VERSION "HINBNNNYYNNNYYNNNNNNNNNNNNYNNNYYYNNYNNNNNN/4//%%/4/'%**4NNN///"

NS_ :

BS_:

BU_: VirtualNMTMaster PVC BMS_Battery_1 TMS Inverter
VAL_TABLE_ PVC_Statusword 7 "FORWARD_DISABLE" 6 "CONT_CLOSE" 5 "CONT_OPEN" 4 "DISCHARGE" 3 "PRECHARGE" 2 "ESTOPWAIT" 1 "MC_ON" 0 "MC_OFF" ;

BO_ 1813 HBGuard_021: 1 BMS_Battery_1
 SG_ Toggle : 7|1@1+ (1,0) [0|0] "" Vector__XXX
 SG_ State : 0|7@1+ (1,0) [0|0] "" Vector__XXX

BO_ 1429 SSDO_021: 8 BMS_Battery_1
 SG_ SCS M : 5|3@1+ (1,0) [0|6] "" Vector__XXX

BO_ 1557 CSDO_021: 8 Vector__XXX
 SG_ CCS M : 5|3@1+ (1,0) [0|6] ""  BMS_Battery_1

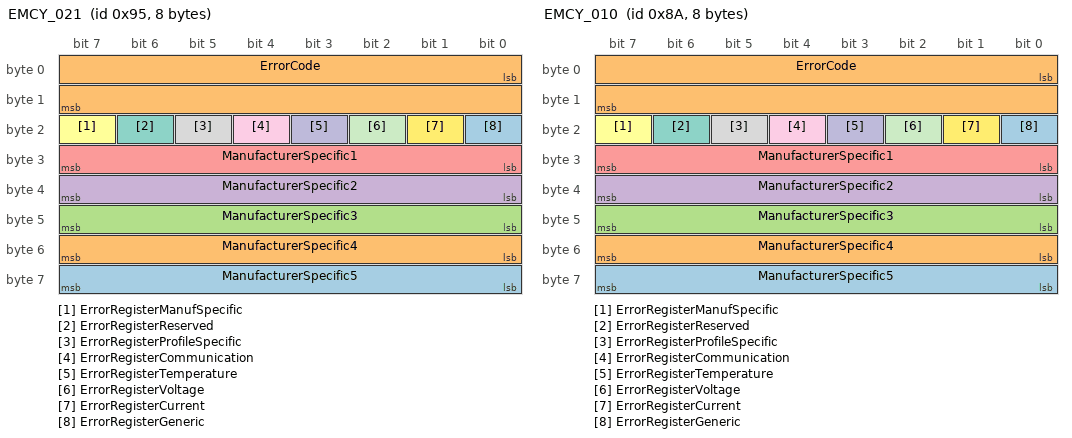
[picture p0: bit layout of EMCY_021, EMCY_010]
BO_ 149 EMCY_021: 8 BMS_Battery_1
 SG_ ManufacturerSpecific5 : 56|8@1+ (1,0) [0|0] "" Vector__XXX
 SG_ ManufacturerSpecific4 : 48|8@1+ (1,0) [0|0] "" Vector__XXX
 SG_ ManufacturerSpecific3 : 40|8@1+ (1,0) [0|0] "" Vector__XXX
 SG_ ManufacturerSpecific2 : 32|8@1+ (1,0) [0|0] "" Vector__XXX
 SG_ ManufacturerSpecific1 : 24|8@1+ (1,0) [0|0] "" Vector__XXX
 SG_ ErrorRegisterManufSpecific : 23|1@1+ (1,0) [0|0] "" Vector__XXX
 SG_ ErrorRegisterReserved : 22|1@1+ (1,0) [0|0] "" Vector__XXX
 SG_ ErrorRegisterProfileSpecific : 21|1@1+ (1,0) [0|0] "" Vector__XXX
 SG_ ErrorRegisterCommunication : 20|1@1+ (1,0) [0|0] "" Vector__XXX
 SG_ ErrorRegisterTemperature : 19|1@1+ (1,0) [0|0] "" Vector__XXX
 SG_ ErrorRegisterVoltage : 18|1@1+ (1,0) [0|0] "" Vector__XXX
 SG_ ErrorRegisterCurrent : 17|1@1+ (1,0) [0|0] "" Vector__XXX
 SG_ ErrorRegisterGeneric : 16|1@1+ (1,0) [0|0] "" Vector__XXX
 SG_ ErrorCode : 0|16@1+ (1,0) [0|0] "" Vector__XXX

BO_ 1802 HBGuard_010: 1 PVC
 SG_ Toggle : 7|1@1+ (1,0) [0|0] "" Vector__XXX
 SG_ State : 0|7@1+ (1,0) [0|0] "" Vector__XXX

BO_ 1418 SSDO_010: 8 PVC
 SG_ SCS M : 5|3@1+ (1,0) [0|6] "" Vector__XXX

BO_ 1546 CSDO_010: 8 Vector__XXX
 SG_ CCS M : 5|3@1+ (1,0) [0|6] ""  PVC

BO_ 138 EMCY_010: 8 PVC
 SG_ ManufacturerSpecific5 : 56|8@1+ (1,0) [0|0] "" Vector__XXX
 SG_ ManufacturerSpecific4 : 48|8@1+ (1,0) [0|0] "" Vector__XXX
 SG_ ManufacturerSpecific3 : 40|8@1+ (1,0) [0|0] "" Vector__XXX
 SG_ ManufacturerSpecific2 : 32|8@1+ (1,0) [0|0] "" Vector__XXX
 SG_ ManufacturerSpecific1 : 24|8@1+ (1,0) [0|0] "" Vector__XXX
 SG_ ErrorRegisterManufSpecific : 23|1@1+ (1,0) [0|0] "" Vector__XXX
 SG_ ErrorRegisterReserved : 22|1@1+ (1,0) [0|0] "" Vector__XXX
 SG_ ErrorRegisterProfileSpecific : 21|1@1+ (1,0) [0|0] "" Vector__XXX
 SG_ ErrorRegisterCommunication : 20|1@1+ (1,0) [0|0] "" Vector__XXX
 SG_ ErrorRegisterTemperature : 19|1@1+ (1,0) [0|0] "" Vector__XXX
 SG_ ErrorRegisterVoltage : 18|1@1+ (1,0) [0|0] "" Vector__XXX
 SG_ ErrorRegisterCurrent : 17|1@1+ (1,0) [0|0] "" Vector__XXX
 SG_ ErrorRegisterGeneric : 16|1@1+ (1,0) [0|0] "" Vector__XXX
 SG_ ErrorCode : 0|16@1+ (1,0) [0|0] "" Vector__XXX

BO_ 1800 HBGuard_008: 1 TMS
 SG_ Toggle : 7|1@1+ (1,0) [0|0] "" Vector__XXX
 SG_ State : 0|7@1+ (1,0) [0|0] "" Vector__XXX

BO_ 1416 SSDO_008: 8 TMS
 SG_ SCS M : 5|3@1+ (1,0) [0|6] "" Vector__XXX

BO_ 1544 CSDO_008: 8 Vector__XXX
 SG_ CCS M : 5|3@1+ (1,0) [0|6] ""  TMS

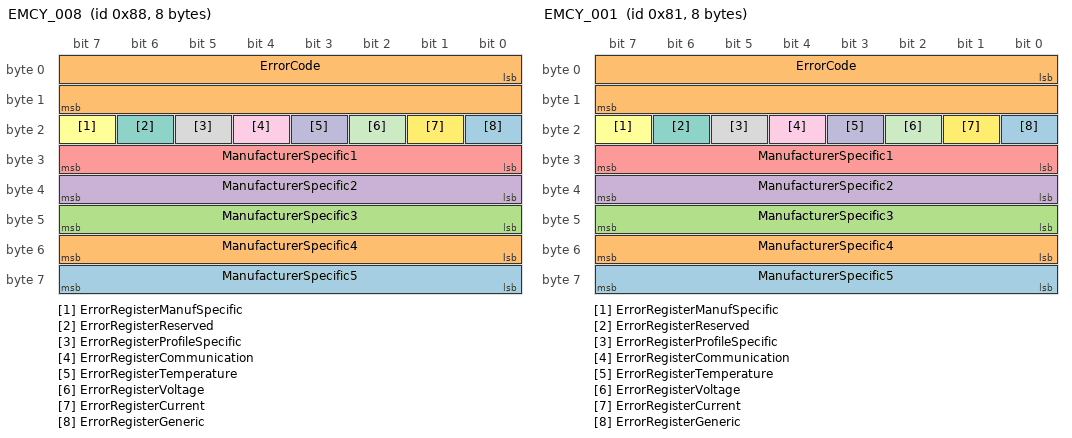
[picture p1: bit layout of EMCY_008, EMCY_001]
BO_ 136 EMCY_008: 8 TMS
 SG_ ManufacturerSpecific5 : 56|8@1+ (1,0) [0|0] "" Vector__XXX
 SG_ ManufacturerSpecific4 : 48|8@1+ (1,0) [0|0] "" Vector__XXX
 SG_ ManufacturerSpecific3 : 40|8@1+ (1,0) [0|0] "" Vector__XXX
 SG_ ManufacturerSpecific2 : 32|8@1+ (1,0) [0|0] "" Vector__XXX
 SG_ ManufacturerSpecific1 : 24|8@1+ (1,0) [0|0] "" Vector__XXX
 SG_ ErrorRegisterManufSpecific : 23|1@1+ (1,0) [0|0] "" Vector__XXX
 SG_ ErrorRegisterReserved : 22|1@1+ (1,0) [0|0] "" Vector__XXX
 SG_ ErrorRegisterProfileSpecific : 21|1@1+ (1,0) [0|0] "" Vector__XXX
 SG_ ErrorRegisterCommunication : 20|1@1+ (1,0) [0|0] "" Vector__XXX
 SG_ ErrorRegisterTemperature : 19|1@1+ (1,0) [0|0] "" Vector__XXX
 SG_ ErrorRegisterVoltage : 18|1@1+ (1,0) [0|0] "" Vector__XXX
 SG_ ErrorRegisterCurrent : 17|1@1+ (1,0) [0|0] "" Vector__XXX
 SG_ ErrorRegisterGeneric : 16|1@1+ (1,0) [0|0] "" Vector__XXX
 SG_ ErrorCode : 0|16@1+ (1,0) [0|0] "" Vector__XXX

BO_ 1793 HBGuard_001: 1 Inverter
 SG_ Toggle : 7|1@1+ (1,0) [0|0] "" Vector__XXX
 SG_ State : 0|7@1+ (1,0) [0|0] "" Vector__XXX

BO_ 1409 SSDO_001: 8 Inverter
 SG_ SCS M : 5|3@1+ (1,0) [0|6] "" Vector__XXX

BO_ 1537 CSDO_001: 8 Vector__XXX
 SG_ CCS M : 5|3@1+ (1,0) [0|6] ""  Inverter

BO_ 129 EMCY_001: 8 Inverter
 SG_ ManufacturerSpecific5 : 56|8@1+ (1,0) [0|0] "" Vector__XXX
 SG_ ManufacturerSpecific4 : 48|8@1+ (1,0) [0|0] "" Vector__XXX
 SG_ ManufacturerSpecific3 : 40|8@1+ (1,0) [0|0] "" Vector__XXX
 SG_ ManufacturerSpecific2 : 32|8@1+ (1,0) [0|0] "" Vector__XXX
 SG_ ManufacturerSpecific1 : 24|8@1+ (1,0) [0|0] "" Vector__XXX
 SG_ ErrorRegisterManufSpecific : 23|1@1+ (1,0) [0|0] "" Vector__XXX
 SG_ ErrorRegisterReserved : 22|1@1+ (1,0) [0|0] "" Vector__XXX
 SG_ ErrorRegisterProfileSpecific : 21|1@1+ (1,0) [0|0] "" Vector__XXX
 SG_ ErrorRegisterCommunication : 20|1@1+ (1,0) [0|0] "" Vector__XXX
 SG_ ErrorRegisterTemperature : 19|1@1+ (1,0) [0|0] "" Vector__XXX
 SG_ ErrorRegisterVoltage : 18|1@1+ (1,0) [0|0] "" Vector__XXX
 SG_ ErrorRegisterCurrent : 17|1@1+ (1,0) [0|0] "" Vector__XXX
 SG_ ErrorRegisterGeneric : 16|1@1+ (1,0) [0|0] "" Vector__XXX
 SG_ ErrorCode : 0|16@1+ (1,0) [0|0] "" Vector__XXX

BO_ 1919 HBGuard_127: 1 Vector__XXX
 SG_ Toggle : 7|1@1+ (1,0) [0|0] "" Vector__XXX
 SG_ State : 0|7@1+ (1,0) [0|0] "" Vector__XXX

BO_ 1535 SSDO_127: 8 Vector__XXX

BO_ 1663 CSDO_127: 8 Vector__XXX

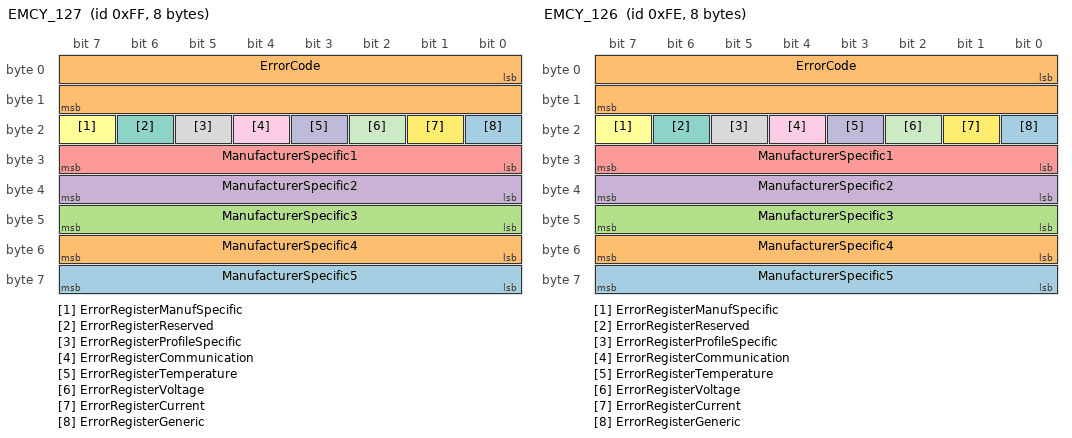
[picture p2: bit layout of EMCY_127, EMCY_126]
BO_ 255 EMCY_127: 8 Vector__XXX
 SG_ ManufacturerSpecific5 : 56|8@1+ (1,0) [0|0] "" Vector__XXX
 SG_ ManufacturerSpecific4 : 48|8@1+ (1,0) [0|0] "" Vector__XXX
 SG_ ManufacturerSpecific3 : 40|8@1+ (1,0) [0|0] "" Vector__XXX
 SG_ ManufacturerSpecific2 : 32|8@1+ (1,0) [0|0] "" Vector__XXX
 SG_ ManufacturerSpecific1 : 24|8@1+ (1,0) [0|0] "" Vector__XXX
 SG_ ErrorRegisterManufSpecific : 23|1@1+ (1,0) [0|0] "" Vector__XXX
 SG_ ErrorRegisterReserved : 22|1@1+ (1,0) [0|0] "" Vector__XXX
 SG_ ErrorRegisterProfileSpecific : 21|1@1+ (1,0) [0|0] "" Vector__XXX
 SG_ ErrorRegisterCommunication : 20|1@1+ (1,0) [0|0] "" Vector__XXX
 SG_ ErrorRegisterTemperature : 19|1@1+ (1,0) [0|0] "" Vector__XXX
 SG_ ErrorRegisterVoltage : 18|1@1+ (1,0) [0|0] "" Vector__XXX
 SG_ ErrorRegisterCurrent : 17|1@1+ (1,0) [0|0] "" Vector__XXX
 SG_ ErrorRegisterGeneric : 16|1@1+ (1,0) [0|0] "" Vector__XXX
 SG_ ErrorCode : 0|16@1+ (1,0) [0|0] "" Vector__XXX

BO_ 1918 HBGuard_126: 1 Vector__XXX
 SG_ Toggle : 7|1@1+ (1,0) [0|0] "" Vector__XXX
 SG_ State : 0|7@1+ (1,0) [0|0] "" Vector__XXX

BO_ 1534 SSDO_126: 8 Vector__XXX

BO_ 1662 CSDO_126: 8 Vector__XXX

BO_ 254 EMCY_126: 8 Vector__XXX
 SG_ ManufacturerSpecific5 : 56|8@1+ (1,0) [0|0] "" Vector__XXX
 SG_ ManufacturerSpecific4 : 48|8@1+ (1,0) [0|0] "" Vector__XXX
 SG_ ManufacturerSpecific3 : 40|8@1+ (1,0) [0|0] "" Vector__XXX
 SG_ ManufacturerSpecific2 : 32|8@1+ (1,0) [0|0] "" Vector__XXX
 SG_ ManufacturerSpecific1 : 24|8@1+ (1,0) [0|0] "" Vector__XXX
 SG_ ErrorRegisterManufSpecific : 23|1@1+ (1,0) [0|0] "" Vector__XXX
 SG_ ErrorRegisterReserved : 22|1@1+ (1,0) [0|0] "" Vector__XXX
 SG_ ErrorRegisterProfileSpecific : 21|1@1+ (1,0) [0|0] "" Vector__XXX
 SG_ ErrorRegisterCommunication : 20|1@1+ (1,0) [0|0] "" Vector__XXX
 SG_ ErrorRegisterTemperature : 19|1@1+ (1,0) [0|0] "" Vector__XXX
 SG_ ErrorRegisterVoltage : 18|1@1+ (1,0) [0|0] "" Vector__XXX
 SG_ ErrorRegisterCurrent : 17|1@1+ (1,0) [0|0] "" Vector__XXX
 SG_ ErrorRegisterGeneric : 16|1@1+ (1,0) [0|0] "" Vector__XXX
 SG_ ErrorCode : 0|16@1+ (1,0) [0|0] "" Vector__XXX

BO_ 1917 HBGuard_125: 1 Vector__XXX
 SG_ Toggle : 7|1@1+ (1,0) [0|0] "" Vector__XXX
 SG_ State : 0|7@1+ (1,0) [0|0] "" Vector__XXX

BO_ 1533 SSDO_125: 8 Vector__XXX

BO_ 1661 CSDO_125: 8 Vector__XXX

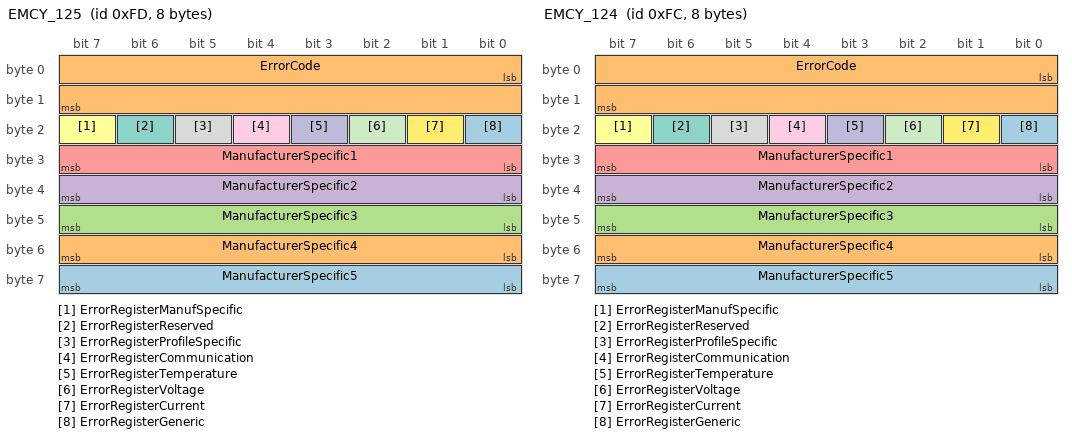
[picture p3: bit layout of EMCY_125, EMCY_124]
BO_ 253 EMCY_125: 8 Vector__XXX
 SG_ ManufacturerSpecific5 : 56|8@1+ (1,0) [0|0] "" Vector__XXX
 SG_ ManufacturerSpecific4 : 48|8@1+ (1,0) [0|0] "" Vector__XXX
 SG_ ManufacturerSpecific3 : 40|8@1+ (1,0) [0|0] "" Vector__XXX
 SG_ ManufacturerSpecific2 : 32|8@1+ (1,0) [0|0] "" Vector__XXX
 SG_ ManufacturerSpecific1 : 24|8@1+ (1,0) [0|0] "" Vector__XXX
 SG_ ErrorRegisterManufSpecific : 23|1@1+ (1,0) [0|0] "" Vector__XXX
 SG_ ErrorRegisterReserved : 22|1@1+ (1,0) [0|0] "" Vector__XXX
 SG_ ErrorRegisterProfileSpecific : 21|1@1+ (1,0) [0|0] "" Vector__XXX
 SG_ ErrorRegisterCommunication : 20|1@1+ (1,0) [0|0] "" Vector__XXX
 SG_ ErrorRegisterTemperature : 19|1@1+ (1,0) [0|0] "" Vector__XXX
 SG_ ErrorRegisterVoltage : 18|1@1+ (1,0) [0|0] "" Vector__XXX
 SG_ ErrorRegisterCurrent : 17|1@1+ (1,0) [0|0] "" Vector__XXX
 SG_ ErrorRegisterGeneric : 16|1@1+ (1,0) [0|0] "" Vector__XXX
 SG_ ErrorCode : 0|16@1+ (1,0) [0|0] "" Vector__XXX

BO_ 1916 HBGuard_124: 1 Vector__XXX
 SG_ Toggle : 7|1@1+ (1,0) [0|0] "" Vector__XXX
 SG_ State : 0|7@1+ (1,0) [0|0] "" Vector__XXX

BO_ 1532 SSDO_124: 8 Vector__XXX

BO_ 1660 CSDO_124: 8 Vector__XXX

BO_ 252 EMCY_124: 8 Vector__XXX
 SG_ ManufacturerSpecific5 : 56|8@1+ (1,0) [0|0] "" Vector__XXX
 SG_ ManufacturerSpecific4 : 48|8@1+ (1,0) [0|0] "" Vector__XXX
 SG_ ManufacturerSpecific3 : 40|8@1+ (1,0) [0|0] "" Vector__XXX
 SG_ ManufacturerSpecific2 : 32|8@1+ (1,0) [0|0] "" Vector__XXX
 SG_ ManufacturerSpecific1 : 24|8@1+ (1,0) [0|0] "" Vector__XXX
 SG_ ErrorRegisterManufSpecific : 23|1@1+ (1,0) [0|0] "" Vector__XXX
 SG_ ErrorRegisterReserved : 22|1@1+ (1,0) [0|0] "" Vector__XXX
 SG_ ErrorRegisterProfileSpecific : 21|1@1+ (1,0) [0|0] "" Vector__XXX
 SG_ ErrorRegisterCommunication : 20|1@1+ (1,0) [0|0] "" Vector__XXX
 SG_ ErrorRegisterTemperature : 19|1@1+ (1,0) [0|0] "" Vector__XXX
 SG_ ErrorRegisterVoltage : 18|1@1+ (1,0) [0|0] "" Vector__XXX
 SG_ ErrorRegisterCurrent : 17|1@1+ (1,0) [0|0] "" Vector__XXX
 SG_ ErrorRegisterGeneric : 16|1@1+ (1,0) [0|0] "" Vector__XXX
 SG_ ErrorCode : 0|16@1+ (1,0) [0|0] "" Vector__XXX

BO_ 1915 HBGuard_123: 1 Vector__XXX
 SG_ Toggle : 7|1@1+ (1,0) [0|0] "" Vector__XXX
 SG_ State : 0|7@1+ (1,0) [0|0] "" Vector__XXX

BO_ 1531 SSDO_123: 8 Vector__XXX

BO_ 1659 CSDO_123: 8 Vector__XXX

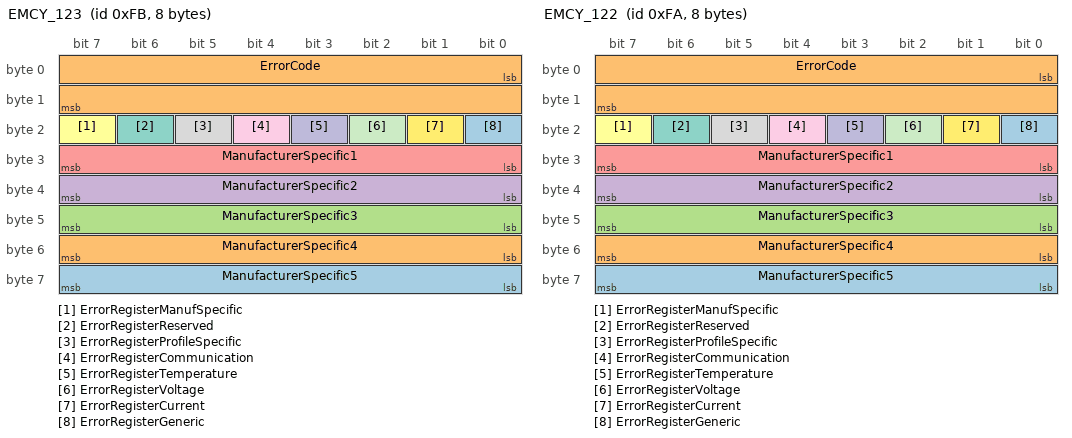
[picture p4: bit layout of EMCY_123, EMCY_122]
BO_ 251 EMCY_123: 8 Vector__XXX
 SG_ ManufacturerSpecific5 : 56|8@1+ (1,0) [0|0] "" Vector__XXX
 SG_ ManufacturerSpecific4 : 48|8@1+ (1,0) [0|0] "" Vector__XXX
 SG_ ManufacturerSpecific3 : 40|8@1+ (1,0) [0|0] "" Vector__XXX
 SG_ ManufacturerSpecific2 : 32|8@1+ (1,0) [0|0] "" Vector__XXX
 SG_ ManufacturerSpecific1 : 24|8@1+ (1,0) [0|0] "" Vector__XXX
 SG_ ErrorRegisterManufSpecific : 23|1@1+ (1,0) [0|0] "" Vector__XXX
 SG_ ErrorRegisterReserved : 22|1@1+ (1,0) [0|0] "" Vector__XXX
 SG_ ErrorRegisterProfileSpecific : 21|1@1+ (1,0) [0|0] "" Vector__XXX
 SG_ ErrorRegisterCommunication : 20|1@1+ (1,0) [0|0] "" Vector__XXX
 SG_ ErrorRegisterTemperature : 19|1@1+ (1,0) [0|0] "" Vector__XXX
 SG_ ErrorRegisterVoltage : 18|1@1+ (1,0) [0|0] "" Vector__XXX
 SG_ ErrorRegisterCurrent : 17|1@1+ (1,0) [0|0] "" Vector__XXX
 SG_ ErrorRegisterGeneric : 16|1@1+ (1,0) [0|0] "" Vector__XXX
 SG_ ErrorCode : 0|16@1+ (1,0) [0|0] "" Vector__XXX

BO_ 1914 HBGuard_122: 1 Vector__XXX
 SG_ Toggle : 7|1@1+ (1,0) [0|0] "" Vector__XXX
 SG_ State : 0|7@1+ (1,0) [0|0] "" Vector__XXX

BO_ 1530 SSDO_122: 8 Vector__XXX

BO_ 1658 CSDO_122: 8 Vector__XXX

BO_ 250 EMCY_122: 8 Vector__XXX
 SG_ ManufacturerSpecific5 : 56|8@1+ (1,0) [0|0] "" Vector__XXX
 SG_ ManufacturerSpecific4 : 48|8@1+ (1,0) [0|0] "" Vector__XXX
 SG_ ManufacturerSpecific3 : 40|8@1+ (1,0) [0|0] "" Vector__XXX
 SG_ ManufacturerSpecific2 : 32|8@1+ (1,0) [0|0] "" Vector__XXX
 SG_ ManufacturerSpecific1 : 24|8@1+ (1,0) [0|0] "" Vector__XXX
 SG_ ErrorRegisterManufSpecific : 23|1@1+ (1,0) [0|0] "" Vector__XXX
 SG_ ErrorRegisterReserved : 22|1@1+ (1,0) [0|0] "" Vector__XXX
 SG_ ErrorRegisterProfileSpecific : 21|1@1+ (1,0) [0|0] "" Vector__XXX
 SG_ ErrorRegisterCommunication : 20|1@1+ (1,0) [0|0] "" Vector__XXX
 SG_ ErrorRegisterTemperature : 19|1@1+ (1,0) [0|0] "" Vector__XXX
 SG_ ErrorRegisterVoltage : 18|1@1+ (1,0) [0|0] "" Vector__XXX
 SG_ ErrorRegisterCurrent : 17|1@1+ (1,0) [0|0] "" Vector__XXX
 SG_ ErrorRegisterGeneric : 16|1@1+ (1,0) [0|0] "" Vector__XXX
 SG_ ErrorCode : 0|16@1+ (1,0) [0|0] "" Vector__XXX

BO_ 1913 HBGuard_121: 1 Vector__XXX
 SG_ Toggle : 7|1@1+ (1,0) [0|0] "" Vector__XXX
 SG_ State : 0|7@1+ (1,0) [0|0] "" Vector__XXX

BO_ 1529 SSDO_121: 8 Vector__XXX

BO_ 1657 CSDO_121: 8 Vector__XXX

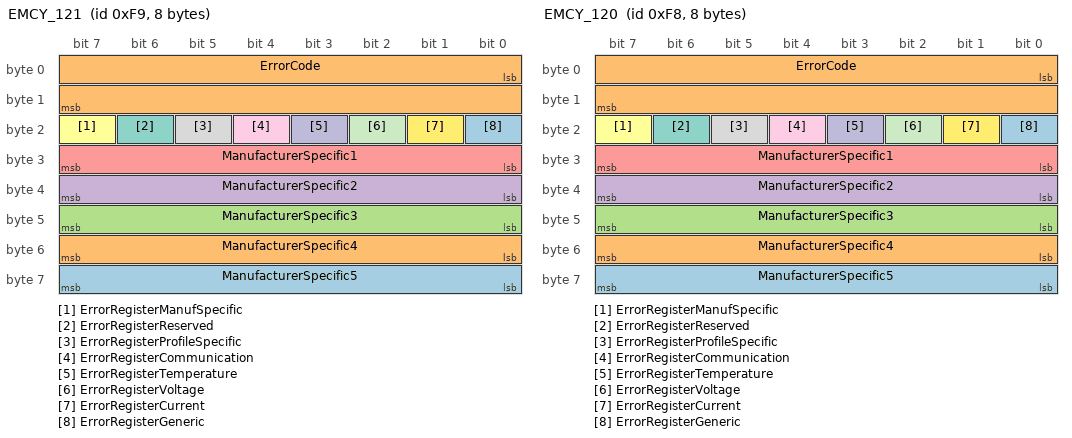
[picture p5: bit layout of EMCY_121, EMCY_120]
BO_ 249 EMCY_121: 8 Vector__XXX
 SG_ ManufacturerSpecific5 : 56|8@1+ (1,0) [0|0] "" Vector__XXX
 SG_ ManufacturerSpecific4 : 48|8@1+ (1,0) [0|0] "" Vector__XXX
 SG_ ManufacturerSpecific3 : 40|8@1+ (1,0) [0|0] "" Vector__XXX
 SG_ ManufacturerSpecific2 : 32|8@1+ (1,0) [0|0] "" Vector__XXX
 SG_ ManufacturerSpecific1 : 24|8@1+ (1,0) [0|0] "" Vector__XXX
 SG_ ErrorRegisterManufSpecific : 23|1@1+ (1,0) [0|0] "" Vector__XXX
 SG_ ErrorRegisterReserved : 22|1@1+ (1,0) [0|0] "" Vector__XXX
 SG_ ErrorRegisterProfileSpecific : 21|1@1+ (1,0) [0|0] "" Vector__XXX
 SG_ ErrorRegisterCommunication : 20|1@1+ (1,0) [0|0] "" Vector__XXX
 SG_ ErrorRegisterTemperature : 19|1@1+ (1,0) [0|0] "" Vector__XXX
 SG_ ErrorRegisterVoltage : 18|1@1+ (1,0) [0|0] "" Vector__XXX
 SG_ ErrorRegisterCurrent : 17|1@1+ (1,0) [0|0] "" Vector__XXX
 SG_ ErrorRegisterGeneric : 16|1@1+ (1,0) [0|0] "" Vector__XXX
 SG_ ErrorCode : 0|16@1+ (1,0) [0|0] "" Vector__XXX

BO_ 1912 HBGuard_120: 1 Vector__XXX
 SG_ Toggle : 7|1@1+ (1,0) [0|0] "" Vector__XXX
 SG_ State : 0|7@1+ (1,0) [0|0] "" Vector__XXX

BO_ 1528 SSDO_120: 8 Vector__XXX

BO_ 1656 CSDO_120: 8 Vector__XXX

BO_ 248 EMCY_120: 8 Vector__XXX
 SG_ ManufacturerSpecific5 : 56|8@1+ (1,0) [0|0] "" Vector__XXX
 SG_ ManufacturerSpecific4 : 48|8@1+ (1,0) [0|0] "" Vector__XXX
 SG_ ManufacturerSpecific3 : 40|8@1+ (1,0) [0|0] "" Vector__XXX
 SG_ ManufacturerSpecific2 : 32|8@1+ (1,0) [0|0] "" Vector__XXX
 SG_ ManufacturerSpecific1 : 24|8@1+ (1,0) [0|0] "" Vector__XXX
 SG_ ErrorRegisterManufSpecific : 23|1@1+ (1,0) [0|0] "" Vector__XXX
 SG_ ErrorRegisterReserved : 22|1@1+ (1,0) [0|0] "" Vector__XXX
 SG_ ErrorRegisterProfileSpecific : 21|1@1+ (1,0) [0|0] "" Vector__XXX
 SG_ ErrorRegisterCommunication : 20|1@1+ (1,0) [0|0] "" Vector__XXX
 SG_ ErrorRegisterTemperature : 19|1@1+ (1,0) [0|0] "" Vector__XXX
 SG_ ErrorRegisterVoltage : 18|1@1+ (1,0) [0|0] "" Vector__XXX
 SG_ ErrorRegisterCurrent : 17|1@1+ (1,0) [0|0] "" Vector__XXX
 SG_ ErrorRegisterGeneric : 16|1@1+ (1,0) [0|0] "" Vector__XXX
 SG_ ErrorCode : 0|16@1+ (1,0) [0|0] "" Vector__XXX

BO_ 1911 HBGuard_119: 1 Vector__XXX
 SG_ Toggle : 7|1@1+ (1,0) [0|0] "" Vector__XXX
 SG_ State : 0|7@1+ (1,0) [0|0] "" Vector__XXX

BO_ 1527 SSDO_119: 8 Vector__XXX

BO_ 1655 CSDO_119: 8 Vector__XXX

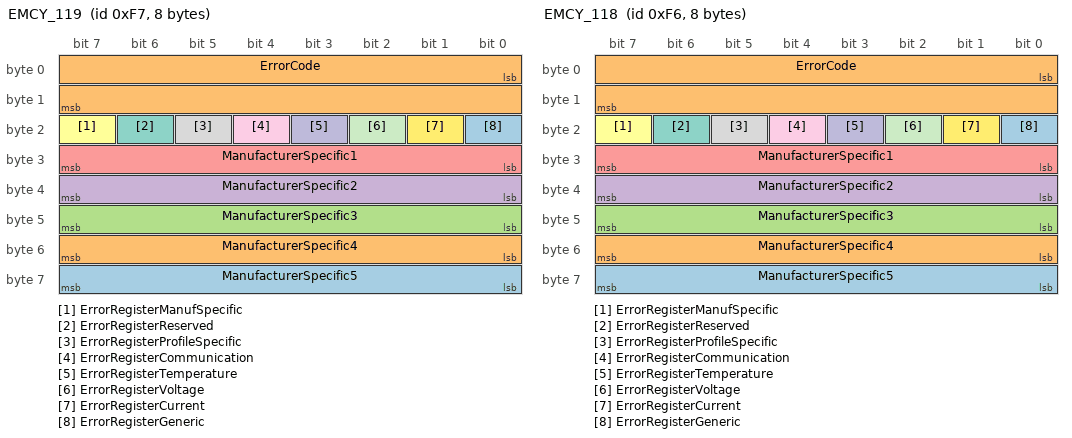
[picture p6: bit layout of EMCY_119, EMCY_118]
BO_ 247 EMCY_119: 8 Vector__XXX
 SG_ ManufacturerSpecific5 : 56|8@1+ (1,0) [0|0] "" Vector__XXX
 SG_ ManufacturerSpecific4 : 48|8@1+ (1,0) [0|0] "" Vector__XXX
 SG_ ManufacturerSpecific3 : 40|8@1+ (1,0) [0|0] "" Vector__XXX
 SG_ ManufacturerSpecific2 : 32|8@1+ (1,0) [0|0] "" Vector__XXX
 SG_ ManufacturerSpecific1 : 24|8@1+ (1,0) [0|0] "" Vector__XXX
 SG_ ErrorRegisterManufSpecific : 23|1@1+ (1,0) [0|0] "" Vector__XXX
 SG_ ErrorRegisterReserved : 22|1@1+ (1,0) [0|0] "" Vector__XXX
 SG_ ErrorRegisterProfileSpecific : 21|1@1+ (1,0) [0|0] "" Vector__XXX
 SG_ ErrorRegisterCommunication : 20|1@1+ (1,0) [0|0] "" Vector__XXX
 SG_ ErrorRegisterTemperature : 19|1@1+ (1,0) [0|0] "" Vector__XXX
 SG_ ErrorRegisterVoltage : 18|1@1+ (1,0) [0|0] "" Vector__XXX
 SG_ ErrorRegisterCurrent : 17|1@1+ (1,0) [0|0] "" Vector__XXX
 SG_ ErrorRegisterGeneric : 16|1@1+ (1,0) [0|0] "" Vector__XXX
 SG_ ErrorCode : 0|16@1+ (1,0) [0|0] "" Vector__XXX

BO_ 1910 HBGuard_118: 1 Vector__XXX
 SG_ Toggle : 7|1@1+ (1,0) [0|0] "" Vector__XXX
 SG_ State : 0|7@1+ (1,0) [0|0] "" Vector__XXX

BO_ 1526 SSDO_118: 8 Vector__XXX

BO_ 1654 CSDO_118: 8 Vector__XXX

BO_ 246 EMCY_118: 8 Vector__XXX
 SG_ ManufacturerSpecific5 : 56|8@1+ (1,0) [0|0] "" Vector__XXX
 SG_ ManufacturerSpecific4 : 48|8@1+ (1,0) [0|0] "" Vector__XXX
 SG_ ManufacturerSpecific3 : 40|8@1+ (1,0) [0|0] "" Vector__XXX
 SG_ ManufacturerSpecific2 : 32|8@1+ (1,0) [0|0] "" Vector__XXX
 SG_ ManufacturerSpecific1 : 24|8@1+ (1,0) [0|0] "" Vector__XXX
 SG_ ErrorRegisterManufSpecific : 23|1@1+ (1,0) [0|0] "" Vector__XXX
 SG_ ErrorRegisterReserved : 22|1@1+ (1,0) [0|0] "" Vector__XXX
 SG_ ErrorRegisterProfileSpecific : 21|1@1+ (1,0) [0|0] "" Vector__XXX
 SG_ ErrorRegisterCommunication : 20|1@1+ (1,0) [0|0] "" Vector__XXX
 SG_ ErrorRegisterTemperature : 19|1@1+ (1,0) [0|0] "" Vector__XXX
 SG_ ErrorRegisterVoltage : 18|1@1+ (1,0) [0|0] "" Vector__XXX
 SG_ ErrorRegisterCurrent : 17|1@1+ (1,0) [0|0] "" Vector__XXX
 SG_ ErrorRegisterGeneric : 16|1@1+ (1,0) [0|0] "" Vector__XXX
 SG_ ErrorCode : 0|16@1+ (1,0) [0|0] "" Vector__XXX

BO_ 1909 HBGuard_117: 1 Vector__XXX
 SG_ Toggle : 7|1@1+ (1,0) [0|0] "" Vector__XXX
 SG_ State : 0|7@1+ (1,0) [0|0] "" Vector__XXX

BO_ 1525 SSDO_117: 8 Vector__XXX

BO_ 1653 CSDO_117: 8 Vector__XXX

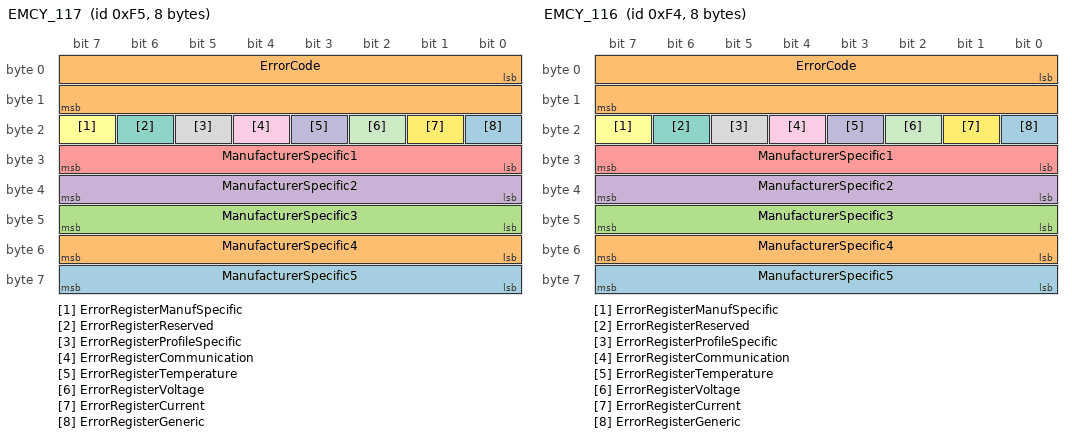
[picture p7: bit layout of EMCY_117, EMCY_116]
BO_ 245 EMCY_117: 8 Vector__XXX
 SG_ ManufacturerSpecific5 : 56|8@1+ (1,0) [0|0] "" Vector__XXX
 SG_ ManufacturerSpecific4 : 48|8@1+ (1,0) [0|0] "" Vector__XXX
 SG_ ManufacturerSpecific3 : 40|8@1+ (1,0) [0|0] "" Vector__XXX
 SG_ ManufacturerSpecific2 : 32|8@1+ (1,0) [0|0] "" Vector__XXX
 SG_ ManufacturerSpecific1 : 24|8@1+ (1,0) [0|0] "" Vector__XXX
 SG_ ErrorRegisterManufSpecific : 23|1@1+ (1,0) [0|0] "" Vector__XXX
 SG_ ErrorRegisterReserved : 22|1@1+ (1,0) [0|0] "" Vector__XXX
 SG_ ErrorRegisterProfileSpecific : 21|1@1+ (1,0) [0|0] "" Vector__XXX
 SG_ ErrorRegisterCommunication : 20|1@1+ (1,0) [0|0] "" Vector__XXX
 SG_ ErrorRegisterTemperature : 19|1@1+ (1,0) [0|0] "" Vector__XXX
 SG_ ErrorRegisterVoltage : 18|1@1+ (1,0) [0|0] "" Vector__XXX
 SG_ ErrorRegisterCurrent : 17|1@1+ (1,0) [0|0] "" Vector__XXX
 SG_ ErrorRegisterGeneric : 16|1@1+ (1,0) [0|0] "" Vector__XXX
 SG_ ErrorCode : 0|16@1+ (1,0) [0|0] "" Vector__XXX

BO_ 1908 HBGuard_116: 1 Vector__XXX
 SG_ Toggle : 7|1@1+ (1,0) [0|0] "" Vector__XXX
 SG_ State : 0|7@1+ (1,0) [0|0] "" Vector__XXX

BO_ 1524 SSDO_116: 8 Vector__XXX

BO_ 1652 CSDO_116: 8 Vector__XXX

BO_ 244 EMCY_116: 8 Vector__XXX
 SG_ ManufacturerSpecific5 : 56|8@1+ (1,0) [0|0] "" Vector__XXX
 SG_ ManufacturerSpecific4 : 48|8@1+ (1,0) [0|0] "" Vector__XXX
 SG_ ManufacturerSpecific3 : 40|8@1+ (1,0) [0|0] "" Vector__XXX
 SG_ ManufacturerSpecific2 : 32|8@1+ (1,0) [0|0] "" Vector__XXX
 SG_ ManufacturerSpecific1 : 24|8@1+ (1,0) [0|0] "" Vector__XXX
 SG_ ErrorRegisterManufSpecific : 23|1@1+ (1,0) [0|0] "" Vector__XXX
 SG_ ErrorRegisterReserved : 22|1@1+ (1,0) [0|0] "" Vector__XXX
 SG_ ErrorRegisterProfileSpecific : 21|1@1+ (1,0) [0|0] "" Vector__XXX
 SG_ ErrorRegisterCommunication : 20|1@1+ (1,0) [0|0] "" Vector__XXX
 SG_ ErrorRegisterTemperature : 19|1@1+ (1,0) [0|0] "" Vector__XXX
 SG_ ErrorRegisterVoltage : 18|1@1+ (1,0) [0|0] "" Vector__XXX
 SG_ ErrorRegisterCurrent : 17|1@1+ (1,0) [0|0] "" Vector__XXX
 SG_ ErrorRegisterGeneric : 16|1@1+ (1,0) [0|0] "" Vector__XXX
 SG_ ErrorCode : 0|16@1+ (1,0) [0|0] "" Vector__XXX

BO_ 1907 HBGuard_115: 1 Vector__XXX
 SG_ Toggle : 7|1@1+ (1,0) [0|0] "" Vector__XXX
 SG_ State : 0|7@1+ (1,0) [0|0] "" Vector__XXX

BO_ 1523 SSDO_115: 8 Vector__XXX

BO_ 1651 CSDO_115: 8 Vector__XXX

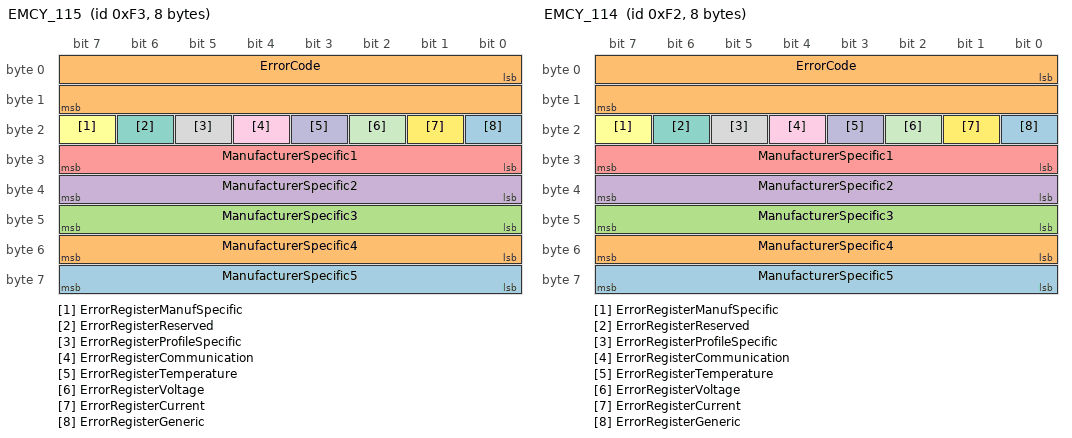
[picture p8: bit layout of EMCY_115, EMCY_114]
BO_ 243 EMCY_115: 8 Vector__XXX
 SG_ ManufacturerSpecific5 : 56|8@1+ (1,0) [0|0] "" Vector__XXX
 SG_ ManufacturerSpecific4 : 48|8@1+ (1,0) [0|0] "" Vector__XXX
 SG_ ManufacturerSpecific3 : 40|8@1+ (1,0) [0|0] "" Vector__XXX
 SG_ ManufacturerSpecific2 : 32|8@1+ (1,0) [0|0] "" Vector__XXX
 SG_ ManufacturerSpecific1 : 24|8@1+ (1,0) [0|0] "" Vector__XXX
 SG_ ErrorRegisterManufSpecific : 23|1@1+ (1,0) [0|0] "" Vector__XXX
 SG_ ErrorRegisterReserved : 22|1@1+ (1,0) [0|0] "" Vector__XXX
 SG_ ErrorRegisterProfileSpecific : 21|1@1+ (1,0) [0|0] "" Vector__XXX
 SG_ ErrorRegisterCommunication : 20|1@1+ (1,0) [0|0] "" Vector__XXX
 SG_ ErrorRegisterTemperature : 19|1@1+ (1,0) [0|0] "" Vector__XXX
 SG_ ErrorRegisterVoltage : 18|1@1+ (1,0) [0|0] "" Vector__XXX
 SG_ ErrorRegisterCurrent : 17|1@1+ (1,0) [0|0] "" Vector__XXX
 SG_ ErrorRegisterGeneric : 16|1@1+ (1,0) [0|0] "" Vector__XXX
 SG_ ErrorCode : 0|16@1+ (1,0) [0|0] "" Vector__XXX

BO_ 1906 HBGuard_114: 1 Vector__XXX
 SG_ Toggle : 7|1@1+ (1,0) [0|0] "" Vector__XXX
 SG_ State : 0|7@1+ (1,0) [0|0] "" Vector__XXX

BO_ 1522 SSDO_114: 8 Vector__XXX

BO_ 1650 CSDO_114: 8 Vector__XXX

BO_ 242 EMCY_114: 8 Vector__XXX
 SG_ ManufacturerSpecific5 : 56|8@1+ (1,0) [0|0] "" Vector__XXX
 SG_ ManufacturerSpecific4 : 48|8@1+ (1,0) [0|0] "" Vector__XXX
 SG_ ManufacturerSpecific3 : 40|8@1+ (1,0) [0|0] "" Vector__XXX
 SG_ ManufacturerSpecific2 : 32|8@1+ (1,0) [0|0] "" Vector__XXX
 SG_ ManufacturerSpecific1 : 24|8@1+ (1,0) [0|0] "" Vector__XXX
 SG_ ErrorRegisterManufSpecific : 23|1@1+ (1,0) [0|0] "" Vector__XXX
 SG_ ErrorRegisterReserved : 22|1@1+ (1,0) [0|0] "" Vector__XXX
 SG_ ErrorRegisterProfileSpecific : 21|1@1+ (1,0) [0|0] "" Vector__XXX
 SG_ ErrorRegisterCommunication : 20|1@1+ (1,0) [0|0] "" Vector__XXX
 SG_ ErrorRegisterTemperature : 19|1@1+ (1,0) [0|0] "" Vector__XXX
 SG_ ErrorRegisterVoltage : 18|1@1+ (1,0) [0|0] "" Vector__XXX
 SG_ ErrorRegisterCurrent : 17|1@1+ (1,0) [0|0] "" Vector__XXX
 SG_ ErrorRegisterGeneric : 16|1@1+ (1,0) [0|0] "" Vector__XXX
 SG_ ErrorCode : 0|16@1+ (1,0) [0|0] "" Vector__XXX

BO_ 1905 HBGuard_113: 1 Vector__XXX
 SG_ Toggle : 7|1@1+ (1,0) [0|0] "" Vector__XXX
 SG_ State : 0|7@1+ (1,0) [0|0] "" Vector__XXX

BO_ 1521 SSDO_113: 8 Vector__XXX

BO_ 1649 CSDO_113: 8 Vector__XXX

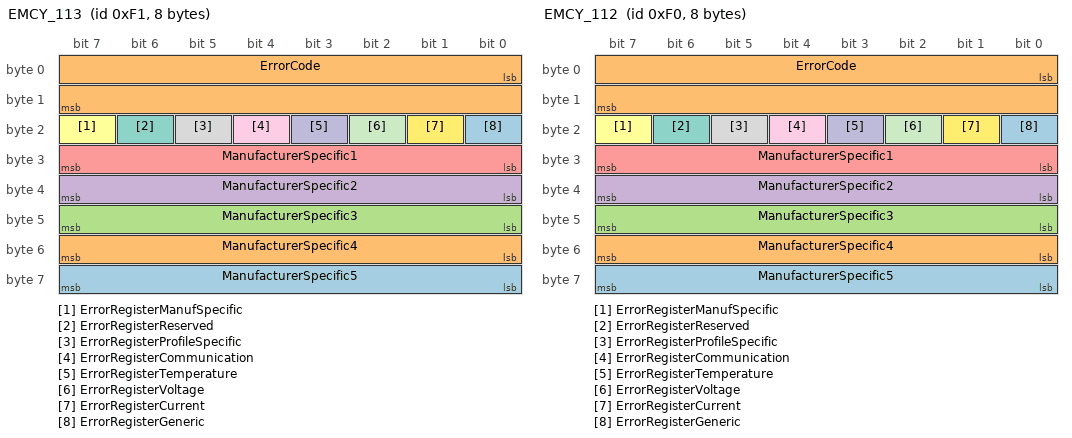
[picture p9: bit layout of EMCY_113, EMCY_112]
BO_ 241 EMCY_113: 8 Vector__XXX
 SG_ ManufacturerSpecific5 : 56|8@1+ (1,0) [0|0] "" Vector__XXX
 SG_ ManufacturerSpecific4 : 48|8@1+ (1,0) [0|0] "" Vector__XXX
 SG_ ManufacturerSpecific3 : 40|8@1+ (1,0) [0|0] "" Vector__XXX
 SG_ ManufacturerSpecific2 : 32|8@1+ (1,0) [0|0] "" Vector__XXX
 SG_ ManufacturerSpecific1 : 24|8@1+ (1,0) [0|0] "" Vector__XXX
 SG_ ErrorRegisterManufSpecific : 23|1@1+ (1,0) [0|0] "" Vector__XXX
 SG_ ErrorRegisterReserved : 22|1@1+ (1,0) [0|0] "" Vector__XXX
 SG_ ErrorRegisterProfileSpecific : 21|1@1+ (1,0) [0|0] "" Vector__XXX
 SG_ ErrorRegisterCommunication : 20|1@1+ (1,0) [0|0] "" Vector__XXX
 SG_ ErrorRegisterTemperature : 19|1@1+ (1,0) [0|0] "" Vector__XXX
 SG_ ErrorRegisterVoltage : 18|1@1+ (1,0) [0|0] "" Vector__XXX
 SG_ ErrorRegisterCurrent : 17|1@1+ (1,0) [0|0] "" Vector__XXX
 SG_ ErrorRegisterGeneric : 16|1@1+ (1,0) [0|0] "" Vector__XXX
 SG_ ErrorCode : 0|16@1+ (1,0) [0|0] "" Vector__XXX

BO_ 1904 HBGuard_112: 1 Vector__XXX
 SG_ Toggle : 7|1@1+ (1,0) [0|0] "" Vector__XXX
 SG_ State : 0|7@1+ (1,0) [0|0] "" Vector__XXX

BO_ 1520 SSDO_112: 8 Vector__XXX

BO_ 1648 CSDO_112: 8 Vector__XXX

BO_ 240 EMCY_112: 8 Vector__XXX
 SG_ ManufacturerSpecific5 : 56|8@1+ (1,0) [0|0] "" Vector__XXX
 SG_ ManufacturerSpecific4 : 48|8@1+ (1,0) [0|0] "" Vector__XXX
 SG_ ManufacturerSpecific3 : 40|8@1+ (1,0) [0|0] "" Vector__XXX
 SG_ ManufacturerSpecific2 : 32|8@1+ (1,0) [0|0] "" Vector__XXX
 SG_ ManufacturerSpecific1 : 24|8@1+ (1,0) [0|0] "" Vector__XXX
 SG_ ErrorRegisterManufSpecific : 23|1@1+ (1,0) [0|0] "" Vector__XXX
 SG_ ErrorRegisterReserved : 22|1@1+ (1,0) [0|0] "" Vector__XXX
 SG_ ErrorRegisterProfileSpecific : 21|1@1+ (1,0) [0|0] "" Vector__XXX
 SG_ ErrorRegisterCommunication : 20|1@1+ (1,0) [0|0] "" Vector__XXX
 SG_ ErrorRegisterTemperature : 19|1@1+ (1,0) [0|0] "" Vector__XXX
 SG_ ErrorRegisterVoltage : 18|1@1+ (1,0) [0|0] "" Vector__XXX
 SG_ ErrorRegisterCurrent : 17|1@1+ (1,0) [0|0] "" Vector__XXX
 SG_ ErrorRegisterGeneric : 16|1@1+ (1,0) [0|0] "" Vector__XXX
 SG_ ErrorCode : 0|16@1+ (1,0) [0|0] "" Vector__XXX

BO_ 1903 HBGuard_111: 1 Vector__XXX
 SG_ Toggle : 7|1@1+ (1,0) [0|0] "" Vector__XXX
 SG_ State : 0|7@1+ (1,0) [0|0] "" Vector__XXX

BO_ 1519 SSDO_111: 8 Vector__XXX

BO_ 1647 CSDO_111: 8 Vector__XXX

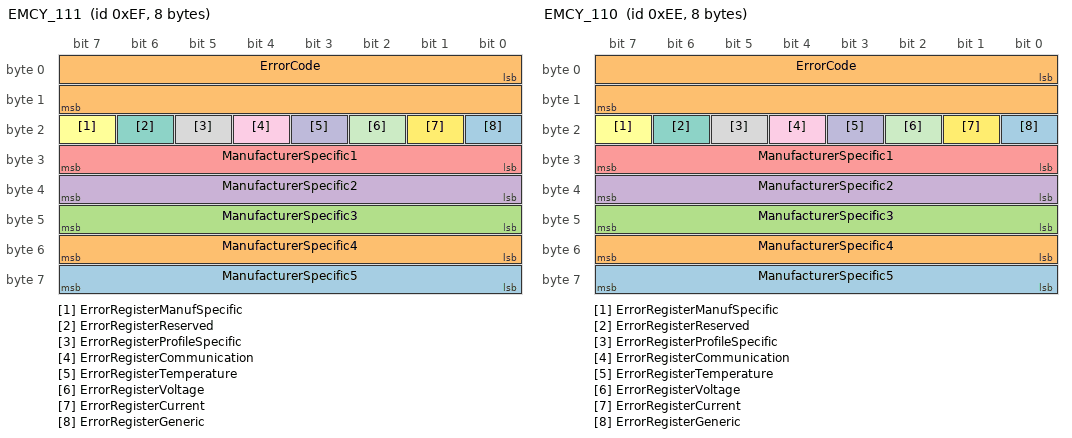
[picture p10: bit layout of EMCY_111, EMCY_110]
BO_ 239 EMCY_111: 8 Vector__XXX
 SG_ ManufacturerSpecific5 : 56|8@1+ (1,0) [0|0] "" Vector__XXX
 SG_ ManufacturerSpecific4 : 48|8@1+ (1,0) [0|0] "" Vector__XXX
 SG_ ManufacturerSpecific3 : 40|8@1+ (1,0) [0|0] "" Vector__XXX
 SG_ ManufacturerSpecific2 : 32|8@1+ (1,0) [0|0] "" Vector__XXX
 SG_ ManufacturerSpecific1 : 24|8@1+ (1,0) [0|0] "" Vector__XXX
 SG_ ErrorRegisterManufSpecific : 23|1@1+ (1,0) [0|0] "" Vector__XXX
 SG_ ErrorRegisterReserved : 22|1@1+ (1,0) [0|0] "" Vector__XXX
 SG_ ErrorRegisterProfileSpecific : 21|1@1+ (1,0) [0|0] "" Vector__XXX
 SG_ ErrorRegisterCommunication : 20|1@1+ (1,0) [0|0] "" Vector__XXX
 SG_ ErrorRegisterTemperature : 19|1@1+ (1,0) [0|0] "" Vector__XXX
 SG_ ErrorRegisterVoltage : 18|1@1+ (1,0) [0|0] "" Vector__XXX
 SG_ ErrorRegisterCurrent : 17|1@1+ (1,0) [0|0] "" Vector__XXX
 SG_ ErrorRegisterGeneric : 16|1@1+ (1,0) [0|0] "" Vector__XXX
 SG_ ErrorCode : 0|16@1+ (1,0) [0|0] "" Vector__XXX

BO_ 1902 HBGuard_110: 1 Vector__XXX
 SG_ Toggle : 7|1@1+ (1,0) [0|0] "" Vector__XXX
 SG_ State : 0|7@1+ (1,0) [0|0] "" Vector__XXX

BO_ 1518 SSDO_110: 8 Vector__XXX

BO_ 1646 CSDO_110: 8 Vector__XXX

BO_ 238 EMCY_110: 8 Vector__XXX
 SG_ ManufacturerSpecific5 : 56|8@1+ (1,0) [0|0] "" Vector__XXX
 SG_ ManufacturerSpecific4 : 48|8@1+ (1,0) [0|0] "" Vector__XXX
 SG_ ManufacturerSpecific3 : 40|8@1+ (1,0) [0|0] "" Vector__XXX
 SG_ ManufacturerSpecific2 : 32|8@1+ (1,0) [0|0] "" Vector__XXX
 SG_ ManufacturerSpecific1 : 24|8@1+ (1,0) [0|0] "" Vector__XXX
 SG_ ErrorRegisterManufSpecific : 23|1@1+ (1,0) [0|0] "" Vector__XXX
 SG_ ErrorRegisterReserved : 22|1@1+ (1,0) [0|0] "" Vector__XXX
 SG_ ErrorRegisterProfileSpecific : 21|1@1+ (1,0) [0|0] "" Vector__XXX
 SG_ ErrorRegisterCommunication : 20|1@1+ (1,0) [0|0] "" Vector__XXX
 SG_ ErrorRegisterTemperature : 19|1@1+ (1,0) [0|0] "" Vector__XXX
 SG_ ErrorRegisterVoltage : 18|1@1+ (1,0) [0|0] "" Vector__XXX
 SG_ ErrorRegisterCurrent : 17|1@1+ (1,0) [0|0] "" Vector__XXX
 SG_ ErrorRegisterGeneric : 16|1@1+ (1,0) [0|0] "" Vector__XXX
 SG_ ErrorCode : 0|16@1+ (1,0) [0|0] "" Vector__XXX

BO_ 1901 HBGuard_109: 1 Vector__XXX
 SG_ Toggle : 7|1@1+ (1,0) [0|0] "" Vector__XXX
 SG_ State : 0|7@1+ (1,0) [0|0] "" Vector__XXX

BO_ 1517 SSDO_109: 8 Vector__XXX

BO_ 1645 CSDO_109: 8 Vector__XXX

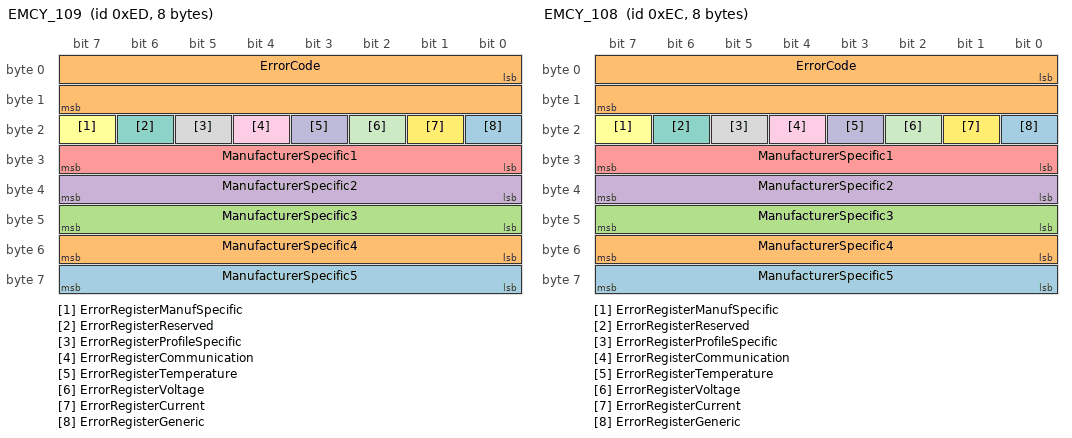
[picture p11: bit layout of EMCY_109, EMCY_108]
BO_ 237 EMCY_109: 8 Vector__XXX
 SG_ ManufacturerSpecific5 : 56|8@1+ (1,0) [0|0] "" Vector__XXX
 SG_ ManufacturerSpecific4 : 48|8@1+ (1,0) [0|0] "" Vector__XXX
 SG_ ManufacturerSpecific3 : 40|8@1+ (1,0) [0|0] "" Vector__XXX
 SG_ ManufacturerSpecific2 : 32|8@1+ (1,0) [0|0] "" Vector__XXX
 SG_ ManufacturerSpecific1 : 24|8@1+ (1,0) [0|0] "" Vector__XXX
 SG_ ErrorRegisterManufSpecific : 23|1@1+ (1,0) [0|0] "" Vector__XXX
 SG_ ErrorRegisterReserved : 22|1@1+ (1,0) [0|0] "" Vector__XXX
 SG_ ErrorRegisterProfileSpecific : 21|1@1+ (1,0) [0|0] "" Vector__XXX
 SG_ ErrorRegisterCommunication : 20|1@1+ (1,0) [0|0] "" Vector__XXX
 SG_ ErrorRegisterTemperature : 19|1@1+ (1,0) [0|0] "" Vector__XXX
 SG_ ErrorRegisterVoltage : 18|1@1+ (1,0) [0|0] "" Vector__XXX
 SG_ ErrorRegisterCurrent : 17|1@1+ (1,0) [0|0] "" Vector__XXX
 SG_ ErrorRegisterGeneric : 16|1@1+ (1,0) [0|0] "" Vector__XXX
 SG_ ErrorCode : 0|16@1+ (1,0) [0|0] "" Vector__XXX

BO_ 1900 HBGuard_108: 1 Vector__XXX
 SG_ Toggle : 7|1@1+ (1,0) [0|0] "" Vector__XXX
 SG_ State : 0|7@1+ (1,0) [0|0] "" Vector__XXX

BO_ 1516 SSDO_108: 8 Vector__XXX

BO_ 1644 CSDO_108: 8 Vector__XXX

BO_ 236 EMCY_108: 8 Vector__XXX
 SG_ ManufacturerSpecific5 : 56|8@1+ (1,0) [0|0] "" Vector__XXX
 SG_ ManufacturerSpecific4 : 48|8@1+ (1,0) [0|0] "" Vector__XXX
 SG_ ManufacturerSpecific3 : 40|8@1+ (1,0) [0|0] "" Vector__XXX
 SG_ ManufacturerSpecific2 : 32|8@1+ (1,0) [0|0] "" Vector__XXX
 SG_ ManufacturerSpecific1 : 24|8@1+ (1,0) [0|0] "" Vector__XXX
 SG_ ErrorRegisterManufSpecific : 23|1@1+ (1,0) [0|0] "" Vector__XXX
 SG_ ErrorRegisterReserved : 22|1@1+ (1,0) [0|0] "" Vector__XXX
 SG_ ErrorRegisterProfileSpecific : 21|1@1+ (1,0) [0|0] "" Vector__XXX
 SG_ ErrorRegisterCommunication : 20|1@1+ (1,0) [0|0] "" Vector__XXX
 SG_ ErrorRegisterTemperature : 19|1@1+ (1,0) [0|0] "" Vector__XXX
 SG_ ErrorRegisterVoltage : 18|1@1+ (1,0) [0|0] "" Vector__XXX
 SG_ ErrorRegisterCurrent : 17|1@1+ (1,0) [0|0] "" Vector__XXX
 SG_ ErrorRegisterGeneric : 16|1@1+ (1,0) [0|0] "" Vector__XXX
 SG_ ErrorCode : 0|16@1+ (1,0) [0|0] "" Vector__XXX

BO_ 1899 HBGuard_107: 1 Vector__XXX
 SG_ Toggle : 7|1@1+ (1,0) [0|0] "" Vector__XXX
 SG_ State : 0|7@1+ (1,0) [0|0] "" Vector__XXX

BO_ 1515 SSDO_107: 8 Vector__XXX

BO_ 1643 CSDO_107: 8 Vector__XXX

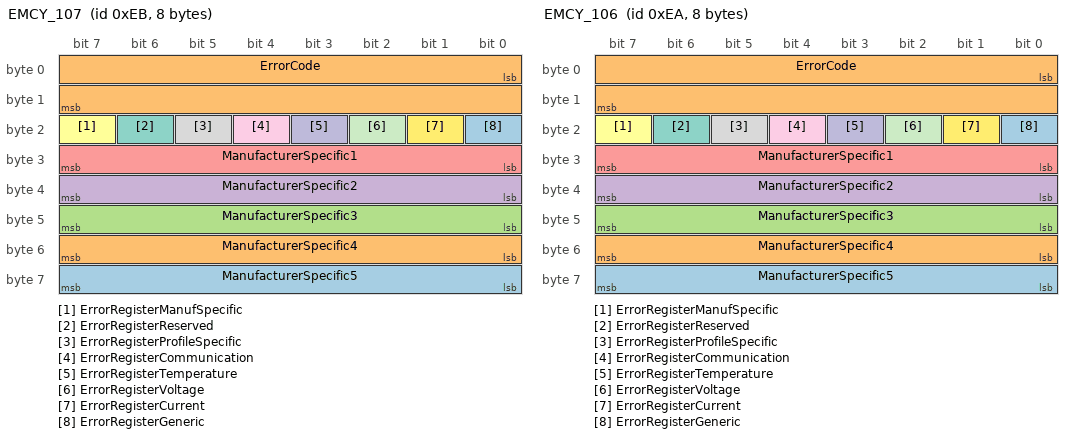
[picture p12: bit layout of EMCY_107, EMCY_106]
BO_ 235 EMCY_107: 8 Vector__XXX
 SG_ ManufacturerSpecific5 : 56|8@1+ (1,0) [0|0] "" Vector__XXX
 SG_ ManufacturerSpecific4 : 48|8@1+ (1,0) [0|0] "" Vector__XXX
 SG_ ManufacturerSpecific3 : 40|8@1+ (1,0) [0|0] "" Vector__XXX
 SG_ ManufacturerSpecific2 : 32|8@1+ (1,0) [0|0] "" Vector__XXX
 SG_ ManufacturerSpecific1 : 24|8@1+ (1,0) [0|0] "" Vector__XXX
 SG_ ErrorRegisterManufSpecific : 23|1@1+ (1,0) [0|0] "" Vector__XXX
 SG_ ErrorRegisterReserved : 22|1@1+ (1,0) [0|0] "" Vector__XXX
 SG_ ErrorRegisterProfileSpecific : 21|1@1+ (1,0) [0|0] "" Vector__XXX
 SG_ ErrorRegisterCommunication : 20|1@1+ (1,0) [0|0] "" Vector__XXX
 SG_ ErrorRegisterTemperature : 19|1@1+ (1,0) [0|0] "" Vector__XXX
 SG_ ErrorRegisterVoltage : 18|1@1+ (1,0) [0|0] "" Vector__XXX
 SG_ ErrorRegisterCurrent : 17|1@1+ (1,0) [0|0] "" Vector__XXX
 SG_ ErrorRegisterGeneric : 16|1@1+ (1,0) [0|0] "" Vector__XXX
 SG_ ErrorCode : 0|16@1+ (1,0) [0|0] "" Vector__XXX

BO_ 1898 HBGuard_106: 1 Vector__XXX
 SG_ Toggle : 7|1@1+ (1,0) [0|0] "" Vector__XXX
 SG_ State : 0|7@1+ (1,0) [0|0] "" Vector__XXX

BO_ 1514 SSDO_106: 8 Vector__XXX

BO_ 1642 CSDO_106: 8 Vector__XXX

BO_ 234 EMCY_106: 8 Vector__XXX
 SG_ ManufacturerSpecific5 : 56|8@1+ (1,0) [0|0] "" Vector__XXX
 SG_ ManufacturerSpecific4 : 48|8@1+ (1,0) [0|0] "" Vector__XXX
 SG_ ManufacturerSpecific3 : 40|8@1+ (1,0) [0|0] "" Vector__XXX
 SG_ ManufacturerSpecific2 : 32|8@1+ (1,0) [0|0] "" Vector__XXX
 SG_ ManufacturerSpecific1 : 24|8@1+ (1,0) [0|0] "" Vector__XXX
 SG_ ErrorRegisterManufSpecific : 23|1@1+ (1,0) [0|0] "" Vector__XXX
 SG_ ErrorRegisterReserved : 22|1@1+ (1,0) [0|0] "" Vector__XXX
 SG_ ErrorRegisterProfileSpecific : 21|1@1+ (1,0) [0|0] "" Vector__XXX
 SG_ ErrorRegisterCommunication : 20|1@1+ (1,0) [0|0] "" Vector__XXX
 SG_ ErrorRegisterTemperature : 19|1@1+ (1,0) [0|0] "" Vector__XXX
 SG_ ErrorRegisterVoltage : 18|1@1+ (1,0) [0|0] "" Vector__XXX
 SG_ ErrorRegisterCurrent : 17|1@1+ (1,0) [0|0] "" Vector__XXX
 SG_ ErrorRegisterGeneric : 16|1@1+ (1,0) [0|0] "" Vector__XXX
 SG_ ErrorCode : 0|16@1+ (1,0) [0|0] "" Vector__XXX

BO_ 1897 HBGuard_105: 1 Vector__XXX
 SG_ Toggle : 7|1@1+ (1,0) [0|0] "" Vector__XXX
 SG_ State : 0|7@1+ (1,0) [0|0] "" Vector__XXX

BO_ 1513 SSDO_105: 8 Vector__XXX

BO_ 1641 CSDO_105: 8 Vector__XXX

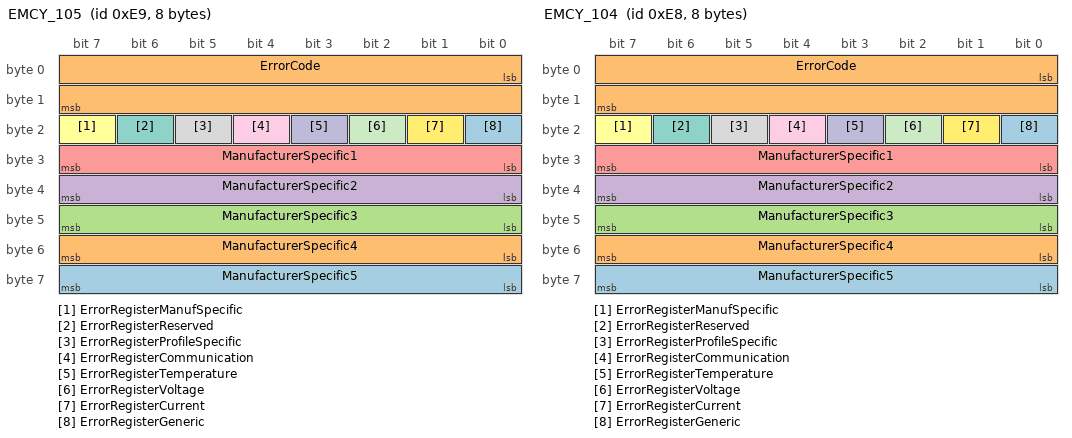
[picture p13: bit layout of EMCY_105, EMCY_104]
BO_ 233 EMCY_105: 8 Vector__XXX
 SG_ ManufacturerSpecific5 : 56|8@1+ (1,0) [0|0] "" Vector__XXX
 SG_ ManufacturerSpecific4 : 48|8@1+ (1,0) [0|0] "" Vector__XXX
 SG_ ManufacturerSpecific3 : 40|8@1+ (1,0) [0|0] "" Vector__XXX
 SG_ ManufacturerSpecific2 : 32|8@1+ (1,0) [0|0] "" Vector__XXX
 SG_ ManufacturerSpecific1 : 24|8@1+ (1,0) [0|0] "" Vector__XXX
 SG_ ErrorRegisterManufSpecific : 23|1@1+ (1,0) [0|0] "" Vector__XXX
 SG_ ErrorRegisterReserved : 22|1@1+ (1,0) [0|0] "" Vector__XXX
 SG_ ErrorRegisterProfileSpecific : 21|1@1+ (1,0) [0|0] "" Vector__XXX
 SG_ ErrorRegisterCommunication : 20|1@1+ (1,0) [0|0] "" Vector__XXX
 SG_ ErrorRegisterTemperature : 19|1@1+ (1,0) [0|0] "" Vector__XXX
 SG_ ErrorRegisterVoltage : 18|1@1+ (1,0) [0|0] "" Vector__XXX
 SG_ ErrorRegisterCurrent : 17|1@1+ (1,0) [0|0] "" Vector__XXX
 SG_ ErrorRegisterGeneric : 16|1@1+ (1,0) [0|0] "" Vector__XXX
 SG_ ErrorCode : 0|16@1+ (1,0) [0|0] "" Vector__XXX

BO_ 1896 HBGuard_104: 1 Vector__XXX
 SG_ Toggle : 7|1@1+ (1,0) [0|0] "" Vector__XXX
 SG_ State : 0|7@1+ (1,0) [0|0] "" Vector__XXX

BO_ 1512 SSDO_104: 8 Vector__XXX

BO_ 1640 CSDO_104: 8 Vector__XXX

BO_ 232 EMCY_104: 8 Vector__XXX
 SG_ ManufacturerSpecific5 : 56|8@1+ (1,0) [0|0] "" Vector__XXX
 SG_ ManufacturerSpecific4 : 48|8@1+ (1,0) [0|0] "" Vector__XXX
 SG_ ManufacturerSpecific3 : 40|8@1+ (1,0) [0|0] "" Vector__XXX
 SG_ ManufacturerSpecific2 : 32|8@1+ (1,0) [0|0] "" Vector__XXX
 SG_ ManufacturerSpecific1 : 24|8@1+ (1,0) [0|0] "" Vector__XXX
 SG_ ErrorRegisterManufSpecific : 23|1@1+ (1,0) [0|0] "" Vector__XXX
 SG_ ErrorRegisterReserved : 22|1@1+ (1,0) [0|0] "" Vector__XXX
 SG_ ErrorRegisterProfileSpecific : 21|1@1+ (1,0) [0|0] "" Vector__XXX
 SG_ ErrorRegisterCommunication : 20|1@1+ (1,0) [0|0] "" Vector__XXX
 SG_ ErrorRegisterTemperature : 19|1@1+ (1,0) [0|0] "" Vector__XXX
 SG_ ErrorRegisterVoltage : 18|1@1+ (1,0) [0|0] "" Vector__XXX
 SG_ ErrorRegisterCurrent : 17|1@1+ (1,0) [0|0] "" Vector__XXX
 SG_ ErrorRegisterGeneric : 16|1@1+ (1,0) [0|0] "" Vector__XXX
 SG_ ErrorCode : 0|16@1+ (1,0) [0|0] "" Vector__XXX

BO_ 1895 HBGuard_103: 1 Vector__XXX
 SG_ Toggle : 7|1@1+ (1,0) [0|0] "" Vector__XXX
 SG_ State : 0|7@1+ (1,0) [0|0] "" Vector__XXX

BO_ 1511 SSDO_103: 8 Vector__XXX

BO_ 1639 CSDO_103: 8 Vector__XXX

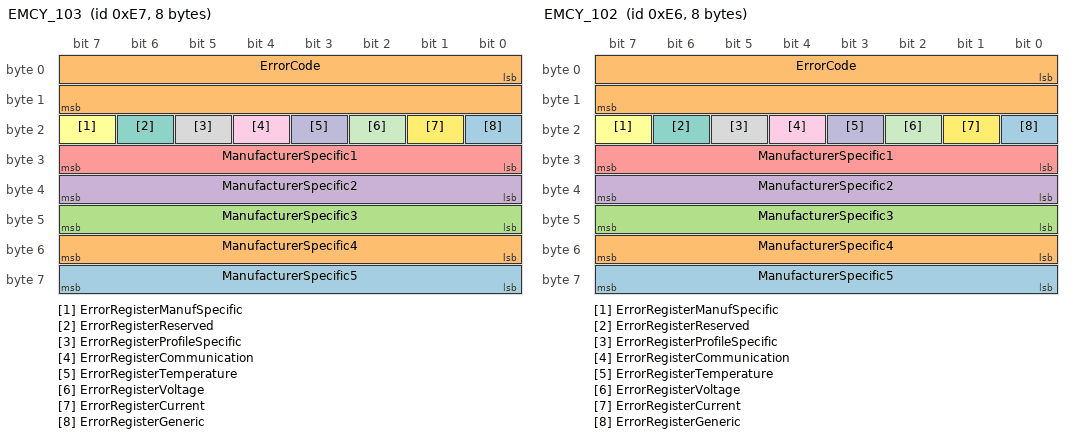
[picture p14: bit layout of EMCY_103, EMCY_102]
BO_ 231 EMCY_103: 8 Vector__XXX
 SG_ ManufacturerSpecific5 : 56|8@1+ (1,0) [0|0] "" Vector__XXX
 SG_ ManufacturerSpecific4 : 48|8@1+ (1,0) [0|0] "" Vector__XXX
 SG_ ManufacturerSpecific3 : 40|8@1+ (1,0) [0|0] "" Vector__XXX
 SG_ ManufacturerSpecific2 : 32|8@1+ (1,0) [0|0] "" Vector__XXX
 SG_ ManufacturerSpecific1 : 24|8@1+ (1,0) [0|0] "" Vector__XXX
 SG_ ErrorRegisterManufSpecific : 23|1@1+ (1,0) [0|0] "" Vector__XXX
 SG_ ErrorRegisterReserved : 22|1@1+ (1,0) [0|0] "" Vector__XXX
 SG_ ErrorRegisterProfileSpecific : 21|1@1+ (1,0) [0|0] "" Vector__XXX
 SG_ ErrorRegisterCommunication : 20|1@1+ (1,0) [0|0] "" Vector__XXX
 SG_ ErrorRegisterTemperature : 19|1@1+ (1,0) [0|0] "" Vector__XXX
 SG_ ErrorRegisterVoltage : 18|1@1+ (1,0) [0|0] "" Vector__XXX
 SG_ ErrorRegisterCurrent : 17|1@1+ (1,0) [0|0] "" Vector__XXX
 SG_ ErrorRegisterGeneric : 16|1@1+ (1,0) [0|0] "" Vector__XXX
 SG_ ErrorCode : 0|16@1+ (1,0) [0|0] "" Vector__XXX

BO_ 1894 HBGuard_102: 1 Vector__XXX
 SG_ Toggle : 7|1@1+ (1,0) [0|0] "" Vector__XXX
 SG_ State : 0|7@1+ (1,0) [0|0] "" Vector__XXX

BO_ 1510 SSDO_102: 8 Vector__XXX

BO_ 1638 CSDO_102: 8 Vector__XXX

BO_ 230 EMCY_102: 8 Vector__XXX
 SG_ ManufacturerSpecific5 : 56|8@1+ (1,0) [0|0] "" Vector__XXX
 SG_ ManufacturerSpecific4 : 48|8@1+ (1,0) [0|0] "" Vector__XXX
 SG_ ManufacturerSpecific3 : 40|8@1+ (1,0) [0|0] "" Vector__XXX
 SG_ ManufacturerSpecific2 : 32|8@1+ (1,0) [0|0] "" Vector__XXX
 SG_ ManufacturerSpecific1 : 24|8@1+ (1,0) [0|0] "" Vector__XXX
 SG_ ErrorRegisterManufSpecific : 23|1@1+ (1,0) [0|0] "" Vector__XXX
 SG_ ErrorRegisterReserved : 22|1@1+ (1,0) [0|0] "" Vector__XXX
 SG_ ErrorRegisterProfileSpecific : 21|1@1+ (1,0) [0|0] "" Vector__XXX
 SG_ ErrorRegisterCommunication : 20|1@1+ (1,0) [0|0] "" Vector__XXX
 SG_ ErrorRegisterTemperature : 19|1@1+ (1,0) [0|0] "" Vector__XXX
 SG_ ErrorRegisterVoltage : 18|1@1+ (1,0) [0|0] "" Vector__XXX
 SG_ ErrorRegisterCurrent : 17|1@1+ (1,0) [0|0] "" Vector__XXX
 SG_ ErrorRegisterGeneric : 16|1@1+ (1,0) [0|0] "" Vector__XXX
 SG_ ErrorCode : 0|16@1+ (1,0) [0|0] "" Vector__XXX

BO_ 1893 HBGuard_101: 1 Vector__XXX
 SG_ Toggle : 7|1@1+ (1,0) [0|0] "" Vector__XXX
 SG_ State : 0|7@1+ (1,0) [0|0] "" Vector__XXX

BO_ 1509 SSDO_101: 8 Vector__XXX

BO_ 1637 CSDO_101: 8 Vector__XXX

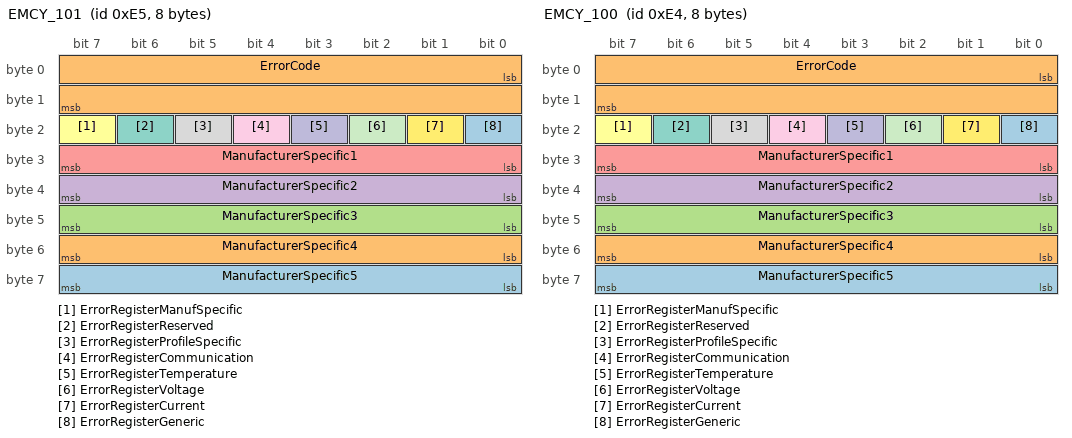
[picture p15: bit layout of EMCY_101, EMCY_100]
BO_ 229 EMCY_101: 8 Vector__XXX
 SG_ ManufacturerSpecific5 : 56|8@1+ (1,0) [0|0] "" Vector__XXX
 SG_ ManufacturerSpecific4 : 48|8@1+ (1,0) [0|0] "" Vector__XXX
 SG_ ManufacturerSpecific3 : 40|8@1+ (1,0) [0|0] "" Vector__XXX
 SG_ ManufacturerSpecific2 : 32|8@1+ (1,0) [0|0] "" Vector__XXX
 SG_ ManufacturerSpecific1 : 24|8@1+ (1,0) [0|0] "" Vector__XXX
 SG_ ErrorRegisterManufSpecific : 23|1@1+ (1,0) [0|0] "" Vector__XXX
 SG_ ErrorRegisterReserved : 22|1@1+ (1,0) [0|0] "" Vector__XXX
 SG_ ErrorRegisterProfileSpecific : 21|1@1+ (1,0) [0|0] "" Vector__XXX
 SG_ ErrorRegisterCommunication : 20|1@1+ (1,0) [0|0] "" Vector__XXX
 SG_ ErrorRegisterTemperature : 19|1@1+ (1,0) [0|0] "" Vector__XXX
 SG_ ErrorRegisterVoltage : 18|1@1+ (1,0) [0|0] "" Vector__XXX
 SG_ ErrorRegisterCurrent : 17|1@1+ (1,0) [0|0] "" Vector__XXX
 SG_ ErrorRegisterGeneric : 16|1@1+ (1,0) [0|0] "" Vector__XXX
 SG_ ErrorCode : 0|16@1+ (1,0) [0|0] "" Vector__XXX

BO_ 1892 HBGuard_100: 1 Vector__XXX
 SG_ Toggle : 7|1@1+ (1,0) [0|0] "" Vector__XXX
 SG_ State : 0|7@1+ (1,0) [0|0] "" Vector__XXX

BO_ 1508 SSDO_100: 8 Vector__XXX

BO_ 1636 CSDO_100: 8 Vector__XXX

BO_ 228 EMCY_100: 8 Vector__XXX
 SG_ ManufacturerSpecific5 : 56|8@1+ (1,0) [0|0] "" Vector__XXX
 SG_ ManufacturerSpecific4 : 48|8@1+ (1,0) [0|0] "" Vector__XXX
 SG_ ManufacturerSpecific3 : 40|8@1+ (1,0) [0|0] "" Vector__XXX
 SG_ ManufacturerSpecific2 : 32|8@1+ (1,0) [0|0] "" Vector__XXX
 SG_ ManufacturerSpecific1 : 24|8@1+ (1,0) [0|0] "" Vector__XXX
 SG_ ErrorRegisterManufSpecific : 23|1@1+ (1,0) [0|0] "" Vector__XXX
 SG_ ErrorRegisterReserved : 22|1@1+ (1,0) [0|0] "" Vector__XXX
 SG_ ErrorRegisterProfileSpecific : 21|1@1+ (1,0) [0|0] "" Vector__XXX
 SG_ ErrorRegisterCommunication : 20|1@1+ (1,0) [0|0] "" Vector__XXX
 SG_ ErrorRegisterTemperature : 19|1@1+ (1,0) [0|0] "" Vector__XXX
 SG_ ErrorRegisterVoltage : 18|1@1+ (1,0) [0|0] "" Vector__XXX
 SG_ ErrorRegisterCurrent : 17|1@1+ (1,0) [0|0] "" Vector__XXX
 SG_ ErrorRegisterGeneric : 16|1@1+ (1,0) [0|0] "" Vector__XXX
 SG_ ErrorCode : 0|16@1+ (1,0) [0|0] "" Vector__XXX

BO_ 1891 HBGuard_099: 1 Vector__XXX
 SG_ Toggle : 7|1@1+ (1,0) [0|0] "" Vector__XXX
 SG_ State : 0|7@1+ (1,0) [0|0] "" Vector__XXX

BO_ 1507 SSDO_099: 8 Vector__XXX

BO_ 1635 CSDO_099: 8 Vector__XXX

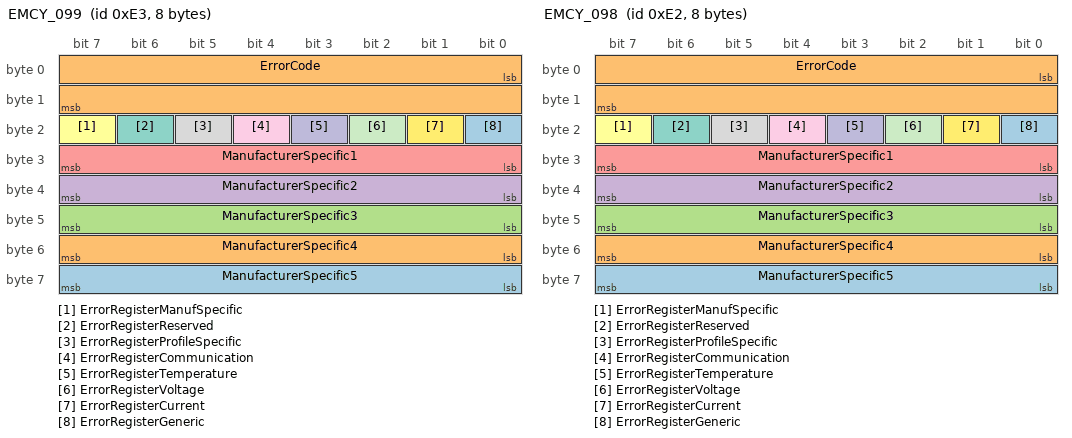
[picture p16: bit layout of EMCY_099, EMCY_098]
BO_ 227 EMCY_099: 8 Vector__XXX
 SG_ ManufacturerSpecific5 : 56|8@1+ (1,0) [0|0] "" Vector__XXX
 SG_ ManufacturerSpecific4 : 48|8@1+ (1,0) [0|0] "" Vector__XXX
 SG_ ManufacturerSpecific3 : 40|8@1+ (1,0) [0|0] "" Vector__XXX
 SG_ ManufacturerSpecific2 : 32|8@1+ (1,0) [0|0] "" Vector__XXX
 SG_ ManufacturerSpecific1 : 24|8@1+ (1,0) [0|0] "" Vector__XXX
 SG_ ErrorRegisterManufSpecific : 23|1@1+ (1,0) [0|0] "" Vector__XXX
 SG_ ErrorRegisterReserved : 22|1@1+ (1,0) [0|0] "" Vector__XXX
 SG_ ErrorRegisterProfileSpecific : 21|1@1+ (1,0) [0|0] "" Vector__XXX
 SG_ ErrorRegisterCommunication : 20|1@1+ (1,0) [0|0] "" Vector__XXX
 SG_ ErrorRegisterTemperature : 19|1@1+ (1,0) [0|0] "" Vector__XXX
 SG_ ErrorRegisterVoltage : 18|1@1+ (1,0) [0|0] "" Vector__XXX
 SG_ ErrorRegisterCurrent : 17|1@1+ (1,0) [0|0] "" Vector__XXX
 SG_ ErrorRegisterGeneric : 16|1@1+ (1,0) [0|0] "" Vector__XXX
 SG_ ErrorCode : 0|16@1+ (1,0) [0|0] "" Vector__XXX

BO_ 1890 HBGuard_098: 1 Vector__XXX
 SG_ Toggle : 7|1@1+ (1,0) [0|0] "" Vector__XXX
 SG_ State : 0|7@1+ (1,0) [0|0] "" Vector__XXX

BO_ 1506 SSDO_098: 8 Vector__XXX

BO_ 1634 CSDO_098: 8 Vector__XXX

BO_ 226 EMCY_098: 8 Vector__XXX
 SG_ ManufacturerSpecific5 : 56|8@1+ (1,0) [0|0] "" Vector__XXX
 SG_ ManufacturerSpecific4 : 48|8@1+ (1,0) [0|0] "" Vector__XXX
 SG_ ManufacturerSpecific3 : 40|8@1+ (1,0) [0|0] "" Vector__XXX
 SG_ ManufacturerSpecific2 : 32|8@1+ (1,0) [0|0] "" Vector__XXX
 SG_ ManufacturerSpecific1 : 24|8@1+ (1,0) [0|0] "" Vector__XXX
 SG_ ErrorRegisterManufSpecific : 23|1@1+ (1,0) [0|0] "" Vector__XXX
 SG_ ErrorRegisterReserved : 22|1@1+ (1,0) [0|0] "" Vector__XXX
 SG_ ErrorRegisterProfileSpecific : 21|1@1+ (1,0) [0|0] "" Vector__XXX
 SG_ ErrorRegisterCommunication : 20|1@1+ (1,0) [0|0] "" Vector__XXX
 SG_ ErrorRegisterTemperature : 19|1@1+ (1,0) [0|0] "" Vector__XXX
 SG_ ErrorRegisterVoltage : 18|1@1+ (1,0) [0|0] "" Vector__XXX
 SG_ ErrorRegisterCurrent : 17|1@1+ (1,0) [0|0] "" Vector__XXX
 SG_ ErrorRegisterGeneric : 16|1@1+ (1,0) [0|0] "" Vector__XXX
 SG_ ErrorCode : 0|16@1+ (1,0) [0|0] "" Vector__XXX

BO_ 1889 HBGuard_097: 1 Vector__XXX
 SG_ Toggle : 7|1@1+ (1,0) [0|0] "" Vector__XXX
 SG_ State : 0|7@1+ (1,0) [0|0] "" Vector__XXX

BO_ 1505 SSDO_097: 8 Vector__XXX

BO_ 1633 CSDO_097: 8 Vector__XXX

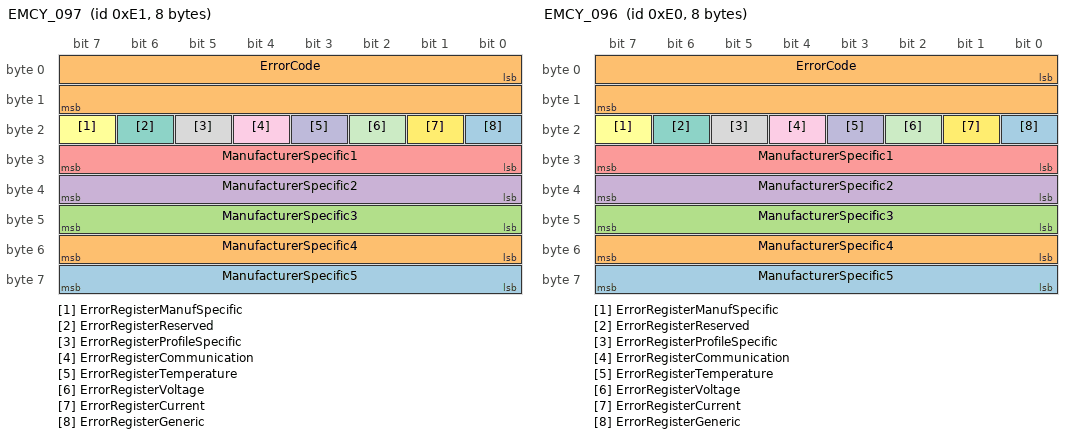
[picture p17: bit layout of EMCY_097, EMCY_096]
BO_ 225 EMCY_097: 8 Vector__XXX
 SG_ ManufacturerSpecific5 : 56|8@1+ (1,0) [0|0] "" Vector__XXX
 SG_ ManufacturerSpecific4 : 48|8@1+ (1,0) [0|0] "" Vector__XXX
 SG_ ManufacturerSpecific3 : 40|8@1+ (1,0) [0|0] "" Vector__XXX
 SG_ ManufacturerSpecific2 : 32|8@1+ (1,0) [0|0] "" Vector__XXX
 SG_ ManufacturerSpecific1 : 24|8@1+ (1,0) [0|0] "" Vector__XXX
 SG_ ErrorRegisterManufSpecific : 23|1@1+ (1,0) [0|0] "" Vector__XXX
 SG_ ErrorRegisterReserved : 22|1@1+ (1,0) [0|0] "" Vector__XXX
 SG_ ErrorRegisterProfileSpecific : 21|1@1+ (1,0) [0|0] "" Vector__XXX
 SG_ ErrorRegisterCommunication : 20|1@1+ (1,0) [0|0] "" Vector__XXX
 SG_ ErrorRegisterTemperature : 19|1@1+ (1,0) [0|0] "" Vector__XXX
 SG_ ErrorRegisterVoltage : 18|1@1+ (1,0) [0|0] "" Vector__XXX
 SG_ ErrorRegisterCurrent : 17|1@1+ (1,0) [0|0] "" Vector__XXX
 SG_ ErrorRegisterGeneric : 16|1@1+ (1,0) [0|0] "" Vector__XXX
 SG_ ErrorCode : 0|16@1+ (1,0) [0|0] "" Vector__XXX

BO_ 1888 HBGuard_096: 1 Vector__XXX
 SG_ Toggle : 7|1@1+ (1,0) [0|0] "" Vector__XXX
 SG_ State : 0|7@1+ (1,0) [0|0] "" Vector__XXX

BO_ 1504 SSDO_096: 8 Vector__XXX

BO_ 1632 CSDO_096: 8 Vector__XXX

BO_ 224 EMCY_096: 8 Vector__XXX
 SG_ ManufacturerSpecific5 : 56|8@1+ (1,0) [0|0] "" Vector__XXX
 SG_ ManufacturerSpecific4 : 48|8@1+ (1,0) [0|0] "" Vector__XXX
 SG_ ManufacturerSpecific3 : 40|8@1+ (1,0) [0|0] "" Vector__XXX
 SG_ ManufacturerSpecific2 : 32|8@1+ (1,0) [0|0] "" Vector__XXX
 SG_ ManufacturerSpecific1 : 24|8@1+ (1,0) [0|0] "" Vector__XXX
 SG_ ErrorRegisterManufSpecific : 23|1@1+ (1,0) [0|0] "" Vector__XXX
 SG_ ErrorRegisterReserved : 22|1@1+ (1,0) [0|0] "" Vector__XXX
 SG_ ErrorRegisterProfileSpecific : 21|1@1+ (1,0) [0|0] "" Vector__XXX
 SG_ ErrorRegisterCommunication : 20|1@1+ (1,0) [0|0] "" Vector__XXX
 SG_ ErrorRegisterTemperature : 19|1@1+ (1,0) [0|0] "" Vector__XXX
 SG_ ErrorRegisterVoltage : 18|1@1+ (1,0) [0|0] "" Vector__XXX
 SG_ ErrorRegisterCurrent : 17|1@1+ (1,0) [0|0] "" Vector__XXX
 SG_ ErrorRegisterGeneric : 16|1@1+ (1,0) [0|0] "" Vector__XXX
 SG_ ErrorCode : 0|16@1+ (1,0) [0|0] "" Vector__XXX

BO_ 1887 HBGuard_095: 1 Vector__XXX
 SG_ Toggle : 7|1@1+ (1,0) [0|0] "" Vector__XXX
 SG_ State : 0|7@1+ (1,0) [0|0] "" Vector__XXX

BO_ 1503 SSDO_095: 8 Vector__XXX

BO_ 1631 CSDO_095: 8 Vector__XXX

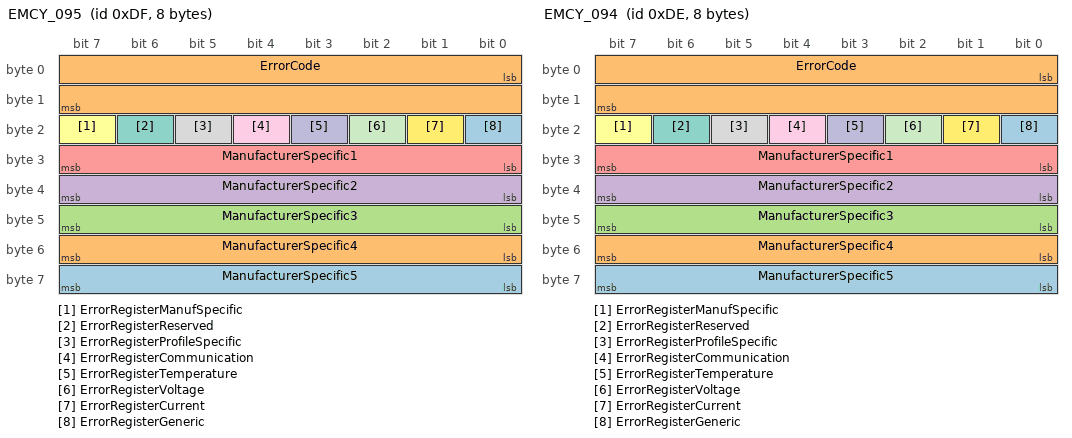
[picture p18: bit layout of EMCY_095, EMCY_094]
BO_ 223 EMCY_095: 8 Vector__XXX
 SG_ ManufacturerSpecific5 : 56|8@1+ (1,0) [0|0] "" Vector__XXX
 SG_ ManufacturerSpecific4 : 48|8@1+ (1,0) [0|0] "" Vector__XXX
 SG_ ManufacturerSpecific3 : 40|8@1+ (1,0) [0|0] "" Vector__XXX
 SG_ ManufacturerSpecific2 : 32|8@1+ (1,0) [0|0] "" Vector__XXX
 SG_ ManufacturerSpecific1 : 24|8@1+ (1,0) [0|0] "" Vector__XXX
 SG_ ErrorRegisterManufSpecific : 23|1@1+ (1,0) [0|0] "" Vector__XXX
 SG_ ErrorRegisterReserved : 22|1@1+ (1,0) [0|0] "" Vector__XXX
 SG_ ErrorRegisterProfileSpecific : 21|1@1+ (1,0) [0|0] "" Vector__XXX
 SG_ ErrorRegisterCommunication : 20|1@1+ (1,0) [0|0] "" Vector__XXX
 SG_ ErrorRegisterTemperature : 19|1@1+ (1,0) [0|0] "" Vector__XXX
 SG_ ErrorRegisterVoltage : 18|1@1+ (1,0) [0|0] "" Vector__XXX
 SG_ ErrorRegisterCurrent : 17|1@1+ (1,0) [0|0] "" Vector__XXX
 SG_ ErrorRegisterGeneric : 16|1@1+ (1,0) [0|0] "" Vector__XXX
 SG_ ErrorCode : 0|16@1+ (1,0) [0|0] "" Vector__XXX

BO_ 1886 HBGuard_094: 1 Vector__XXX
 SG_ Toggle : 7|1@1+ (1,0) [0|0] "" Vector__XXX
 SG_ State : 0|7@1+ (1,0) [0|0] "" Vector__XXX

BO_ 1502 SSDO_094: 8 Vector__XXX

BO_ 1630 CSDO_094: 8 Vector__XXX

BO_ 222 EMCY_094: 8 Vector__XXX
 SG_ ManufacturerSpecific5 : 56|8@1+ (1,0) [0|0] "" Vector__XXX
 SG_ ManufacturerSpecific4 : 48|8@1+ (1,0) [0|0] "" Vector__XXX
 SG_ ManufacturerSpecific3 : 40|8@1+ (1,0) [0|0] "" Vector__XXX
 SG_ ManufacturerSpecific2 : 32|8@1+ (1,0) [0|0] "" Vector__XXX
 SG_ ManufacturerSpecific1 : 24|8@1+ (1,0) [0|0] "" Vector__XXX
 SG_ ErrorRegisterManufSpecific : 23|1@1+ (1,0) [0|0] "" Vector__XXX
 SG_ ErrorRegisterReserved : 22|1@1+ (1,0) [0|0] "" Vector__XXX
 SG_ ErrorRegisterProfileSpecific : 21|1@1+ (1,0) [0|0] "" Vector__XXX
 SG_ ErrorRegisterCommunication : 20|1@1+ (1,0) [0|0] "" Vector__XXX
 SG_ ErrorRegisterTemperature : 19|1@1+ (1,0) [0|0] "" Vector__XXX
 SG_ ErrorRegisterVoltage : 18|1@1+ (1,0) [0|0] "" Vector__XXX
 SG_ ErrorRegisterCurrent : 17|1@1+ (1,0) [0|0] "" Vector__XXX
 SG_ ErrorRegisterGeneric : 16|1@1+ (1,0) [0|0] "" Vector__XXX
 SG_ ErrorCode : 0|16@1+ (1,0) [0|0] "" Vector__XXX

BO_ 1885 HBGuard_093: 1 Vector__XXX
 SG_ Toggle : 7|1@1+ (1,0) [0|0] "" Vector__XXX
 SG_ State : 0|7@1+ (1,0) [0|0] "" Vector__XXX

BO_ 1501 SSDO_093: 8 Vector__XXX

BO_ 1629 CSDO_093: 8 Vector__XXX

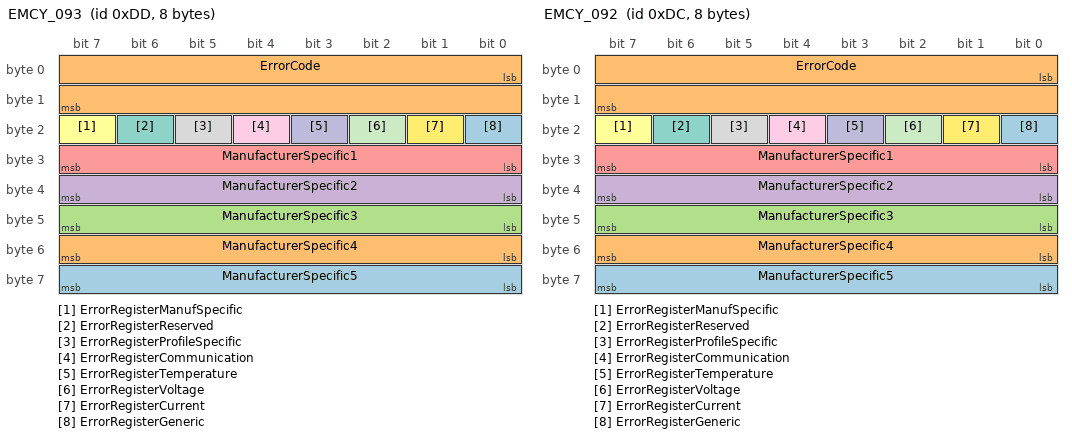
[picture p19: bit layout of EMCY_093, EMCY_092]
BO_ 221 EMCY_093: 8 Vector__XXX
 SG_ ManufacturerSpecific5 : 56|8@1+ (1,0) [0|0] "" Vector__XXX
 SG_ ManufacturerSpecific4 : 48|8@1+ (1,0) [0|0] "" Vector__XXX
 SG_ ManufacturerSpecific3 : 40|8@1+ (1,0) [0|0] "" Vector__XXX
 SG_ ManufacturerSpecific2 : 32|8@1+ (1,0) [0|0] "" Vector__XXX
 SG_ ManufacturerSpecific1 : 24|8@1+ (1,0) [0|0] "" Vector__XXX
 SG_ ErrorRegisterManufSpecific : 23|1@1+ (1,0) [0|0] "" Vector__XXX
 SG_ ErrorRegisterReserved : 22|1@1+ (1,0) [0|0] "" Vector__XXX
 SG_ ErrorRegisterProfileSpecific : 21|1@1+ (1,0) [0|0] "" Vector__XXX
 SG_ ErrorRegisterCommunication : 20|1@1+ (1,0) [0|0] "" Vector__XXX
 SG_ ErrorRegisterTemperature : 19|1@1+ (1,0) [0|0] "" Vector__XXX
 SG_ ErrorRegisterVoltage : 18|1@1+ (1,0) [0|0] "" Vector__XXX
 SG_ ErrorRegisterCurrent : 17|1@1+ (1,0) [0|0] "" Vector__XXX
 SG_ ErrorRegisterGeneric : 16|1@1+ (1,0) [0|0] "" Vector__XXX
 SG_ ErrorCode : 0|16@1+ (1,0) [0|0] "" Vector__XXX

BO_ 1884 HBGuard_092: 1 Vector__XXX
 SG_ Toggle : 7|1@1+ (1,0) [0|0] "" Vector__XXX
 SG_ State : 0|7@1+ (1,0) [0|0] "" Vector__XXX

BO_ 1500 SSDO_092: 8 Vector__XXX

BO_ 1628 CSDO_092: 8 Vector__XXX

BO_ 220 EMCY_092: 8 Vector__XXX
 SG_ ManufacturerSpecific5 : 56|8@1+ (1,0) [0|0] "" Vector__XXX
 SG_ ManufacturerSpecific4 : 48|8@1+ (1,0) [0|0] "" Vector__XXX
 SG_ ManufacturerSpecific3 : 40|8@1+ (1,0) [0|0] "" Vector__XXX
 SG_ ManufacturerSpecific2 : 32|8@1+ (1,0) [0|0] "" Vector__XXX
 SG_ ManufacturerSpecific1 : 24|8@1+ (1,0) [0|0] "" Vector__XXX
 SG_ ErrorRegisterManufSpecific : 23|1@1+ (1,0) [0|0] "" Vector__XXX
 SG_ ErrorRegisterReserved : 22|1@1+ (1,0) [0|0] "" Vector__XXX
 SG_ ErrorRegisterProfileSpecific : 21|1@1+ (1,0) [0|0] "" Vector__XXX
 SG_ ErrorRegisterCommunication : 20|1@1+ (1,0) [0|0] "" Vector__XXX
 SG_ ErrorRegisterTemperature : 19|1@1+ (1,0) [0|0] "" Vector__XXX
 SG_ ErrorRegisterVoltage : 18|1@1+ (1,0) [0|0] "" Vector__XXX
 SG_ ErrorRegisterCurrent : 17|1@1+ (1,0) [0|0] "" Vector__XXX
 SG_ ErrorRegisterGeneric : 16|1@1+ (1,0) [0|0] "" Vector__XXX
 SG_ ErrorCode : 0|16@1+ (1,0) [0|0] "" Vector__XXX

BO_ 1883 HBGuard_091: 1 Vector__XXX
 SG_ Toggle : 7|1@1+ (1,0) [0|0] "" Vector__XXX
 SG_ State : 0|7@1+ (1,0) [0|0] "" Vector__XXX

BO_ 1499 SSDO_091: 8 Vector__XXX

BO_ 1627 CSDO_091: 8 Vector__XXX

BO_ 219 EMCY_091: 8 Vector__XXX
 SG_ ManufacturerSpecific5 : 56|8@1+ (1,0) [0|0] "" Vector__XXX
 SG_ ManufacturerSpecific4 : 48|8@1+ (1,0) [0|0] "" Vector__XXX
 SG_ ManufacturerSpecific3 : 40|8@1+ (1,0) [0|0] "" Vector__XXX
 SG_ ManufacturerSpecific2 : 32|8@1+ (1,0) [0|0] "" Vector__XXX
 SG_ ManufacturerSpecific1 : 24|8@1+ (1,0) [0|0] "" Vector__XXX
 SG_ ErrorRegisterManufSpecific : 23|1@1+ (1,0) [0|0] "" Vector__XXX
 SG_ ErrorRegisterReserved : 22|1@1+ (1,0) [0|0] "" Vector__XXX
 SG_ ErrorRegisterProfileSpecific : 21|1@1+ (1,0) [0|0] "" Vector__XXX
 SG_ ErrorRegisterCommunication : 20|1@1+ (1,0) [0|0] "" Vector__XXX
 SG_ ErrorRegisterTemperature : 19|1@1+ (1,0) [0|0] "" Vector__XXX
 SG_ ErrorRegisterVoltage : 18|1@1+ (1,0) [0|0] "" Vector__XXX
 SG_ ErrorRegisterCurrent : 17|1@1+ (1,0) [0|0] "" Vector__XXX
 SG_ ErrorRegisterGeneric : 16|1@1+ (1,0) [0|0] "" Vector__XXX
 SG_ ErrorCode : 0|16@1+ (1,0) [0|0] "" Vector__XXX

BO_ 1882 HBGuard_090: 1 Vector__XXX
 SG_ Toggle : 7|1@1+ (1,0) [0|0] "" Vector__XXX
 SG_ State : 0|7@1+ (1,0) [0|0] "" Vector__XXX

BO_ 1498 SSDO_090: 8 Vector__XXX

BO_ 1626 CSDO_090: 8 Vector__XXX

BO_ 218 EMCY_090: 8 Vector__XXX
 SG_ ManufacturerSpecific5 : 56|8@1+ (1,0) [0|0] "" Vector__XXX
 SG_ ManufacturerSpecific4 : 48|8@1+ (1,0) [0|0] "" Vector__XXX
 SG_ ManufacturerSpecific3 : 40|8@1+ (1,0) [0|0] "" Vector__XXX
 SG_ ManufacturerSpecific2 : 32|8@1+ (1,0) [0|0] "" Vector__XXX
 SG_ ManufacturerSpecific1 : 24|8@1+ (1,0) [0|0] "" Vector__XXX
 SG_ ErrorRegisterManufSpecific : 23|1@1+ (1,0) [0|0] "" Vector__XXX
 SG_ ErrorRegisterReserved : 22|1@1+ (1,0) [0|0] "" Vector__XXX
 SG_ ErrorRegisterProfileSpecific : 21|1@1+ (1,0) [0|0] "" Vector__XXX
 SG_ ErrorRegisterCommunication : 20|1@1+ (1,0) [0|0] "" Vector__XXX
 SG_ ErrorRegisterTemperature : 19|1@1+ (1,0) [0|0] "" Vector__XXX
 SG_ ErrorRegisterVoltage : 18|1@1+ (1,0) [0|0] "" Vector__XXX
 SG_ ErrorRegisterCurrent : 17|1@1+ (1,0) [0|0] "" Vector__XXX
 SG_ ErrorRegisterGeneric : 16|1@1+ (1,0) [0|0] "" Vector__XXX
 SG_ ErrorCode : 0|16@1+ (1,0) [0|0] "" Vector__XXX

BO_ 1881 HBGuard_089: 1 Vector__XXX
 SG_ Toggle : 7|1@1+ (1,0) [0|0] "" Vector__XXX
 SG_ State : 0|7@1+ (1,0) [0|0] "" Vector__XXX

BO_ 1497 SSDO_089: 8 Vector__XXX

BO_ 1625 CSDO_089: 8 Vector__XXX

BO_ 217 EMCY_089: 8 Vector__XXX
 SG_ ManufacturerSpecific5 : 56|8@1+ (1,0) [0|0] "" Vector__XXX
 SG_ ManufacturerSpecific4 : 48|8@1+ (1,0) [0|0] "" Vector__XXX
 SG_ ManufacturerSpecific3 : 40|8@1+ (1,0) [0|0] "" Vector__XXX
 SG_ ManufacturerSpecific2 : 32|8@1+ (1,0) [0|0] "" Vector__XXX
 SG_ ManufacturerSpecific1 : 24|8@1+ (1,0) [0|0] "" Vector__XXX
 SG_ ErrorRegisterManufSpecific : 23|1@1+ (1,0) [0|0] "" Vector__XXX
 SG_ ErrorRegisterReserved : 22|1@1+ (1,0) [0|0] "" Vector__XXX
 SG_ ErrorRegisterProfileSpecific : 21|1@1+ (1,0) [0|0] "" Vector__XXX
 SG_ ErrorRegisterCommunication : 20|1@1+ (1,0) [0|0] "" Vector__XXX
 SG_ ErrorRegisterTemperature : 19|1@1+ (1,0) [0|0] "" Vector__XXX
 SG_ ErrorRegisterVoltage : 18|1@1+ (1,0) [0|0] "" Vector__XXX
 SG_ ErrorRegisterCurrent : 17|1@1+ (1,0) [0|0] "" Vector__XXX
 SG_ ErrorRegisterGeneric : 16|1@1+ (1,0) [0|0] "" Vector__XXX
 SG_ ErrorCode : 0|16@1+ (1,0) [0|0] "" Vector__XXX

BO_ 1880 HBGuard_088: 1 Vector__XXX
 SG_ Toggle : 7|1@1+ (1,0) [0|0] "" Vector__XXX
 SG_ State : 0|7@1+ (1,0) [0|0] "" Vector__XXX

BO_ 1496 SSDO_088: 8 Vector__XXX

BO_ 1624 CSDO_088: 8 Vector__XXX

BO_ 216 EMCY_088: 8 Vector__XXX
 SG_ ManufacturerSpecific5 : 56|8@1+ (1,0) [0|0] "" Vector__XXX
 SG_ ManufacturerSpecific4 : 48|8@1+ (1,0) [0|0] "" Vector__XXX
 SG_ ManufacturerSpecific3 : 40|8@1+ (1,0) [0|0] "" Vector__XXX
 SG_ ManufacturerSpecific2 : 32|8@1+ (1,0) [0|0] "" Vector__XXX
 SG_ ManufacturerSpecific1 : 24|8@1+ (1,0) [0|0] "" Vector__XXX
 SG_ ErrorRegisterManufSpecific : 23|1@1+ (1,0) [0|0] "" Vector__XXX
 SG_ ErrorRegisterReserved : 22|1@1+ (1,0) [0|0] "" Vector__XXX
 SG_ ErrorRegisterProfileSpecific : 21|1@1+ (1,0) [0|0] "" Vector__XXX
 SG_ ErrorRegisterCommunication : 20|1@1+ (1,0) [0|0] "" Vector__XXX
 SG_ ErrorRegisterTemperature : 19|1@1+ (1,0) [0|0] "" Vector__XXX
 SG_ ErrorRegisterVoltage : 18|1@1+ (1,0) [0|0] "" Vector__XXX
 SG_ ErrorRegisterCurrent : 17|1@1+ (1,0) [0|0] "" Vector__XXX
 SG_ ErrorRegisterGeneric : 16|1@1+ (1,0) [0|0] "" Vector__XXX
 SG_ ErrorCode : 0|16@1+ (1,0) [0|0] "" Vector__XXX

BO_ 1879 HBGuard_087: 1 Vector__XXX
 SG_ Toggle : 7|1@1+ (1,0) [0|0] "" Vector__XXX
 SG_ State : 0|7@1+ (1,0) [0|0] "" Vector__XXX

BO_ 1495 SSDO_087: 8 Vector__XXX

BO_ 1623 CSDO_087: 8 Vector__XXX

BO_ 215 EMCY_087: 8 Vector__XXX
 SG_ ManufacturerSpecific5 : 56|8@1+ (1,0) [0|0] "" Vector__XXX
 SG_ ManufacturerSpecific4 : 48|8@1+ (1,0) [0|0] "" Vector__XXX
 SG_ ManufacturerSpecific3 : 40|8@1+ (1,0) [0|0] "" Vector__XXX
 SG_ ManufacturerSpecific2 : 32|8@1+ (1,0) [0|0] "" Vector__XXX
 SG_ ManufacturerSpecific1 : 24|8@1+ (1,0) [0|0] "" Vector__XXX
 SG_ ErrorRegisterManufSpecific : 23|1@1+ (1,0) [0|0] "" Vector__XXX
 SG_ ErrorRegisterReserved : 22|1@1+ (1,0) [0|0] "" Vector__XXX
 SG_ ErrorRegisterProfileSpecific : 21|1@1+ (1,0) [0|0] "" Vector__XXX
 SG_ ErrorRegisterCommunication : 20|1@1+ (1,0) [0|0] "" Vector__XXX
 SG_ ErrorRegisterTemperature : 19|1@1+ (1,0) [0|0] "" Vector__XXX
 SG_ ErrorRegisterVoltage : 18|1@1+ (1,0) [0|0] "" Vector__XXX
 SG_ ErrorRegisterCurrent : 17|1@1+ (1,0) [0|0] "" Vector__XXX
 SG_ ErrorRegisterGeneric : 16|1@1+ (1,0) [0|0] "" Vector__XXX
 SG_ ErrorCode : 0|16@1+ (1,0) [0|0] "" Vector__XXX

BO_ 1878 HBGuard_086: 1 Vector__XXX
 SG_ Toggle : 7|1@1+ (1,0) [0|0] "" Vector__XXX
 SG_ State : 0|7@1+ (1,0) [0|0] "" Vector__XXX

BO_ 1494 SSDO_086: 8 Vector__XXX

BO_ 1622 CSDO_086: 8 Vector__XXX

BO_ 214 EMCY_086: 8 Vector__XXX
 SG_ ManufacturerSpecific5 : 56|8@1+ (1,0) [0|0] "" Vector__XXX
 SG_ ManufacturerSpecific4 : 48|8@1+ (1,0) [0|0] "" Vector__XXX
 SG_ ManufacturerSpecific3 : 40|8@1+ (1,0) [0|0] "" Vector__XXX
 SG_ ManufacturerSpecific2 : 32|8@1+ (1,0) [0|0] "" Vector__XXX
 SG_ ManufacturerSpecific1 : 24|8@1+ (1,0) [0|0] "" Vector__XXX
 SG_ ErrorRegisterManufSpecific : 23|1@1+ (1,0) [0|0] "" Vector__XXX
 SG_ ErrorRegisterReserved : 22|1@1+ (1,0) [0|0] "" Vector__XXX
 SG_ ErrorRegisterProfileSpecific : 21|1@1+ (1,0) [0|0] "" Vector__XXX
 SG_ ErrorRegisterCommunication : 20|1@1+ (1,0) [0|0] "" Vector__XXX
 SG_ ErrorRegisterTemperature : 19|1@1+ (1,0) [0|0] "" Vector__XXX
 SG_ ErrorRegisterVoltage : 18|1@1+ (1,0) [0|0] "" Vector__XXX
 SG_ ErrorRegisterCurrent : 17|1@1+ (1,0) [0|0] "" Vector__XXX
 SG_ ErrorRegisterGeneric : 16|1@1+ (1,0) [0|0] "" Vector__XXX
 SG_ ErrorCode : 0|16@1+ (1,0) [0|0] "" Vector__XXX

BO_ 1877 HBGuard_085: 1 Vector__XXX
 SG_ Toggle : 7|1@1+ (1,0) [0|0] "" Vector__XXX
 SG_ State : 0|7@1+ (1,0) [0|0] "" Vector__XXX

BO_ 1493 SSDO_085: 8 Vector__XXX

BO_ 1621 CSDO_085: 8 Vector__XXX

BO_ 213 EMCY_085: 8 Vector__XXX
 SG_ ManufacturerSpecific5 : 56|8@1+ (1,0) [0|0] "" Vector__XXX
 SG_ ManufacturerSpecific4 : 48|8@1+ (1,0) [0|0] "" Vector__XXX
 SG_ ManufacturerSpecific3 : 40|8@1+ (1,0) [0|0] "" Vector__XXX
 SG_ ManufacturerSpecific2 : 32|8@1+ (1,0) [0|0] "" Vector__XXX
 SG_ ManufacturerSpecific1 : 24|8@1+ (1,0) [0|0] "" Vector__XXX
 SG_ ErrorRegisterManufSpecific : 23|1@1+ (1,0) [0|0] "" Vector__XXX
 SG_ ErrorRegisterReserved : 22|1@1+ (1,0) [0|0] "" Vector__XXX
 SG_ ErrorRegisterProfileSpecific : 21|1@1+ (1,0) [0|0] "" Vector__XXX
 SG_ ErrorRegisterCommunication : 20|1@1+ (1,0) [0|0] "" Vector__XXX
 SG_ ErrorRegisterTemperature : 19|1@1+ (1,0) [0|0] "" Vector__XXX
 SG_ ErrorRegisterVoltage : 18|1@1+ (1,0) [0|0] "" Vector__XXX
 SG_ ErrorRegisterCurrent : 17|1@1+ (1,0) [0|0] "" Vector__XXX
 SG_ ErrorRegisterGeneric : 16|1@1+ (1,0) [0|0] "" Vector__XXX
 SG_ ErrorCode : 0|16@1+ (1,0) [0|0] "" Vector__XXX

BO_ 1876 HBGuard_084: 1 Vector__XXX
 SG_ Toggle : 7|1@1+ (1,0) [0|0] "" Vector__XXX
 SG_ State : 0|7@1+ (1,0) [0|0] "" Vector__XXX

BO_ 1492 SSDO_084: 8 Vector__XXX

BO_ 1620 CSDO_084: 8 Vector__XXX

BO_ 212 EMCY_084: 8 Vector__XXX
 SG_ ManufacturerSpecific5 : 56|8@1+ (1,0) [0|0] "" Vector__XXX
 SG_ ManufacturerSpecific4 : 48|8@1+ (1,0) [0|0] "" Vector__XXX
 SG_ ManufacturerSpecific3 : 40|8@1+ (1,0) [0|0] "" Vector__XXX
 SG_ ManufacturerSpecific2 : 32|8@1+ (1,0) [0|0] "" Vector__XXX
 SG_ ManufacturerSpecific1 : 24|8@1+ (1,0) [0|0] "" Vector__XXX
 SG_ ErrorRegisterManufSpecific : 23|1@1+ (1,0) [0|0] "" Vector__XXX
 SG_ ErrorRegisterReserved : 22|1@1+ (1,0) [0|0] "" Vector__XXX
 SG_ ErrorRegisterProfileSpecific : 21|1@1+ (1,0) [0|0] "" Vector__XXX
 SG_ ErrorRegisterCommunication : 20|1@1+ (1,0) [0|0] "" Vector__XXX
 SG_ ErrorRegisterTemperature : 19|1@1+ (1,0) [0|0] "" Vector__XXX
 SG_ ErrorRegisterVoltage : 18|1@1+ (1,0) [0|0] "" Vector__XXX
 SG_ ErrorRegisterCurrent : 17|1@1+ (1,0) [0|0] "" Vector__XXX
 SG_ ErrorRegisterGeneric : 16|1@1+ (1,0) [0|0] "" Vector__XXX
 SG_ ErrorCode : 0|16@1+ (1,0) [0|0] "" Vector__XXX

BO_ 1875 HBGuard_083: 1 Vector__XXX
 SG_ Toggle : 7|1@1+ (1,0) [0|0] "" Vector__XXX
 SG_ State : 0|7@1+ (1,0) [0|0] "" Vector__XXX

BO_ 1491 SSDO_083: 8 Vector__XXX

BO_ 1619 CSDO_083: 8 Vector__XXX

BO_ 211 EMCY_083: 8 Vector__XXX
 SG_ ManufacturerSpecific5 : 56|8@1+ (1,0) [0|0] "" Vector__XXX
 SG_ ManufacturerSpecific4 : 48|8@1+ (1,0) [0|0] "" Vector__XXX
 SG_ ManufacturerSpecific3 : 40|8@1+ (1,0) [0|0] "" Vector__XXX
 SG_ ManufacturerSpecific2 : 32|8@1+ (1,0) [0|0] "" Vector__XXX
 SG_ ManufacturerSpecific1 : 24|8@1+ (1,0) [0|0] "" Vector__XXX
 SG_ ErrorRegisterManufSpecific : 23|1@1+ (1,0) [0|0] "" Vector__XXX
 SG_ ErrorRegisterReserved : 22|1@1+ (1,0) [0|0] "" Vector__XXX
 SG_ ErrorRegisterProfileSpecific : 21|1@1+ (1,0) [0|0] "" Vector__XXX
 SG_ ErrorRegisterCommunication : 20|1@1+ (1,0) [0|0] "" Vector__XXX
 SG_ ErrorRegisterTemperature : 19|1@1+ (1,0) [0|0] "" Vector__XXX
 SG_ ErrorRegisterVoltage : 18|1@1+ (1,0) [0|0] "" Vector__XXX
 SG_ ErrorRegisterCurrent : 17|1@1+ (1,0) [0|0] "" Vector__XXX
 SG_ ErrorRegisterGeneric : 16|1@1+ (1,0) [0|0] "" Vector__XXX
 SG_ ErrorCode : 0|16@1+ (1,0) [0|0] "" Vector__XXX

BO_ 1874 HBGuard_082: 1 Vector__XXX
 SG_ Toggle : 7|1@1+ (1,0) [0|0] "" Vector__XXX
 SG_ State : 0|7@1+ (1,0) [0|0] "" Vector__XXX

BO_ 1490 SSDO_082: 8 Vector__XXX

BO_ 1618 CSDO_082: 8 Vector__XXX

BO_ 210 EMCY_082: 8 Vector__XXX
 SG_ ManufacturerSpecific5 : 56|8@1+ (1,0) [0|0] "" Vector__XXX
 SG_ ManufacturerSpecific4 : 48|8@1+ (1,0) [0|0] "" Vector__XXX
 SG_ ManufacturerSpecific3 : 40|8@1+ (1,0) [0|0] "" Vector__XXX
 SG_ ManufacturerSpecific2 : 32|8@1+ (1,0) [0|0] "" Vector__XXX
 SG_ ManufacturerSpecific1 : 24|8@1+ (1,0) [0|0] "" Vector__XXX
 SG_ ErrorRegisterManufSpecific : 23|1@1+ (1,0) [0|0] "" Vector__XXX
 SG_ ErrorRegisterReserved : 22|1@1+ (1,0) [0|0] "" Vector__XXX
 SG_ ErrorRegisterProfileSpecific : 21|1@1+ (1,0) [0|0] "" Vector__XXX
 SG_ ErrorRegisterCommunication : 20|1@1+ (1,0) [0|0] "" Vector__XXX
 SG_ ErrorRegisterTemperature : 19|1@1+ (1,0) [0|0] "" Vector__XXX
 SG_ ErrorRegisterVoltage : 18|1@1+ (1,0) [0|0] "" Vector__XXX
 SG_ ErrorRegisterCurrent : 17|1@1+ (1,0) [0|0] "" Vector__XXX
 SG_ ErrorRegisterGeneric : 16|1@1+ (1,0) [0|0] "" Vector__XXX
 SG_ ErrorCode : 0|16@1+ (1,0) [0|0] "" Vector__XXX

BO_ 1873 HBGuard_081: 1 Vector__XXX
 SG_ Toggle : 7|1@1+ (1,0) [0|0] "" Vector__XXX
 SG_ State : 0|7@1+ (1,0) [0|0] "" Vector__XXX

BO_ 1489 SSDO_081: 8 Vector__XXX

BO_ 1617 CSDO_081: 8 Vector__XXX

BO_ 209 EMCY_081: 8 Vector__XXX
 SG_ ManufacturerSpecific5 : 56|8@1+ (1,0) [0|0] "" Vector__XXX
 SG_ ManufacturerSpecific4 : 48|8@1+ (1,0) [0|0] "" Vector__XXX
 SG_ ManufacturerSpecific3 : 40|8@1+ (1,0) [0|0] "" Vector__XXX
 SG_ ManufacturerSpecific2 : 32|8@1+ (1,0) [0|0] "" Vector__XXX
 SG_ ManufacturerSpecific1 : 24|8@1+ (1,0) [0|0] "" Vector__XXX
 SG_ ErrorRegisterManufSpecific : 23|1@1+ (1,0) [0|0] "" Vector__XXX
 SG_ ErrorRegisterReserved : 22|1@1+ (1,0) [0|0] "" Vector__XXX
 SG_ ErrorRegisterProfileSpecific : 21|1@1+ (1,0) [0|0] "" Vector__XXX
 SG_ ErrorRegisterCommunication : 20|1@1+ (1,0) [0|0] "" Vector__XXX
 SG_ ErrorRegisterTemperature : 19|1@1+ (1,0) [0|0] "" Vector__XXX
 SG_ ErrorRegisterVoltage : 18|1@1+ (1,0) [0|0] "" Vector__XXX
 SG_ ErrorRegisterCurrent : 17|1@1+ (1,0) [0|0] "" Vector__XXX
 SG_ ErrorRegisterGeneric : 16|1@1+ (1,0) [0|0] "" Vector__XXX
 SG_ ErrorCode : 0|16@1+ (1,0) [0|0] "" Vector__XXX

BO_ 1872 HBGuard_080: 1 Vector__XXX
 SG_ Toggle : 7|1@1+ (1,0) [0|0] "" Vector__XXX
 SG_ State : 0|7@1+ (1,0) [0|0] "" Vector__XXX

BO_ 1488 SSDO_080: 8 Vector__XXX

BO_ 1616 CSDO_080: 8 Vector__XXX

BO_ 208 EMCY_080: 8 Vector__XXX
 SG_ ManufacturerSpecific5 : 56|8@1+ (1,0) [0|0] "" Vector__XXX
 SG_ ManufacturerSpecific4 : 48|8@1+ (1,0) [0|0] "" Vector__XXX
 SG_ ManufacturerSpecific3 : 40|8@1+ (1,0) [0|0] "" Vector__XXX
 SG_ ManufacturerSpecific2 : 32|8@1+ (1,0) [0|0] "" Vector__XXX
 SG_ ManufacturerSpecific1 : 24|8@1+ (1,0) [0|0] "" Vector__XXX
 SG_ ErrorRegisterManufSpecific : 23|1@1+ (1,0) [0|0] "" Vector__XXX
 SG_ ErrorRegisterReserved : 22|1@1+ (1,0) [0|0] "" Vector__XXX
 SG_ ErrorRegisterProfileSpecific : 21|1@1+ (1,0) [0|0] "" Vector__XXX
 SG_ ErrorRegisterCommunication : 20|1@1+ (1,0) [0|0] "" Vector__XXX
 SG_ ErrorRegisterTemperature : 19|1@1+ (1,0) [0|0] "" Vector__XXX
 SG_ ErrorRegisterVoltage : 18|1@1+ (1,0) [0|0] "" Vector__XXX
 SG_ ErrorRegisterCurrent : 17|1@1+ (1,0) [0|0] "" Vector__XXX
 SG_ ErrorRegisterGeneric : 16|1@1+ (1,0) [0|0] "" Vector__XXX
 SG_ ErrorCode : 0|16@1+ (1,0) [0|0] "" Vector__XXX

BO_ 1871 HBGuard_079: 1 Vector__XXX
 SG_ Toggle : 7|1@1+ (1,0) [0|0] "" Vector__XXX
 SG_ State : 0|7@1+ (1,0) [0|0] "" Vector__XXX

BO_ 1487 SSDO_079: 8 Vector__XXX

BO_ 1615 CSDO_079: 8 Vector__XXX

BO_ 207 EMCY_079: 8 Vector__XXX
 SG_ ManufacturerSpecific5 : 56|8@1+ (1,0) [0|0] "" Vector__XXX
 SG_ ManufacturerSpecific4 : 48|8@1+ (1,0) [0|0] "" Vector__XXX
 SG_ ManufacturerSpecific3 : 40|8@1+ (1,0) [0|0] "" Vector__XXX
 SG_ ManufacturerSpecific2 : 32|8@1+ (1,0) [0|0] "" Vector__XXX
 SG_ ManufacturerSpecific1 : 24|8@1+ (1,0) [0|0] "" Vector__XXX
 SG_ ErrorRegisterManufSpecific : 23|1@1+ (1,0) [0|0] "" Vector__XXX
 SG_ ErrorRegisterReserved : 22|1@1+ (1,0) [0|0] "" Vector__XXX
 SG_ ErrorRegisterProfileSpecific : 21|1@1+ (1,0) [0|0] "" Vector__XXX
 SG_ ErrorRegisterCommunication : 20|1@1+ (1,0) [0|0] "" Vector__XXX
 SG_ ErrorRegisterTemperature : 19|1@1+ (1,0) [0|0] "" Vector__XXX
 SG_ ErrorRegisterVoltage : 18|1@1+ (1,0) [0|0] "" Vector__XXX
 SG_ ErrorRegisterCurrent : 17|1@1+ (1,0) [0|0] "" Vector__XXX
 SG_ ErrorRegisterGeneric : 16|1@1+ (1,0) [0|0] "" Vector__XXX
 SG_ ErrorCode : 0|16@1+ (1,0) [0|0] "" Vector__XXX

BO_ 1870 HBGuard_078: 1 Vector__XXX
 SG_ Toggle : 7|1@1+ (1,0) [0|0] "" Vector__XXX
 SG_ State : 0|7@1+ (1,0) [0|0] "" Vector__XXX

BO_ 1486 SSDO_078: 8 Vector__XXX

BO_ 1614 CSDO_078: 8 Vector__XXX

BO_ 206 EMCY_078: 8 Vector__XXX
 SG_ ManufacturerSpecific5 : 56|8@1+ (1,0) [0|0] "" Vector__XXX
 SG_ ManufacturerSpecific4 : 48|8@1+ (1,0) [0|0] "" Vector__XXX
 SG_ ManufacturerSpecific3 : 40|8@1+ (1,0) [0|0] "" Vector__XXX
 SG_ ManufacturerSpecific2 : 32|8@1+ (1,0) [0|0] "" Vector__XXX
 SG_ ManufacturerSpecific1 : 24|8@1+ (1,0) [0|0] "" Vector__XXX
 SG_ ErrorRegisterManufSpecific : 23|1@1+ (1,0) [0|0] "" Vector__XXX
 SG_ ErrorRegisterReserved : 22|1@1+ (1,0) [0|0] "" Vector__XXX
 SG_ ErrorRegisterProfileSpecific : 21|1@1+ (1,0) [0|0] "" Vector__XXX
 SG_ ErrorRegisterCommunication : 20|1@1+ (1,0) [0|0] "" Vector__XXX
 SG_ ErrorRegisterTemperature : 19|1@1+ (1,0) [0|0] "" Vector__XXX
 SG_ ErrorRegisterVoltage : 18|1@1+ (1,0) [0|0] "" Vector__XXX
 SG_ ErrorRegisterCurrent : 17|1@1+ (1,0) [0|0] "" Vector__XXX
 SG_ ErrorRegisterGeneric : 16|1@1+ (1,0) [0|0] "" Vector__XXX
 SG_ ErrorCode : 0|16@1+ (1,0) [0|0] "" Vector__XXX

BO_ 1869 HBGuard_077: 1 Vector__XXX
 SG_ Toggle : 7|1@1+ (1,0) [0|0] "" Vector__XXX
 SG_ State : 0|7@1+ (1,0) [0|0] "" Vector__XXX

BO_ 1485 SSDO_077: 8 Vector__XXX

BO_ 1613 CSDO_077: 8 Vector__XXX

BO_ 205 EMCY_077: 8 Vector__XXX
 SG_ ManufacturerSpecific5 : 56|8@1+ (1,0) [0|0] "" Vector__XXX
 SG_ ManufacturerSpecific4 : 48|8@1+ (1,0) [0|0] "" Vector__XXX
 SG_ ManufacturerSpecific3 : 40|8@1+ (1,0) [0|0] "" Vector__XXX
 SG_ ManufacturerSpecific2 : 32|8@1+ (1,0) [0|0] "" Vector__XXX
 SG_ ManufacturerSpecific1 : 24|8@1+ (1,0) [0|0] "" Vector__XXX
 SG_ ErrorRegisterManufSpecific : 23|1@1+ (1,0) [0|0] "" Vector__XXX
 SG_ ErrorRegisterReserved : 22|1@1+ (1,0) [0|0] "" Vector__XXX
 SG_ ErrorRegisterProfileSpecific : 21|1@1+ (1,0) [0|0] "" Vector__XXX
 SG_ ErrorRegisterCommunication : 20|1@1+ (1,0) [0|0] "" Vector__XXX
 SG_ ErrorRegisterTemperature : 19|1@1+ (1,0) [0|0] "" Vector__XXX
 SG_ ErrorRegisterVoltage : 18|1@1+ (1,0) [0|0] "" Vector__XXX
 SG_ ErrorRegisterCurrent : 17|1@1+ (1,0) [0|0] "" Vector__XXX
 SG_ ErrorRegisterGeneric : 16|1@1+ (1,0) [0|0] "" Vector__XXX
 SG_ ErrorCode : 0|16@1+ (1,0) [0|0] "" Vector__XXX

BO_ 1868 HBGuard_076: 1 Vector__XXX
 SG_ Toggle : 7|1@1+ (1,0) [0|0] "" Vector__XXX
 SG_ State : 0|7@1+ (1,0) [0|0] "" Vector__XXX

BO_ 1484 SSDO_076: 8 Vector__XXX

BO_ 1612 CSDO_076: 8 Vector__XXX

BO_ 204 EMCY_076: 8 Vector__XXX
 SG_ ManufacturerSpecific5 : 56|8@1+ (1,0) [0|0] "" Vector__XXX
 SG_ ManufacturerSpecific4 : 48|8@1+ (1,0) [0|0] "" Vector__XXX
 SG_ ManufacturerSpecific3 : 40|8@1+ (1,0) [0|0] "" Vector__XXX
 SG_ ManufacturerSpecific2 : 32|8@1+ (1,0) [0|0] "" Vector__XXX
 SG_ ManufacturerSpecific1 : 24|8@1+ (1,0) [0|0] "" Vector__XXX
 SG_ ErrorRegisterManufSpecific : 23|1@1+ (1,0) [0|0] "" Vector__XXX
 SG_ ErrorRegisterReserved : 22|1@1+ (1,0) [0|0] "" Vector__XXX
 SG_ ErrorRegisterProfileSpecific : 21|1@1+ (1,0) [0|0] "" Vector__XXX
 SG_ ErrorRegisterCommunication : 20|1@1+ (1,0) [0|0] "" Vector__XXX
 SG_ ErrorRegisterTemperature : 19|1@1+ (1,0) [0|0] "" Vector__XXX
 SG_ ErrorRegisterVoltage : 18|1@1+ (1,0) [0|0] "" Vector__XXX
 SG_ ErrorRegisterCurrent : 17|1@1+ (1,0) [0|0] "" Vector__XXX
 SG_ ErrorRegisterGeneric : 16|1@1+ (1,0) [0|0] "" Vector__XXX
 SG_ ErrorCode : 0|16@1+ (1,0) [0|0] "" Vector__XXX

BO_ 1867 HBGuard_075: 1 Vector__XXX
 SG_ Toggle : 7|1@1+ (1,0) [0|0] "" Vector__XXX
 SG_ State : 0|7@1+ (1,0) [0|0] "" Vector__XXX

BO_ 1483 SSDO_075: 8 Vector__XXX

BO_ 1611 CSDO_075: 8 Vector__XXX

BO_ 203 EMCY_075: 8 Vector__XXX
 SG_ ManufacturerSpecific5 : 56|8@1+ (1,0) [0|0] "" Vector__XXX
 SG_ ManufacturerSpecific4 : 48|8@1+ (1,0) [0|0] "" Vector__XXX
 SG_ ManufacturerSpecific3 : 40|8@1+ (1,0) [0|0] "" Vector__XXX
 SG_ ManufacturerSpecific2 : 32|8@1+ (1,0) [0|0] "" Vector__XXX
 SG_ ManufacturerSpecific1 : 24|8@1+ (1,0) [0|0] "" Vector__XXX
 SG_ ErrorRegisterManufSpecific : 23|1@1+ (1,0) [0|0] "" Vector__XXX
 SG_ ErrorRegisterReserved : 22|1@1+ (1,0) [0|0] "" Vector__XXX
 SG_ ErrorRegisterProfileSpecific : 21|1@1+ (1,0) [0|0] "" Vector__XXX
 SG_ ErrorRegisterCommunication : 20|1@1+ (1,0) [0|0] "" Vector__XXX
 SG_ ErrorRegisterTemperature : 19|1@1+ (1,0) [0|0] "" Vector__XXX
 SG_ ErrorRegisterVoltage : 18|1@1+ (1,0) [0|0] "" Vector__XXX
 SG_ ErrorRegisterCurrent : 17|1@1+ (1,0) [0|0] "" Vector__XXX
 SG_ ErrorRegisterGeneric : 16|1@1+ (1,0) [0|0] "" Vector__XXX
 SG_ ErrorCode : 0|16@1+ (1,0) [0|0] "" Vector__XXX

BO_ 1866 HBGuard_074: 1 Vector__XXX
 SG_ Toggle : 7|1@1+ (1,0) [0|0] "" Vector__XXX
 SG_ State : 0|7@1+ (1,0) [0|0] "" Vector__XXX

BO_ 1482 SSDO_074: 8 Vector__XXX

BO_ 1610 CSDO_074: 8 Vector__XXX

BO_ 202 EMCY_074: 8 Vector__XXX
 SG_ ManufacturerSpecific5 : 56|8@1+ (1,0) [0|0] "" Vector__XXX
 SG_ ManufacturerSpecific4 : 48|8@1+ (1,0) [0|0] "" Vector__XXX
 SG_ ManufacturerSpecific3 : 40|8@1+ (1,0) [0|0] "" Vector__XXX
 SG_ ManufacturerSpecific2 : 32|8@1+ (1,0) [0|0] "" Vector__XXX
 SG_ ManufacturerSpecific1 : 24|8@1+ (1,0) [0|0] "" Vector__XXX
 SG_ ErrorRegisterManufSpecific : 23|1@1+ (1,0) [0|0] "" Vector__XXX
 SG_ ErrorRegisterReserved : 22|1@1+ (1,0) [0|0] "" Vector__XXX
 SG_ ErrorRegisterProfileSpecific : 21|1@1+ (1,0) [0|0] "" Vector__XXX
 SG_ ErrorRegisterCommunication : 20|1@1+ (1,0) [0|0] "" Vector__XXX
 SG_ ErrorRegisterTemperature : 19|1@1+ (1,0) [0|0] "" Vector__XXX
 SG_ ErrorRegisterVoltage : 18|1@1+ (1,0) [0|0] "" Vector__XXX
 SG_ ErrorRegisterCurrent : 17|1@1+ (1,0) [0|0] "" Vector__XXX
 SG_ ErrorRegisterGeneric : 16|1@1+ (1,0) [0|0] "" Vector__XXX
 SG_ ErrorCode : 0|16@1+ (1,0) [0|0] "" Vector__XXX

BO_ 1865 HBGuard_073: 1 Vector__XXX
 SG_ Toggle : 7|1@1+ (1,0) [0|0] "" Vector__XXX
 SG_ State : 0|7@1+ (1,0) [0|0] "" Vector__XXX

BO_ 1481 SSDO_073: 8 Vector__XXX

BO_ 1609 CSDO_073: 8 Vector__XXX

BO_ 201 EMCY_073: 8 Vector__XXX
 SG_ ManufacturerSpecific5 : 56|8@1+ (1,0) [0|0] "" Vector__XXX
 SG_ ManufacturerSpecific4 : 48|8@1+ (1,0) [0|0] "" Vector__XXX
 SG_ ManufacturerSpecific3 : 40|8@1+ (1,0) [0|0] "" Vector__XXX
 SG_ ManufacturerSpecific2 : 32|8@1+ (1,0) [0|0] "" Vector__XXX
 SG_ ManufacturerSpecific1 : 24|8@1+ (1,0) [0|0] "" Vector__XXX
 SG_ ErrorRegisterManufSpecific : 23|1@1+ (1,0) [0|0] "" Vector__XXX
 SG_ ErrorRegisterReserved : 22|1@1+ (1,0) [0|0] "" Vector__XXX
 SG_ ErrorRegisterProfileSpecific : 21|1@1+ (1,0) [0|0] "" Vector__XXX
 SG_ ErrorRegisterCommunication : 20|1@1+ (1,0) [0|0] "" Vector__XXX
 SG_ ErrorRegisterTemperature : 19|1@1+ (1,0) [0|0] "" Vector__XXX
 SG_ ErrorRegisterVoltage : 18|1@1+ (1,0) [0|0] "" Vector__XXX
 SG_ ErrorRegisterCurrent : 17|1@1+ (1,0) [0|0] "" Vector__XXX
 SG_ ErrorRegisterGeneric : 16|1@1+ (1,0) [0|0] "" Vector__XXX
 SG_ ErrorCode : 0|16@1+ (1,0) [0|0] "" Vector__XXX

BO_ 1864 HBGuard_072: 1 Vector__XXX
 SG_ Toggle : 7|1@1+ (1,0) [0|0] "" Vector__XXX
 SG_ State : 0|7@1+ (1,0) [0|0] "" Vector__XXX

BO_ 1480 SSDO_072: 8 Vector__XXX

BO_ 1608 CSDO_072: 8 Vector__XXX

BO_ 200 EMCY_072: 8 Vector__XXX
 SG_ ManufacturerSpecific5 : 56|8@1+ (1,0) [0|0] "" Vector__XXX
 SG_ ManufacturerSpecific4 : 48|8@1+ (1,0) [0|0] "" Vector__XXX
 SG_ ManufacturerSpecific3 : 40|8@1+ (1,0) [0|0] "" Vector__XXX
 SG_ ManufacturerSpecific2 : 32|8@1+ (1,0) [0|0] "" Vector__XXX
 SG_ ManufacturerSpecific1 : 24|8@1+ (1,0) [0|0] "" Vector__XXX
 SG_ ErrorRegisterManufSpecific : 23|1@1+ (1,0) [0|0] "" Vector__XXX
 SG_ ErrorRegisterReserved : 22|1@1+ (1,0) [0|0] "" Vector__XXX
 SG_ ErrorRegisterProfileSpecific : 21|1@1+ (1,0) [0|0] "" Vector__XXX
 SG_ ErrorRegisterCommunication : 20|1@1+ (1,0) [0|0] "" Vector__XXX
 SG_ ErrorRegisterTemperature : 19|1@1+ (1,0) [0|0] "" Vector__XXX
 SG_ ErrorRegisterVoltage : 18|1@1+ (1,0) [0|0] "" Vector__XXX
 SG_ ErrorRegisterCurrent : 17|1@1+ (1,0) [0|0] "" Vector__XXX
 SG_ ErrorRegisterGeneric : 16|1@1+ (1,0) [0|0] "" Vector__XXX
 SG_ ErrorCode : 0|16@1+ (1,0) [0|0] "" Vector__XXX

BO_ 1863 HBGuard_071: 1 Vector__XXX
 SG_ Toggle : 7|1@1+ (1,0) [0|0] "" Vector__XXX
 SG_ State : 0|7@1+ (1,0) [0|0] "" Vector__XXX

BO_ 1479 SSDO_071: 8 Vector__XXX

BO_ 1607 CSDO_071: 8 Vector__XXX

BO_ 199 EMCY_071: 8 Vector__XXX
 SG_ ManufacturerSpecific5 : 56|8@1+ (1,0) [0|0] "" Vector__XXX
 SG_ ManufacturerSpecific4 : 48|8@1+ (1,0) [0|0] "" Vector__XXX
 SG_ ManufacturerSpecific3 : 40|8@1+ (1,0) [0|0] "" Vector__XXX
 SG_ ManufacturerSpecific2 : 32|8@1+ (1,0) [0|0] "" Vector__XXX
 SG_ ManufacturerSpecific1 : 24|8@1+ (1,0) [0|0] "" Vector__XXX
 SG_ ErrorRegisterManufSpecific : 23|1@1+ (1,0) [0|0] "" Vector__XXX
 SG_ ErrorRegisterReserved : 22|1@1+ (1,0) [0|0] "" Vector__XXX
 SG_ ErrorRegisterProfileSpecific : 21|1@1+ (1,0) [0|0] "" Vector__XXX
 SG_ ErrorRegisterCommunication : 20|1@1+ (1,0) [0|0] "" Vector__XXX
 SG_ ErrorRegisterTemperature : 19|1@1+ (1,0) [0|0] "" Vector__XXX
 SG_ ErrorRegisterVoltage : 18|1@1+ (1,0) [0|0] "" Vector__XXX
 SG_ ErrorRegisterCurrent : 17|1@1+ (1,0) [0|0] "" Vector__XXX
 SG_ ErrorRegisterGeneric : 16|1@1+ (1,0) [0|0] "" Vector__XXX
 SG_ ErrorCode : 0|16@1+ (1,0) [0|0] "" Vector__XXX

BO_ 1862 HBGuard_070: 1 Vector__XXX
 SG_ Toggle : 7|1@1+ (1,0) [0|0] "" Vector__XXX
 SG_ State : 0|7@1+ (1,0) [0|0] "" Vector__XXX

BO_ 1478 SSDO_070: 8 Vector__XXX

BO_ 1606 CSDO_070: 8 Vector__XXX

BO_ 198 EMCY_070: 8 Vector__XXX
 SG_ ManufacturerSpecific5 : 56|8@1+ (1,0) [0|0] "" Vector__XXX
 SG_ ManufacturerSpecific4 : 48|8@1+ (1,0) [0|0] "" Vector__XXX
 SG_ ManufacturerSpecific3 : 40|8@1+ (1,0) [0|0] "" Vector__XXX
 SG_ ManufacturerSpecific2 : 32|8@1+ (1,0) [0|0] "" Vector__XXX
 SG_ ManufacturerSpecific1 : 24|8@1+ (1,0) [0|0] "" Vector__XXX
 SG_ ErrorRegisterManufSpecific : 23|1@1+ (1,0) [0|0] "" Vector__XXX
 SG_ ErrorRegisterReserved : 22|1@1+ (1,0) [0|0] "" Vector__XXX
 SG_ ErrorRegisterProfileSpecific : 21|1@1+ (1,0) [0|0] "" Vector__XXX
 SG_ ErrorRegisterCommunication : 20|1@1+ (1,0) [0|0] "" Vector__XXX
 SG_ ErrorRegisterTemperature : 19|1@1+ (1,0) [0|0] "" Vector__XXX
 SG_ ErrorRegisterVoltage : 18|1@1+ (1,0) [0|0] "" Vector__XXX
 SG_ ErrorRegisterCurrent : 17|1@1+ (1,0) [0|0] "" Vector__XXX
 SG_ ErrorRegisterGeneric : 16|1@1+ (1,0) [0|0] "" Vector__XXX
 SG_ ErrorCode : 0|16@1+ (1,0) [0|0] "" Vector__XXX

BO_ 1861 HBGuard_069: 1 Vector__XXX
 SG_ Toggle : 7|1@1+ (1,0) [0|0] "" Vector__XXX
 SG_ State : 0|7@1+ (1,0) [0|0] "" Vector__XXX

BO_ 1477 SSDO_069: 8 Vector__XXX

BO_ 1605 CSDO_069: 8 Vector__XXX

BO_ 197 EMCY_069: 8 Vector__XXX
 SG_ ManufacturerSpecific5 : 56|8@1+ (1,0) [0|0] "" Vector__XXX
 SG_ ManufacturerSpecific4 : 48|8@1+ (1,0) [0|0] "" Vector__XXX
 SG_ ManufacturerSpecific3 : 40|8@1+ (1,0) [0|0] "" Vector__XXX
 SG_ ManufacturerSpecific2 : 32|8@1+ (1,0) [0|0] "" Vector__XXX
 SG_ ManufacturerSpecific1 : 24|8@1+ (1,0) [0|0] "" Vector__XXX
 SG_ ErrorRegisterManufSpecific : 23|1@1+ (1,0) [0|0] "" Vector__XXX
 SG_ ErrorRegisterReserved : 22|1@1+ (1,0) [0|0] "" Vector__XXX
 SG_ ErrorRegisterProfileSpecific : 21|1@1+ (1,0) [0|0] "" Vector__XXX
 SG_ ErrorRegisterCommunication : 20|1@1+ (1,0) [0|0] "" Vector__XXX
 SG_ ErrorRegisterTemperature : 19|1@1+ (1,0) [0|0] "" Vector__XXX
 SG_ ErrorRegisterVoltage : 18|1@1+ (1,0) [0|0] "" Vector__XXX
 SG_ ErrorRegisterCurrent : 17|1@1+ (1,0) [0|0] "" Vector__XXX
 SG_ ErrorRegisterGeneric : 16|1@1+ (1,0) [0|0] "" Vector__XXX
 SG_ ErrorCode : 0|16@1+ (1,0) [0|0] "" Vector__XXX

BO_ 1860 HBGuard_068: 1 Vector__XXX
 SG_ Toggle : 7|1@1+ (1,0) [0|0] "" Vector__XXX
 SG_ State : 0|7@1+ (1,0) [0|0] "" Vector__XXX

BO_ 1476 SSDO_068: 8 Vector__XXX

BO_ 1604 CSDO_068: 8 Vector__XXX

BO_ 196 EMCY_068: 8 Vector__XXX
 SG_ ManufacturerSpecific5 : 56|8@1+ (1,0) [0|0] "" Vector__XXX
 SG_ ManufacturerSpecific4 : 48|8@1+ (1,0) [0|0] "" Vector__XXX
 SG_ ManufacturerSpecific3 : 40|8@1+ (1,0) [0|0] "" Vector__XXX
 SG_ ManufacturerSpecific2 : 32|8@1+ (1,0) [0|0] "" Vector__XXX
 SG_ ManufacturerSpecific1 : 24|8@1+ (1,0) [0|0] "" Vector__XXX
 SG_ ErrorRegisterManufSpecific : 23|1@1+ (1,0) [0|0] "" Vector__XXX
 SG_ ErrorRegisterReserved : 22|1@1+ (1,0) [0|0] "" Vector__XXX
 SG_ ErrorRegisterProfileSpecific : 21|1@1+ (1,0) [0|0] "" Vector__XXX
 SG_ ErrorRegisterCommunication : 20|1@1+ (1,0) [0|0] "" Vector__XXX
 SG_ ErrorRegisterTemperature : 19|1@1+ (1,0) [0|0] "" Vector__XXX
 SG_ ErrorRegisterVoltage : 18|1@1+ (1,0) [0|0] "" Vector__XXX
 SG_ ErrorRegisterCurrent : 17|1@1+ (1,0) [0|0] "" Vector__XXX
 SG_ ErrorRegisterGeneric : 16|1@1+ (1,0) [0|0] "" Vector__XXX
 SG_ ErrorCode : 0|16@1+ (1,0) [0|0] "" Vector__XXX

BO_ 1859 HBGuard_067: 1 Vector__XXX
 SG_ Toggle : 7|1@1+ (1,0) [0|0] "" Vector__XXX
 SG_ State : 0|7@1+ (1,0) [0|0] "" Vector__XXX

BO_ 1475 SSDO_067: 8 Vector__XXX

BO_ 1603 CSDO_067: 8 Vector__XXX

BO_ 195 EMCY_067: 8 Vector__XXX
 SG_ ManufacturerSpecific5 : 56|8@1+ (1,0) [0|0] "" Vector__XXX
 SG_ ManufacturerSpecific4 : 48|8@1+ (1,0) [0|0] "" Vector__XXX
 SG_ ManufacturerSpecific3 : 40|8@1+ (1,0) [0|0] "" Vector__XXX
 SG_ ManufacturerSpecific2 : 32|8@1+ (1,0) [0|0] "" Vector__XXX
 SG_ ManufacturerSpecific1 : 24|8@1+ (1,0) [0|0] "" Vector__XXX
 SG_ ErrorRegisterManufSpecific : 23|1@1+ (1,0) [0|0] "" Vector__XXX
 SG_ ErrorRegisterReserved : 22|1@1+ (1,0) [0|0] "" Vector__XXX
 SG_ ErrorRegisterProfileSpecific : 21|1@1+ (1,0) [0|0] "" Vector__XXX
 SG_ ErrorRegisterCommunication : 20|1@1+ (1,0) [0|0] "" Vector__XXX
 SG_ ErrorRegisterTemperature : 19|1@1+ (1,0) [0|0] "" Vector__XXX
 SG_ ErrorRegisterVoltage : 18|1@1+ (1,0) [0|0] "" Vector__XXX
 SG_ ErrorRegisterCurrent : 17|1@1+ (1,0) [0|0] "" Vector__XXX
 SG_ ErrorRegisterGeneric : 16|1@1+ (1,0) [0|0] "" Vector__XXX
 SG_ ErrorCode : 0|16@1+ (1,0) [0|0] "" Vector__XXX

BO_ 1858 HBGuard_066: 1 Vector__XXX
 SG_ Toggle : 7|1@1+ (1,0) [0|0] "" Vector__XXX
 SG_ State : 0|7@1+ (1,0) [0|0] "" Vector__XXX

BO_ 1474 SSDO_066: 8 Vector__XXX

BO_ 1602 CSDO_066: 8 Vector__XXX

BO_ 194 EMCY_066: 8 Vector__XXX
 SG_ ManufacturerSpecific5 : 56|8@1+ (1,0) [0|0] "" Vector__XXX
 SG_ ManufacturerSpecific4 : 48|8@1+ (1,0) [0|0] "" Vector__XXX
 SG_ ManufacturerSpecific3 : 40|8@1+ (1,0) [0|0] "" Vector__XXX
 SG_ ManufacturerSpecific2 : 32|8@1+ (1,0) [0|0] "" Vector__XXX
 SG_ ManufacturerSpecific1 : 24|8@1+ (1,0) [0|0] "" Vector__XXX
 SG_ ErrorRegisterManufSpecific : 23|1@1+ (1,0) [0|0] "" Vector__XXX
 SG_ ErrorRegisterReserved : 22|1@1+ (1,0) [0|0] "" Vector__XXX
 SG_ ErrorRegisterProfileSpecific : 21|1@1+ (1,0) [0|0] "" Vector__XXX
 SG_ ErrorRegisterCommunication : 20|1@1+ (1,0) [0|0] "" Vector__XXX
 SG_ ErrorRegisterTemperature : 19|1@1+ (1,0) [0|0] "" Vector__XXX
 SG_ ErrorRegisterVoltage : 18|1@1+ (1,0) [0|0] "" Vector__XXX
 SG_ ErrorRegisterCurrent : 17|1@1+ (1,0) [0|0] "" Vector__XXX
 SG_ ErrorRegisterGeneric : 16|1@1+ (1,0) [0|0] "" Vector__XXX
 SG_ ErrorCode : 0|16@1+ (1,0) [0|0] "" Vector__XXX

BO_ 1857 HBGuard_065: 1 Vector__XXX
 SG_ Toggle : 7|1@1+ (1,0) [0|0] "" Vector__XXX
 SG_ State : 0|7@1+ (1,0) [0|0] "" Vector__XXX

BO_ 1473 SSDO_065: 8 Vector__XXX

BO_ 1601 CSDO_065: 8 Vector__XXX

BO_ 193 EMCY_065: 8 Vector__XXX
 SG_ ManufacturerSpecific5 : 56|8@1+ (1,0) [0|0] "" Vector__XXX
 SG_ ManufacturerSpecific4 : 48|8@1+ (1,0) [0|0] "" Vector__XXX
 SG_ ManufacturerSpecific3 : 40|8@1+ (1,0) [0|0] "" Vector__XXX
 SG_ ManufacturerSpecific2 : 32|8@1+ (1,0) [0|0] "" Vector__XXX
 SG_ ManufacturerSpecific1 : 24|8@1+ (1,0) [0|0] "" Vector__XXX
 SG_ ErrorRegisterManufSpecific : 23|1@1+ (1,0) [0|0] "" Vector__XXX
 SG_ ErrorRegisterReserved : 22|1@1+ (1,0) [0|0] "" Vector__XXX
 SG_ ErrorRegisterProfileSpecific : 21|1@1+ (1,0) [0|0] "" Vector__XXX
 SG_ ErrorRegisterCommunication : 20|1@1+ (1,0) [0|0] "" Vector__XXX
 SG_ ErrorRegisterTemperature : 19|1@1+ (1,0) [0|0] "" Vector__XXX
 SG_ ErrorRegisterVoltage : 18|1@1+ (1,0) [0|0] "" Vector__XXX
 SG_ ErrorRegisterCurrent : 17|1@1+ (1,0) [0|0] "" Vector__XXX
 SG_ ErrorRegisterGeneric : 16|1@1+ (1,0) [0|0] "" Vector__XXX
 SG_ ErrorCode : 0|16@1+ (1,0) [0|0] "" Vector__XXX

BO_ 1856 HBGuard_064: 1 Vector__XXX
 SG_ Toggle : 7|1@1+ (1,0) [0|0] "" Vector__XXX
 SG_ State : 0|7@1+ (1,0) [0|0] "" Vector__XXX

BO_ 1472 SSDO_064: 8 Vector__XXX

BO_ 1600 CSDO_064: 8 Vector__XXX

BO_ 192 EMCY_064: 8 Vector__XXX
 SG_ ManufacturerSpecific5 : 56|8@1+ (1,0) [0|0] "" Vector__XXX
 SG_ ManufacturerSpecific4 : 48|8@1+ (1,0) [0|0] "" Vector__XXX
 SG_ ManufacturerSpecific3 : 40|8@1+ (1,0) [0|0] "" Vector__XXX
 SG_ ManufacturerSpecific2 : 32|8@1+ (1,0) [0|0] "" Vector__XXX
 SG_ ManufacturerSpecific1 : 24|8@1+ (1,0) [0|0] "" Vector__XXX
 SG_ ErrorRegisterManufSpecific : 23|1@1+ (1,0) [0|0] "" Vector__XXX
 SG_ ErrorRegisterReserved : 22|1@1+ (1,0) [0|0] "" Vector__XXX
 SG_ ErrorRegisterProfileSpecific : 21|1@1+ (1,0) [0|0] "" Vector__XXX
 SG_ ErrorRegisterCommunication : 20|1@1+ (1,0) [0|0] "" Vector__XXX
 SG_ ErrorRegisterTemperature : 19|1@1+ (1,0) [0|0] "" Vector__XXX
 SG_ ErrorRegisterVoltage : 18|1@1+ (1,0) [0|0] "" Vector__XXX
 SG_ ErrorRegisterCurrent : 17|1@1+ (1,0) [0|0] "" Vector__XXX
 SG_ ErrorRegisterGeneric : 16|1@1+ (1,0) [0|0] "" Vector__XXX
 SG_ ErrorCode : 0|16@1+ (1,0) [0|0] "" Vector__XXX

BO_ 1855 HBGuard_063: 1 Vector__XXX
 SG_ Toggle : 7|1@1+ (1,0) [0|0] "" Vector__XXX
 SG_ State : 0|7@1+ (1,0) [0|0] "" Vector__XXX

BO_ 1471 SSDO_063: 8 Vector__XXX

BO_ 1599 CSDO_063: 8 Vector__XXX

BO_ 191 EMCY_063: 8 Vector__XXX
 SG_ ManufacturerSpecific5 : 56|8@1+ (1,0) [0|0] "" Vector__XXX
 SG_ ManufacturerSpecific4 : 48|8@1+ (1,0) [0|0] "" Vector__XXX
 SG_ ManufacturerSpecific3 : 40|8@1+ (1,0) [0|0] "" Vector__XXX
 SG_ ManufacturerSpecific2 : 32|8@1+ (1,0) [0|0] "" Vector__XXX
 SG_ ManufacturerSpecific1 : 24|8@1+ (1,0) [0|0] "" Vector__XXX
 SG_ ErrorRegisterManufSpecific : 23|1@1+ (1,0) [0|0] "" Vector__XXX
 SG_ ErrorRegisterReserved : 22|1@1+ (1,0) [0|0] "" Vector__XXX
 SG_ ErrorRegisterProfileSpecific : 21|1@1+ (1,0) [0|0] "" Vector__XXX
 SG_ ErrorRegisterCommunication : 20|1@1+ (1,0) [0|0] "" Vector__XXX
 SG_ ErrorRegisterTemperature : 19|1@1+ (1,0) [0|0] "" Vector__XXX
 SG_ ErrorRegisterVoltage : 18|1@1+ (1,0) [0|0] "" Vector__XXX
 SG_ ErrorRegisterCurrent : 17|1@1+ (1,0) [0|0] "" Vector__XXX
 SG_ ErrorRegisterGeneric : 16|1@1+ (1,0) [0|0] "" Vector__XXX
 SG_ ErrorCode : 0|16@1+ (1,0) [0|0] "" Vector__XXX

BO_ 1854 HBGuard_062: 1 Vector__XXX
 SG_ Toggle : 7|1@1+ (1,0) [0|0] "" Vector__XXX
 SG_ State : 0|7@1+ (1,0) [0|0] "" Vector__XXX

BO_ 1470 SSDO_062: 8 Vector__XXX

BO_ 1598 CSDO_062: 8 Vector__XXX

BO_ 190 EMCY_062: 8 Vector__XXX
 SG_ ManufacturerSpecific5 : 56|8@1+ (1,0) [0|0] "" Vector__XXX
 SG_ ManufacturerSpecific4 : 48|8@1+ (1,0) [0|0] "" Vector__XXX
 SG_ ManufacturerSpecific3 : 40|8@1+ (1,0) [0|0] "" Vector__XXX
 SG_ ManufacturerSpecific2 : 32|8@1+ (1,0) [0|0] "" Vector__XXX
 SG_ ManufacturerSpecific1 : 24|8@1+ (1,0) [0|0] "" Vector__XXX
 SG_ ErrorRegisterManufSpecific : 23|1@1+ (1,0) [0|0] "" Vector__XXX
 SG_ ErrorRegisterReserved : 22|1@1+ (1,0) [0|0] "" Vector__XXX
 SG_ ErrorRegisterProfileSpecific : 21|1@1+ (1,0) [0|0] "" Vector__XXX
 SG_ ErrorRegisterCommunication : 20|1@1+ (1,0) [0|0] "" Vector__XXX
 SG_ ErrorRegisterTemperature : 19|1@1+ (1,0) [0|0] "" Vector__XXX
 SG_ ErrorRegisterVoltage : 18|1@1+ (1,0) [0|0] "" Vector__XXX
 SG_ ErrorRegisterCurrent : 17|1@1+ (1,0) [0|0] "" Vector__XXX
 SG_ ErrorRegisterGeneric : 16|1@1+ (1,0) [0|0] "" Vector__XXX
 SG_ ErrorCode : 0|16@1+ (1,0) [0|0] "" Vector__XXX

BO_ 1853 HBGuard_061: 1 Vector__XXX
 SG_ Toggle : 7|1@1+ (1,0) [0|0] "" Vector__XXX
 SG_ State : 0|7@1+ (1,0) [0|0] "" Vector__XXX

BO_ 1469 SSDO_061: 8 Vector__XXX

BO_ 1597 CSDO_061: 8 Vector__XXX

BO_ 189 EMCY_061: 8 Vector__XXX
 SG_ ManufacturerSpecific5 : 56|8@1+ (1,0) [0|0] "" Vector__XXX
 SG_ ManufacturerSpecific4 : 48|8@1+ (1,0) [0|0] "" Vector__XXX
 SG_ ManufacturerSpecific3 : 40|8@1+ (1,0) [0|0] "" Vector__XXX
 SG_ ManufacturerSpecific2 : 32|8@1+ (1,0) [0|0] "" Vector__XXX
 SG_ ManufacturerSpecific1 : 24|8@1+ (1,0) [0|0] "" Vector__XXX
 SG_ ErrorRegisterManufSpecific : 23|1@1+ (1,0) [0|0] "" Vector__XXX
 SG_ ErrorRegisterReserved : 22|1@1+ (1,0) [0|0] "" Vector__XXX
 SG_ ErrorRegisterProfileSpecific : 21|1@1+ (1,0) [0|0] "" Vector__XXX
 SG_ ErrorRegisterCommunication : 20|1@1+ (1,0) [0|0] "" Vector__XXX
 SG_ ErrorRegisterTemperature : 19|1@1+ (1,0) [0|0] "" Vector__XXX
 SG_ ErrorRegisterVoltage : 18|1@1+ (1,0) [0|0] "" Vector__XXX
 SG_ ErrorRegisterCurrent : 17|1@1+ (1,0) [0|0] "" Vector__XXX
 SG_ ErrorRegisterGeneric : 16|1@1+ (1,0) [0|0] "" Vector__XXX
 SG_ ErrorCode : 0|16@1+ (1,0) [0|0] "" Vector__XXX

BO_ 1852 HBGuard_060: 1 Vector__XXX
 SG_ Toggle : 7|1@1+ (1,0) [0|0] "" Vector__XXX
 SG_ State : 0|7@1+ (1,0) [0|0] "" Vector__XXX

BO_ 1468 SSDO_060: 8 Vector__XXX

BO_ 1596 CSDO_060: 8 Vector__XXX

BO_ 188 EMCY_060: 8 Vector__XXX
 SG_ ManufacturerSpecific5 : 56|8@1+ (1,0) [0|0] "" Vector__XXX
 SG_ ManufacturerSpecific4 : 48|8@1+ (1,0) [0|0] "" Vector__XXX
 SG_ ManufacturerSpecific3 : 40|8@1+ (1,0) [0|0] "" Vector__XXX
 SG_ ManufacturerSpecific2 : 32|8@1+ (1,0) [0|0] "" Vector__XXX
 SG_ ManufacturerSpecific1 : 24|8@1+ (1,0) [0|0] "" Vector__XXX
 SG_ ErrorRegisterManufSpecific : 23|1@1+ (1,0) [0|0] "" Vector__XXX
 SG_ ErrorRegisterReserved : 22|1@1+ (1,0) [0|0] "" Vector__XXX
 SG_ ErrorRegisterProfileSpecific : 21|1@1+ (1,0) [0|0] "" Vector__XXX
 SG_ ErrorRegisterCommunication : 20|1@1+ (1,0) [0|0] "" Vector__XXX
 SG_ ErrorRegisterTemperature : 19|1@1+ (1,0) [0|0] "" Vector__XXX
 SG_ ErrorRegisterVoltage : 18|1@1+ (1,0) [0|0] "" Vector__XXX
 SG_ ErrorRegisterCurrent : 17|1@1+ (1,0) [0|0] "" Vector__XXX
 SG_ ErrorRegisterGeneric : 16|1@1+ (1,0) [0|0] "" Vector__XXX
 SG_ ErrorCode : 0|16@1+ (1,0) [0|0] "" Vector__XXX

BO_ 1851 HBGuard_059: 1 Vector__XXX
 SG_ Toggle : 7|1@1+ (1,0) [0|0] "" Vector__XXX
 SG_ State : 0|7@1+ (1,0) [0|0] "" Vector__XXX

BO_ 1467 SSDO_059: 8 Vector__XXX

BO_ 1595 CSDO_059: 8 Vector__XXX

BO_ 187 EMCY_059: 8 Vector__XXX
 SG_ ManufacturerSpecific5 : 56|8@1+ (1,0) [0|0] "" Vector__XXX
 SG_ ManufacturerSpecific4 : 48|8@1+ (1,0) [0|0] "" Vector__XXX
 SG_ ManufacturerSpecific3 : 40|8@1+ (1,0) [0|0] "" Vector__XXX
 SG_ ManufacturerSpecific2 : 32|8@1+ (1,0) [0|0] "" Vector__XXX
 SG_ ManufacturerSpecific1 : 24|8@1+ (1,0) [0|0] "" Vector__XXX
 SG_ ErrorRegisterManufSpecific : 23|1@1+ (1,0) [0|0] "" Vector__XXX
 SG_ ErrorRegisterReserved : 22|1@1+ (1,0) [0|0] "" Vector__XXX
 SG_ ErrorRegisterProfileSpecific : 21|1@1+ (1,0) [0|0] "" Vector__XXX
 SG_ ErrorRegisterCommunication : 20|1@1+ (1,0) [0|0] "" Vector__XXX
 SG_ ErrorRegisterTemperature : 19|1@1+ (1,0) [0|0] "" Vector__XXX
 SG_ ErrorRegisterVoltage : 18|1@1+ (1,0) [0|0] "" Vector__XXX
 SG_ ErrorRegisterCurrent : 17|1@1+ (1,0) [0|0] "" Vector__XXX
 SG_ ErrorRegisterGeneric : 16|1@1+ (1,0) [0|0] "" Vector__XXX
 SG_ ErrorCode : 0|16@1+ (1,0) [0|0] "" Vector__XXX

BO_ 1850 HBGuard_058: 1 Vector__XXX
 SG_ Toggle : 7|1@1+ (1,0) [0|0] "" Vector__XXX
 SG_ State : 0|7@1+ (1,0) [0|0] "" Vector__XXX

BO_ 1466 SSDO_058: 8 Vector__XXX

BO_ 1594 CSDO_058: 8 Vector__XXX

BO_ 186 EMCY_058: 8 Vector__XXX
 SG_ ManufacturerSpecific5 : 56|8@1+ (1,0) [0|0] "" Vector__XXX
 SG_ ManufacturerSpecific4 : 48|8@1+ (1,0) [0|0] "" Vector__XXX
 SG_ ManufacturerSpecific3 : 40|8@1+ (1,0) [0|0] "" Vector__XXX
 SG_ ManufacturerSpecific2 : 32|8@1+ (1,0) [0|0] "" Vector__XXX
 SG_ ManufacturerSpecific1 : 24|8@1+ (1,0) [0|0] "" Vector__XXX
 SG_ ErrorRegisterManufSpecific : 23|1@1+ (1,0) [0|0] "" Vector__XXX
 SG_ ErrorRegisterReserved : 22|1@1+ (1,0) [0|0] "" Vector__XXX
 SG_ ErrorRegisterProfileSpecific : 21|1@1+ (1,0) [0|0] "" Vector__XXX
 SG_ ErrorRegisterCommunication : 20|1@1+ (1,0) [0|0] "" Vector__XXX
 SG_ ErrorRegisterTemperature : 19|1@1+ (1,0) [0|0] "" Vector__XXX
 SG_ ErrorRegisterVoltage : 18|1@1+ (1,0) [0|0] "" Vector__XXX
 SG_ ErrorRegisterCurrent : 17|1@1+ (1,0) [0|0] "" Vector__XXX
 SG_ ErrorRegisterGeneric : 16|1@1+ (1,0) [0|0] "" Vector__XXX
 SG_ ErrorCode : 0|16@1+ (1,0) [0|0] "" Vector__XXX

BO_ 1849 HBGuard_057: 1 Vector__XXX
 SG_ Toggle : 7|1@1+ (1,0) [0|0] "" Vector__XXX
 SG_ State : 0|7@1+ (1,0) [0|0] "" Vector__XXX

BO_ 1465 SSDO_057: 8 Vector__XXX

BO_ 1593 CSDO_057: 8 Vector__XXX

BO_ 185 EMCY_057: 8 Vector__XXX
 SG_ ManufacturerSpecific5 : 56|8@1+ (1,0) [0|0] "" Vector__XXX
 SG_ ManufacturerSpecific4 : 48|8@1+ (1,0) [0|0] "" Vector__XXX
 SG_ ManufacturerSpecific3 : 40|8@1+ (1,0) [0|0] "" Vector__XXX
 SG_ ManufacturerSpecific2 : 32|8@1+ (1,0) [0|0] "" Vector__XXX
 SG_ ManufacturerSpecific1 : 24|8@1+ (1,0) [0|0] "" Vector__XXX
 SG_ ErrorRegisterManufSpecific : 23|1@1+ (1,0) [0|0] "" Vector__XXX
 SG_ ErrorRegisterReserved : 22|1@1+ (1,0) [0|0] "" Vector__XXX
 SG_ ErrorRegisterProfileSpecific : 21|1@1+ (1,0) [0|0] "" Vector__XXX
 SG_ ErrorRegisterCommunication : 20|1@1+ (1,0) [0|0] "" Vector__XXX
 SG_ ErrorRegisterTemperature : 19|1@1+ (1,0) [0|0] "" Vector__XXX
 SG_ ErrorRegisterVoltage : 18|1@1+ (1,0) [0|0] "" Vector__XXX
 SG_ ErrorRegisterCurrent : 17|1@1+ (1,0) [0|0] "" Vector__XXX
 SG_ ErrorRegisterGeneric : 16|1@1+ (1,0) [0|0] "" Vector__XXX
 SG_ ErrorCode : 0|16@1+ (1,0) [0|0] "" Vector__XXX

BO_ 1848 HBGuard_056: 1 Vector__XXX
 SG_ Toggle : 7|1@1+ (1,0) [0|0] "" Vector__XXX
 SG_ State : 0|7@1+ (1,0) [0|0] "" Vector__XXX

BO_ 1464 SSDO_056: 8 Vector__XXX

BO_ 1592 CSDO_056: 8 Vector__XXX

BO_ 184 EMCY_056: 8 Vector__XXX
 SG_ ManufacturerSpecific5 : 56|8@1+ (1,0) [0|0] "" Vector__XXX
 SG_ ManufacturerSpecific4 : 48|8@1+ (1,0) [0|0] "" Vector__XXX
 SG_ ManufacturerSpecific3 : 40|8@1+ (1,0) [0|0] "" Vector__XXX
 SG_ ManufacturerSpecific2 : 32|8@1+ (1,0) [0|0] "" Vector__XXX
 SG_ ManufacturerSpecific1 : 24|8@1+ (1,0) [0|0] "" Vector__XXX
 SG_ ErrorRegisterManufSpecific : 23|1@1+ (1,0) [0|0] "" Vector__XXX
 SG_ ErrorRegisterReserved : 22|1@1+ (1,0) [0|0] "" Vector__XXX
 SG_ ErrorRegisterProfileSpecific : 21|1@1+ (1,0) [0|0] "" Vector__XXX
 SG_ ErrorRegisterCommunication : 20|1@1+ (1,0) [0|0] "" Vector__XXX
 SG_ ErrorRegisterTemperature : 19|1@1+ (1,0) [0|0] "" Vector__XXX
 SG_ ErrorRegisterVoltage : 18|1@1+ (1,0) [0|0] "" Vector__XXX
 SG_ ErrorRegisterCurrent : 17|1@1+ (1,0) [0|0] "" Vector__XXX
 SG_ ErrorRegisterGeneric : 16|1@1+ (1,0) [0|0] "" Vector__XXX
 SG_ ErrorCode : 0|16@1+ (1,0) [0|0] "" Vector__XXX

BO_ 1847 HBGuard_055: 1 Vector__XXX
 SG_ Toggle : 7|1@1+ (1,0) [0|0] "" Vector__XXX
 SG_ State : 0|7@1+ (1,0) [0|0] "" Vector__XXX

BO_ 1463 SSDO_055: 8 Vector__XXX

BO_ 1591 CSDO_055: 8 Vector__XXX

BO_ 183 EMCY_055: 8 Vector__XXX
 SG_ ManufacturerSpecific5 : 56|8@1+ (1,0) [0|0] "" Vector__XXX
 SG_ ManufacturerSpecific4 : 48|8@1+ (1,0) [0|0] "" Vector__XXX
 SG_ ManufacturerSpecific3 : 40|8@1+ (1,0) [0|0] "" Vector__XXX
 SG_ ManufacturerSpecific2 : 32|8@1+ (1,0) [0|0] "" Vector__XXX
 SG_ ManufacturerSpecific1 : 24|8@1+ (1,0) [0|0] "" Vector__XXX
 SG_ ErrorRegisterManufSpecific : 23|1@1+ (1,0) [0|0] "" Vector__XXX
 SG_ ErrorRegisterReserved : 22|1@1+ (1,0) [0|0] "" Vector__XXX
 SG_ ErrorRegisterProfileSpecific : 21|1@1+ (1,0) [0|0] "" Vector__XXX
 SG_ ErrorRegisterCommunication : 20|1@1+ (1,0) [0|0] "" Vector__XXX
 SG_ ErrorRegisterTemperature : 19|1@1+ (1,0) [0|0] "" Vector__XXX
 SG_ ErrorRegisterVoltage : 18|1@1+ (1,0) [0|0] "" Vector__XXX
 SG_ ErrorRegisterCurrent : 17|1@1+ (1,0) [0|0] "" Vector__XXX
 SG_ ErrorRegisterGeneric : 16|1@1+ (1,0) [0|0] "" Vector__XXX
 SG_ ErrorCode : 0|16@1+ (1,0) [0|0] "" Vector__XXX

BO_ 1846 HBGuard_054: 1 Vector__XXX
 SG_ Toggle : 7|1@1+ (1,0) [0|0] "" Vector__XXX
 SG_ State : 0|7@1+ (1,0) [0|0] "" Vector__XXX

BO_ 1462 SSDO_054: 8 Vector__XXX

BO_ 1590 CSDO_054: 8 Vector__XXX

BO_ 182 EMCY_054: 8 Vector__XXX
 SG_ ManufacturerSpecific5 : 56|8@1+ (1,0) [0|0] "" Vector__XXX
 SG_ ManufacturerSpecific4 : 48|8@1+ (1,0) [0|0] "" Vector__XXX
 SG_ ManufacturerSpecific3 : 40|8@1+ (1,0) [0|0] "" Vector__XXX
 SG_ ManufacturerSpecific2 : 32|8@1+ (1,0) [0|0] "" Vector__XXX
 SG_ ManufacturerSpecific1 : 24|8@1+ (1,0) [0|0] "" Vector__XXX
 SG_ ErrorRegisterManufSpecific : 23|1@1+ (1,0) [0|0] "" Vector__XXX
 SG_ ErrorRegisterReserved : 22|1@1+ (1,0) [0|0] "" Vector__XXX
 SG_ ErrorRegisterProfileSpecific : 21|1@1+ (1,0) [0|0] "" Vector__XXX
 SG_ ErrorRegisterCommunication : 20|1@1+ (1,0) [0|0] "" Vector__XXX
 SG_ ErrorRegisterTemperature : 19|1@1+ (1,0) [0|0] "" Vector__XXX
 SG_ ErrorRegisterVoltage : 18|1@1+ (1,0) [0|0] "" Vector__XXX
 SG_ ErrorRegisterCurrent : 17|1@1+ (1,0) [0|0] "" Vector__XXX
 SG_ ErrorRegisterGeneric : 16|1@1+ (1,0) [0|0] "" Vector__XXX
 SG_ ErrorCode : 0|16@1+ (1,0) [0|0] "" Vector__XXX

BO_ 1845 HBGuard_053: 1 Vector__XXX
 SG_ Toggle : 7|1@1+ (1,0) [0|0] "" Vector__XXX
 SG_ State : 0|7@1+ (1,0) [0|0] "" Vector__XXX

BO_ 1461 SSDO_053: 8 Vector__XXX

BO_ 1589 CSDO_053: 8 Vector__XXX

BO_ 181 EMCY_053: 8 Vector__XXX
 SG_ ManufacturerSpecific5 : 56|8@1+ (1,0) [0|0] "" Vector__XXX
 SG_ ManufacturerSpecific4 : 48|8@1+ (1,0) [0|0] "" Vector__XXX
 SG_ ManufacturerSpecific3 : 40|8@1+ (1,0) [0|0] "" Vector__XXX
 SG_ ManufacturerSpecific2 : 32|8@1+ (1,0) [0|0] "" Vector__XXX
 SG_ ManufacturerSpecific1 : 24|8@1+ (1,0) [0|0] "" Vector__XXX
 SG_ ErrorRegisterManufSpecific : 23|1@1+ (1,0) [0|0] "" Vector__XXX
 SG_ ErrorRegisterReserved : 22|1@1+ (1,0) [0|0] "" Vector__XXX
 SG_ ErrorRegisterProfileSpecific : 21|1@1+ (1,0) [0|0] "" Vector__XXX
 SG_ ErrorRegisterCommunication : 20|1@1+ (1,0) [0|0] "" Vector__XXX
 SG_ ErrorRegisterTemperature : 19|1@1+ (1,0) [0|0] "" Vector__XXX
 SG_ ErrorRegisterVoltage : 18|1@1+ (1,0) [0|0] "" Vector__XXX
 SG_ ErrorRegisterCurrent : 17|1@1+ (1,0) [0|0] "" Vector__XXX
 SG_ ErrorRegisterGeneric : 16|1@1+ (1,0) [0|0] "" Vector__XXX
 SG_ ErrorCode : 0|16@1+ (1,0) [0|0] "" Vector__XXX

BO_ 1844 HBGuard_052: 1 Vector__XXX
 SG_ Toggle : 7|1@1+ (1,0) [0|0] "" Vector__XXX
 SG_ State : 0|7@1+ (1,0) [0|0] "" Vector__XXX

BO_ 1460 SSDO_052: 8 Vector__XXX

BO_ 1588 CSDO_052: 8 Vector__XXX

BO_ 180 EMCY_052: 8 Vector__XXX
 SG_ ManufacturerSpecific5 : 56|8@1+ (1,0) [0|0] "" Vector__XXX
 SG_ ManufacturerSpecific4 : 48|8@1+ (1,0) [0|0] "" Vector__XXX
 SG_ ManufacturerSpecific3 : 40|8@1+ (1,0) [0|0] "" Vector__XXX
 SG_ ManufacturerSpecific2 : 32|8@1+ (1,0) [0|0] "" Vector__XXX
 SG_ ManufacturerSpecific1 : 24|8@1+ (1,0) [0|0] "" Vector__XXX
 SG_ ErrorRegisterManufSpecific : 23|1@1+ (1,0) [0|0] "" Vector__XXX
 SG_ ErrorRegisterReserved : 22|1@1+ (1,0) [0|0] "" Vector__XXX
 SG_ ErrorRegisterProfileSpecific : 21|1@1+ (1,0) [0|0] "" Vector__XXX
 SG_ ErrorRegisterCommunication : 20|1@1+ (1,0) [0|0] "" Vector__XXX
 SG_ ErrorRegisterTemperature : 19|1@1+ (1,0) [0|0] "" Vector__XXX
 SG_ ErrorRegisterVoltage : 18|1@1+ (1,0) [0|0] "" Vector__XXX
 SG_ ErrorRegisterCurrent : 17|1@1+ (1,0) [0|0] "" Vector__XXX
 SG_ ErrorRegisterGeneric : 16|1@1+ (1,0) [0|0] "" Vector__XXX
 SG_ ErrorCode : 0|16@1+ (1,0) [0|0] "" Vector__XXX

BO_ 1843 HBGuard_051: 1 Vector__XXX
 SG_ Toggle : 7|1@1+ (1,0) [0|0] "" Vector__XXX
 SG_ State : 0|7@1+ (1,0) [0|0] "" Vector__XXX

BO_ 1459 SSDO_051: 8 Vector__XXX

BO_ 1587 CSDO_051: 8 Vector__XXX

BO_ 179 EMCY_051: 8 Vector__XXX
 SG_ ManufacturerSpecific5 : 56|8@1+ (1,0) [0|0] "" Vector__XXX
 SG_ ManufacturerSpecific4 : 48|8@1+ (1,0) [0|0] "" Vector__XXX
 SG_ ManufacturerSpecific3 : 40|8@1+ (1,0) [0|0] "" Vector__XXX
 SG_ ManufacturerSpecific2 : 32|8@1+ (1,0) [0|0] "" Vector__XXX
 SG_ ManufacturerSpecific1 : 24|8@1+ (1,0) [0|0] "" Vector__XXX
 SG_ ErrorRegisterManufSpecific : 23|1@1+ (1,0) [0|0] "" Vector__XXX
 SG_ ErrorRegisterReserved : 22|1@1+ (1,0) [0|0] "" Vector__XXX
 SG_ ErrorRegisterProfileSpecific : 21|1@1+ (1,0) [0|0] "" Vector__XXX
 SG_ ErrorRegisterCommunication : 20|1@1+ (1,0) [0|0] "" Vector__XXX
 SG_ ErrorRegisterTemperature : 19|1@1+ (1,0) [0|0] "" Vector__XXX
 SG_ ErrorRegisterVoltage : 18|1@1+ (1,0) [0|0] "" Vector__XXX
 SG_ ErrorRegisterCurrent : 17|1@1+ (1,0) [0|0] "" Vector__XXX
 SG_ ErrorRegisterGeneric : 16|1@1+ (1,0) [0|0] "" Vector__XXX
 SG_ ErrorCode : 0|16@1+ (1,0) [0|0] "" Vector__XXX

BO_ 1842 HBGuard_050: 1 Vector__XXX
 SG_ Toggle : 7|1@1+ (1,0) [0|0] "" Vector__XXX
 SG_ State : 0|7@1+ (1,0) [0|0] "" Vector__XXX

BO_ 1458 SSDO_050: 8 Vector__XXX

BO_ 1586 CSDO_050: 8 Vector__XXX

BO_ 178 EMCY_050: 8 Vector__XXX
 SG_ ManufacturerSpecific5 : 56|8@1+ (1,0) [0|0] "" Vector__XXX
 SG_ ManufacturerSpecific4 : 48|8@1+ (1,0) [0|0] "" Vector__XXX
 SG_ ManufacturerSpecific3 : 40|8@1+ (1,0) [0|0] "" Vector__XXX
 SG_ ManufacturerSpecific2 : 32|8@1+ (1,0) [0|0] "" Vector__XXX
 SG_ ManufacturerSpecific1 : 24|8@1+ (1,0) [0|0] "" Vector__XXX
 SG_ ErrorRegisterManufSpecific : 23|1@1+ (1,0) [0|0] "" Vector__XXX
 SG_ ErrorRegisterReserved : 22|1@1+ (1,0) [0|0] "" Vector__XXX
 SG_ ErrorRegisterProfileSpecific : 21|1@1+ (1,0) [0|0] "" Vector__XXX
 SG_ ErrorRegisterCommunication : 20|1@1+ (1,0) [0|0] "" Vector__XXX
 SG_ ErrorRegisterTemperature : 19|1@1+ (1,0) [0|0] "" Vector__XXX
 SG_ ErrorRegisterVoltage : 18|1@1+ (1,0) [0|0] "" Vector__XXX
 SG_ ErrorRegisterCurrent : 17|1@1+ (1,0) [0|0] "" Vector__XXX
 SG_ ErrorRegisterGeneric : 16|1@1+ (1,0) [0|0] "" Vector__XXX
 SG_ ErrorCode : 0|16@1+ (1,0) [0|0] "" Vector__XXX

BO_ 1841 HBGuard_049: 1 Vector__XXX
 SG_ Toggle : 7|1@1+ (1,0) [0|0] "" Vector__XXX
 SG_ State : 0|7@1+ (1,0) [0|0] "" Vector__XXX

BO_ 1457 SSDO_049: 8 Vector__XXX

BO_ 1585 CSDO_049: 8 Vector__XXX

BO_ 177 EMCY_049: 8 Vector__XXX
 SG_ ManufacturerSpecific5 : 56|8@1+ (1,0) [0|0] "" Vector__XXX
 SG_ ManufacturerSpecific4 : 48|8@1+ (1,0) [0|0] "" Vector__XXX
 SG_ ManufacturerSpecific3 : 40|8@1+ (1,0) [0|0] "" Vector__XXX
 SG_ ManufacturerSpecific2 : 32|8@1+ (1,0) [0|0] "" Vector__XXX
 SG_ ManufacturerSpecific1 : 24|8@1+ (1,0) [0|0] "" Vector__XXX
 SG_ ErrorRegisterManufSpecific : 23|1@1+ (1,0) [0|0] "" Vector__XXX
 SG_ ErrorRegisterReserved : 22|1@1+ (1,0) [0|0] "" Vector__XXX
 SG_ ErrorRegisterProfileSpecific : 21|1@1+ (1,0) [0|0] "" Vector__XXX
 SG_ ErrorRegisterCommunication : 20|1@1+ (1,0) [0|0] "" Vector__XXX
 SG_ ErrorRegisterTemperature : 19|1@1+ (1,0) [0|0] "" Vector__XXX
 SG_ ErrorRegisterVoltage : 18|1@1+ (1,0) [0|0] "" Vector__XXX
 SG_ ErrorRegisterCurrent : 17|1@1+ (1,0) [0|0] "" Vector__XXX
 SG_ ErrorRegisterGeneric : 16|1@1+ (1,0) [0|0] "" Vector__XXX
 SG_ ErrorCode : 0|16@1+ (1,0) [0|0] "" Vector__XXX

BO_ 1840 HBGuard_048: 1 Vector__XXX
 SG_ Toggle : 7|1@1+ (1,0) [0|0] "" Vector__XXX
 SG_ State : 0|7@1+ (1,0) [0|0] "" Vector__XXX

BO_ 1456 SSDO_048: 8 Vector__XXX

BO_ 1584 CSDO_048: 8 Vector__XXX

BO_ 176 EMCY_048: 8 Vector__XXX
 SG_ ManufacturerSpecific5 : 56|8@1+ (1,0) [0|0] "" Vector__XXX
 SG_ ManufacturerSpecific4 : 48|8@1+ (1,0) [0|0] "" Vector__XXX
 SG_ ManufacturerSpecific3 : 40|8@1+ (1,0) [0|0] "" Vector__XXX
 SG_ ManufacturerSpecific2 : 32|8@1+ (1,0) [0|0] "" Vector__XXX
 SG_ ManufacturerSpecific1 : 24|8@1+ (1,0) [0|0] "" Vector__XXX
 SG_ ErrorRegisterManufSpecific : 23|1@1+ (1,0) [0|0] "" Vector__XXX
 SG_ ErrorRegisterReserved : 22|1@1+ (1,0) [0|0] "" Vector__XXX
 SG_ ErrorRegisterProfileSpecific : 21|1@1+ (1,0) [0|0] "" Vector__XXX
 SG_ ErrorRegisterCommunication : 20|1@1+ (1,0) [0|0] "" Vector__XXX
 SG_ ErrorRegisterTemperature : 19|1@1+ (1,0) [0|0] "" Vector__XXX
 SG_ ErrorRegisterVoltage : 18|1@1+ (1,0) [0|0] "" Vector__XXX
 SG_ ErrorRegisterCurrent : 17|1@1+ (1,0) [0|0] "" Vector__XXX
 SG_ ErrorRegisterGeneric : 16|1@1+ (1,0) [0|0] "" Vector__XXX
 SG_ ErrorCode : 0|16@1+ (1,0) [0|0] "" Vector__XXX

BO_ 1839 HBGuard_047: 1 Vector__XXX
 SG_ Toggle : 7|1@1+ (1,0) [0|0] "" Vector__XXX
 SG_ State : 0|7@1+ (1,0) [0|0] "" Vector__XXX

BO_ 1455 SSDO_047: 8 Vector__XXX

BO_ 1583 CSDO_047: 8 Vector__XXX

BO_ 175 EMCY_047: 8 Vector__XXX
 SG_ ManufacturerSpecific5 : 56|8@1+ (1,0) [0|0] "" Vector__XXX
 SG_ ManufacturerSpecific4 : 48|8@1+ (1,0) [0|0] "" Vector__XXX
 SG_ ManufacturerSpecific3 : 40|8@1+ (1,0) [0|0] "" Vector__XXX
 SG_ ManufacturerSpecific2 : 32|8@1+ (1,0) [0|0] "" Vector__XXX
 SG_ ManufacturerSpecific1 : 24|8@1+ (1,0) [0|0] "" Vector__XXX
 SG_ ErrorRegisterManufSpecific : 23|1@1+ (1,0) [0|0] "" Vector__XXX
 SG_ ErrorRegisterReserved : 22|1@1+ (1,0) [0|0] "" Vector__XXX
 SG_ ErrorRegisterProfileSpecific : 21|1@1+ (1,0) [0|0] "" Vector__XXX
 SG_ ErrorRegisterCommunication : 20|1@1+ (1,0) [0|0] "" Vector__XXX
 SG_ ErrorRegisterTemperature : 19|1@1+ (1,0) [0|0] "" Vector__XXX
 SG_ ErrorRegisterVoltage : 18|1@1+ (1,0) [0|0] "" Vector__XXX
 SG_ ErrorRegisterCurrent : 17|1@1+ (1,0) [0|0] "" Vector__XXX
 SG_ ErrorRegisterGeneric : 16|1@1+ (1,0) [0|0] "" Vector__XXX
 SG_ ErrorCode : 0|16@1+ (1,0) [0|0] "" Vector__XXX

BO_ 1838 HBGuard_046: 1 Vector__XXX
 SG_ Toggle : 7|1@1+ (1,0) [0|0] "" Vector__XXX
 SG_ State : 0|7@1+ (1,0) [0|0] "" Vector__XXX

BO_ 1454 SSDO_046: 8 Vector__XXX

BO_ 1582 CSDO_046: 8 Vector__XXX

BO_ 174 EMCY_046: 8 Vector__XXX
 SG_ ManufacturerSpecific5 : 56|8@1+ (1,0) [0|0] "" Vector__XXX
 SG_ ManufacturerSpecific4 : 48|8@1+ (1,0) [0|0] "" Vector__XXX
 SG_ ManufacturerSpecific3 : 40|8@1+ (1,0) [0|0] "" Vector__XXX
 SG_ ManufacturerSpecific2 : 32|8@1+ (1,0) [0|0] "" Vector__XXX
 SG_ ManufacturerSpecific1 : 24|8@1+ (1,0) [0|0] "" Vector__XXX
 SG_ ErrorRegisterManufSpecific : 23|1@1+ (1,0) [0|0] "" Vector__XXX
 SG_ ErrorRegisterReserved : 22|1@1+ (1,0) [0|0] "" Vector__XXX
 SG_ ErrorRegisterProfileSpecific : 21|1@1+ (1,0) [0|0] "" Vector__XXX
 SG_ ErrorRegisterCommunication : 20|1@1+ (1,0) [0|0] "" Vector__XXX
 SG_ ErrorRegisterTemperature : 19|1@1+ (1,0) [0|0] "" Vector__XXX
 SG_ ErrorRegisterVoltage : 18|1@1+ (1,0) [0|0] "" Vector__XXX
 SG_ ErrorRegisterCurrent : 17|1@1+ (1,0) [0|0] "" Vector__XXX
 SG_ ErrorRegisterGeneric : 16|1@1+ (1,0) [0|0] "" Vector__XXX
 SG_ ErrorCode : 0|16@1+ (1,0) [0|0] "" Vector__XXX

BO_ 1837 HBGuard_045: 1 Vector__XXX
 SG_ Toggle : 7|1@1+ (1,0) [0|0] "" Vector__XXX
 SG_ State : 0|7@1+ (1,0) [0|0] "" Vector__XXX

BO_ 1453 SSDO_045: 8 Vector__XXX

BO_ 1581 CSDO_045: 8 Vector__XXX

BO_ 173 EMCY_045: 8 Vector__XXX
 SG_ ManufacturerSpecific5 : 56|8@1+ (1,0) [0|0] "" Vector__XXX
 SG_ ManufacturerSpecific4 : 48|8@1+ (1,0) [0|0] "" Vector__XXX
 SG_ ManufacturerSpecific3 : 40|8@1+ (1,0) [0|0] "" Vector__XXX
 SG_ ManufacturerSpecific2 : 32|8@1+ (1,0) [0|0] "" Vector__XXX
 SG_ ManufacturerSpecific1 : 24|8@1+ (1,0) [0|0] "" Vector__XXX
 SG_ ErrorRegisterManufSpecific : 23|1@1+ (1,0) [0|0] "" Vector__XXX
 SG_ ErrorRegisterReserved : 22|1@1+ (1,0) [0|0] "" Vector__XXX
 SG_ ErrorRegisterProfileSpecific : 21|1@1+ (1,0) [0|0] "" Vector__XXX
 SG_ ErrorRegisterCommunication : 20|1@1+ (1,0) [0|0] "" Vector__XXX
 SG_ ErrorRegisterTemperature : 19|1@1+ (1,0) [0|0] "" Vector__XXX
 SG_ ErrorRegisterVoltage : 18|1@1+ (1,0) [0|0] "" Vector__XXX
 SG_ ErrorRegisterCurrent : 17|1@1+ (1,0) [0|0] "" Vector__XXX
 SG_ ErrorRegisterGeneric : 16|1@1+ (1,0) [0|0] "" Vector__XXX
 SG_ ErrorCode : 0|16@1+ (1,0) [0|0] "" Vector__XXX

BO_ 1836 HBGuard_044: 1 Vector__XXX
 SG_ Toggle : 7|1@1+ (1,0) [0|0] "" Vector__XXX
 SG_ State : 0|7@1+ (1,0) [0|0] "" Vector__XXX

BO_ 1452 SSDO_044: 8 Vector__XXX

BO_ 1580 CSDO_044: 8 Vector__XXX

BO_ 172 EMCY_044: 8 Vector__XXX
 SG_ ManufacturerSpecific5 : 56|8@1+ (1,0) [0|0] "" Vector__XXX
 SG_ ManufacturerSpecific4 : 48|8@1+ (1,0) [0|0] "" Vector__XXX
 SG_ ManufacturerSpecific3 : 40|8@1+ (1,0) [0|0] "" Vector__XXX
 SG_ ManufacturerSpecific2 : 32|8@1+ (1,0) [0|0] "" Vector__XXX
 SG_ ManufacturerSpecific1 : 24|8@1+ (1,0) [0|0] "" Vector__XXX
 SG_ ErrorRegisterManufSpecific : 23|1@1+ (1,0) [0|0] "" Vector__XXX
 SG_ ErrorRegisterReserved : 22|1@1+ (1,0) [0|0] "" Vector__XXX
 SG_ ErrorRegisterProfileSpecific : 21|1@1+ (1,0) [0|0] "" Vector__XXX
 SG_ ErrorRegisterCommunication : 20|1@1+ (1,0) [0|0] "" Vector__XXX
 SG_ ErrorRegisterTemperature : 19|1@1+ (1,0) [0|0] "" Vector__XXX
 SG_ ErrorRegisterVoltage : 18|1@1+ (1,0) [0|0] "" Vector__XXX
 SG_ ErrorRegisterCurrent : 17|1@1+ (1,0) [0|0] "" Vector__XXX
 SG_ ErrorRegisterGeneric : 16|1@1+ (1,0) [0|0] "" Vector__XXX
 SG_ ErrorCode : 0|16@1+ (1,0) [0|0] "" Vector__XXX

BO_ 1835 HBGuard_043: 1 Vector__XXX
 SG_ Toggle : 7|1@1+ (1,0) [0|0] "" Vector__XXX
 SG_ State : 0|7@1+ (1,0) [0|0] "" Vector__XXX

BO_ 1451 SSDO_043: 8 Vector__XXX

BO_ 1579 CSDO_043: 8 Vector__XXX

BO_ 171 EMCY_043: 8 Vector__XXX
 SG_ ManufacturerSpecific5 : 56|8@1+ (1,0) [0|0] "" Vector__XXX
 SG_ ManufacturerSpecific4 : 48|8@1+ (1,0) [0|0] "" Vector__XXX
 SG_ ManufacturerSpecific3 : 40|8@1+ (1,0) [0|0] "" Vector__XXX
 SG_ ManufacturerSpecific2 : 32|8@1+ (1,0) [0|0] "" Vector__XXX
 SG_ ManufacturerSpecific1 : 24|8@1+ (1,0) [0|0] "" Vector__XXX
 SG_ ErrorRegisterManufSpecific : 23|1@1+ (1,0) [0|0] "" Vector__XXX
 SG_ ErrorRegisterReserved : 22|1@1+ (1,0) [0|0] "" Vector__XXX
 SG_ ErrorRegisterProfileSpecific : 21|1@1+ (1,0) [0|0] "" Vector__XXX
 SG_ ErrorRegisterCommunication : 20|1@1+ (1,0) [0|0] "" Vector__XXX
 SG_ ErrorRegisterTemperature : 19|1@1+ (1,0) [0|0] "" Vector__XXX
 SG_ ErrorRegisterVoltage : 18|1@1+ (1,0) [0|0] "" Vector__XXX
 SG_ ErrorRegisterCurrent : 17|1@1+ (1,0) [0|0] "" Vector__XXX
 SG_ ErrorRegisterGeneric : 16|1@1+ (1,0) [0|0] "" Vector__XXX
 SG_ ErrorCode : 0|16@1+ (1,0) [0|0] "" Vector__XXX

BO_ 1834 HBGuard_042: 1 Vector__XXX
 SG_ Toggle : 7|1@1+ (1,0) [0|0] "" Vector__XXX
 SG_ State : 0|7@1+ (1,0) [0|0] "" Vector__XXX

BO_ 1450 SSDO_042: 8 Vector__XXX

BO_ 1578 CSDO_042: 8 Vector__XXX

BO_ 170 EMCY_042: 8 Vector__XXX
 SG_ ManufacturerSpecific5 : 56|8@1+ (1,0) [0|0] "" Vector__XXX
 SG_ ManufacturerSpecific4 : 48|8@1+ (1,0) [0|0] "" Vector__XXX
 SG_ ManufacturerSpecific3 : 40|8@1+ (1,0) [0|0] "" Vector__XXX
 SG_ ManufacturerSpecific2 : 32|8@1+ (1,0) [0|0] "" Vector__XXX
 SG_ ManufacturerSpecific1 : 24|8@1+ (1,0) [0|0] "" Vector__XXX
 SG_ ErrorRegisterManufSpecific : 23|1@1+ (1,0) [0|0] "" Vector__XXX
 SG_ ErrorRegisterReserved : 22|1@1+ (1,0) [0|0] "" Vector__XXX
 SG_ ErrorRegisterProfileSpecific : 21|1@1+ (1,0) [0|0] "" Vector__XXX
 SG_ ErrorRegisterCommunication : 20|1@1+ (1,0) [0|0] "" Vector__XXX
 SG_ ErrorRegisterTemperature : 19|1@1+ (1,0) [0|0] "" Vector__XXX
 SG_ ErrorRegisterVoltage : 18|1@1+ (1,0) [0|0] "" Vector__XXX
 SG_ ErrorRegisterCurrent : 17|1@1+ (1,0) [0|0] "" Vector__XXX
 SG_ ErrorRegisterGeneric : 16|1@1+ (1,0) [0|0] "" Vector__XXX
 SG_ ErrorCode : 0|16@1+ (1,0) [0|0] "" Vector__XXX

BO_ 1833 HBGuard_041: 1 Vector__XXX
 SG_ Toggle : 7|1@1+ (1,0) [0|0] "" Vector__XXX
 SG_ State : 0|7@1+ (1,0) [0|0] "" Vector__XXX

BO_ 1449 SSDO_041: 8 Vector__XXX

BO_ 1577 CSDO_041: 8 Vector__XXX

BO_ 169 EMCY_041: 8 Vector__XXX
 SG_ ManufacturerSpecific5 : 56|8@1+ (1,0) [0|0] "" Vector__XXX
 SG_ ManufacturerSpecific4 : 48|8@1+ (1,0) [0|0] "" Vector__XXX
 SG_ ManufacturerSpecific3 : 40|8@1+ (1,0) [0|0] "" Vector__XXX
 SG_ ManufacturerSpecific2 : 32|8@1+ (1,0) [0|0] "" Vector__XXX
 SG_ ManufacturerSpecific1 : 24|8@1+ (1,0) [0|0] "" Vector__XXX
 SG_ ErrorRegisterManufSpecific : 23|1@1+ (1,0) [0|0] "" Vector__XXX
 SG_ ErrorRegisterReserved : 22|1@1+ (1,0) [0|0] "" Vector__XXX
 SG_ ErrorRegisterProfileSpecific : 21|1@1+ (1,0) [0|0] "" Vector__XXX
 SG_ ErrorRegisterCommunication : 20|1@1+ (1,0) [0|0] "" Vector__XXX
 SG_ ErrorRegisterTemperature : 19|1@1+ (1,0) [0|0] "" Vector__XXX
 SG_ ErrorRegisterVoltage : 18|1@1+ (1,0) [0|0] "" Vector__XXX
 SG_ ErrorRegisterCurrent : 17|1@1+ (1,0) [0|0] "" Vector__XXX
 SG_ ErrorRegisterGeneric : 16|1@1+ (1,0) [0|0] "" Vector__XXX
 SG_ ErrorCode : 0|16@1+ (1,0) [0|0] "" Vector__XXX

BO_ 1832 HBGuard_040: 1 Vector__XXX
 SG_ Toggle : 7|1@1+ (1,0) [0|0] "" Vector__XXX
 SG_ State : 0|7@1+ (1,0) [0|0] "" Vector__XXX

BO_ 1448 SSDO_040: 8 Vector__XXX

BO_ 1576 CSDO_040: 8 Vector__XXX

BO_ 168 EMCY_040: 8 Vector__XXX
 SG_ ManufacturerSpecific5 : 56|8@1+ (1,0) [0|0] "" Vector__XXX
 SG_ ManufacturerSpecific4 : 48|8@1+ (1,0) [0|0] "" Vector__XXX
 SG_ ManufacturerSpecific3 : 40|8@1+ (1,0) [0|0] "" Vector__XXX
 SG_ ManufacturerSpecific2 : 32|8@1+ (1,0) [0|0] "" Vector__XXX
 SG_ ManufacturerSpecific1 : 24|8@1+ (1,0) [0|0] "" Vector__XXX
 SG_ ErrorRegisterManufSpecific : 23|1@1+ (1,0) [0|0] "" Vector__XXX
 SG_ ErrorRegisterReserved : 22|1@1+ (1,0) [0|0] "" Vector__XXX
 SG_ ErrorRegisterProfileSpecific : 21|1@1+ (1,0) [0|0] "" Vector__XXX
 SG_ ErrorRegisterCommunication : 20|1@1+ (1,0) [0|0] "" Vector__XXX
 SG_ ErrorRegisterTemperature : 19|1@1+ (1,0) [0|0] "" Vector__XXX
 SG_ ErrorRegisterVoltage : 18|1@1+ (1,0) [0|0] "" Vector__XXX
 SG_ ErrorRegisterCurrent : 17|1@1+ (1,0) [0|0] "" Vector__XXX
 SG_ ErrorRegisterGeneric : 16|1@1+ (1,0) [0|0] "" Vector__XXX
 SG_ ErrorCode : 0|16@1+ (1,0) [0|0] "" Vector__XXX

BO_ 1831 HBGuard_039: 1 Vector__XXX
 SG_ Toggle : 7|1@1+ (1,0) [0|0] "" Vector__XXX
 SG_ State : 0|7@1+ (1,0) [0|0] "" Vector__XXX

BO_ 1447 SSDO_039: 8 Vector__XXX

BO_ 1575 CSDO_039: 8 Vector__XXX

BO_ 167 EMCY_039: 8 Vector__XXX
 SG_ ManufacturerSpecific5 : 56|8@1+ (1,0) [0|0] "" Vector__XXX
 SG_ ManufacturerSpecific4 : 48|8@1+ (1,0) [0|0] "" Vector__XXX
 SG_ ManufacturerSpecific3 : 40|8@1+ (1,0) [0|0] "" Vector__XXX
 SG_ ManufacturerSpecific2 : 32|8@1+ (1,0) [0|0] "" Vector__XXX
 SG_ ManufacturerSpecific1 : 24|8@1+ (1,0) [0|0] "" Vector__XXX
 SG_ ErrorRegisterManufSpecific : 23|1@1+ (1,0) [0|0] "" Vector__XXX
 SG_ ErrorRegisterReserved : 22|1@1+ (1,0) [0|0] "" Vector__XXX
 SG_ ErrorRegisterProfileSpecific : 21|1@1+ (1,0) [0|0] "" Vector__XXX
 SG_ ErrorRegisterCommunication : 20|1@1+ (1,0) [0|0] "" Vector__XXX
 SG_ ErrorRegisterTemperature : 19|1@1+ (1,0) [0|0] "" Vector__XXX
 SG_ ErrorRegisterVoltage : 18|1@1+ (1,0) [0|0] "" Vector__XXX
 SG_ ErrorRegisterCurrent : 17|1@1+ (1,0) [0|0] "" Vector__XXX
 SG_ ErrorRegisterGeneric : 16|1@1+ (1,0) [0|0] "" Vector__XXX
 SG_ ErrorCode : 0|16@1+ (1,0) [0|0] "" Vector__XXX

BO_ 1830 HBGuard_038: 1 Vector__XXX
 SG_ Toggle : 7|1@1+ (1,0) [0|0] "" Vector__XXX
 SG_ State : 0|7@1+ (1,0) [0|0] "" Vector__XXX

BO_ 1446 SSDO_038: 8 Vector__XXX

BO_ 1574 CSDO_038: 8 Vector__XXX

BO_ 166 EMCY_038: 8 Vector__XXX
 SG_ ManufacturerSpecific5 : 56|8@1+ (1,0) [0|0] "" Vector__XXX
 SG_ ManufacturerSpecific4 : 48|8@1+ (1,0) [0|0] "" Vector__XXX
 SG_ ManufacturerSpecific3 : 40|8@1+ (1,0) [0|0] "" Vector__XXX
 SG_ ManufacturerSpecific2 : 32|8@1+ (1,0) [0|0] "" Vector__XXX
 SG_ ManufacturerSpecific1 : 24|8@1+ (1,0) [0|0] "" Vector__XXX
 SG_ ErrorRegisterManufSpecific : 23|1@1+ (1,0) [0|0] "" Vector__XXX
 SG_ ErrorRegisterReserved : 22|1@1+ (1,0) [0|0] "" Vector__XXX
 SG_ ErrorRegisterProfileSpecific : 21|1@1+ (1,0) [0|0] "" Vector__XXX
 SG_ ErrorRegisterCommunication : 20|1@1+ (1,0) [0|0] "" Vector__XXX
 SG_ ErrorRegisterTemperature : 19|1@1+ (1,0) [0|0] "" Vector__XXX
 SG_ ErrorRegisterVoltage : 18|1@1+ (1,0) [0|0] "" Vector__XXX
 SG_ ErrorRegisterCurrent : 17|1@1+ (1,0) [0|0] "" Vector__XXX
 SG_ ErrorRegisterGeneric : 16|1@1+ (1,0) [0|0] "" Vector__XXX
 SG_ ErrorCode : 0|16@1+ (1,0) [0|0] "" Vector__XXX

BO_ 1829 HBGuard_037: 1 Vector__XXX
 SG_ Toggle : 7|1@1+ (1,0) [0|0] "" Vector__XXX
 SG_ State : 0|7@1+ (1,0) [0|0] "" Vector__XXX

BO_ 1445 SSDO_037: 8 Vector__XXX

BO_ 1573 CSDO_037: 8 Vector__XXX

BO_ 165 EMCY_037: 8 Vector__XXX
 SG_ ManufacturerSpecific5 : 56|8@1+ (1,0) [0|0] "" Vector__XXX
 SG_ ManufacturerSpecific4 : 48|8@1+ (1,0) [0|0] "" Vector__XXX
 SG_ ManufacturerSpecific3 : 40|8@1+ (1,0) [0|0] "" Vector__XXX
 SG_ ManufacturerSpecific2 : 32|8@1+ (1,0) [0|0] "" Vector__XXX
 SG_ ManufacturerSpecific1 : 24|8@1+ (1,0) [0|0] "" Vector__XXX
 SG_ ErrorRegisterManufSpecific : 23|1@1+ (1,0) [0|0] "" Vector__XXX
 SG_ ErrorRegisterReserved : 22|1@1+ (1,0) [0|0] "" Vector__XXX
 SG_ ErrorRegisterProfileSpecific : 21|1@1+ (1,0) [0|0] "" Vector__XXX
 SG_ ErrorRegisterCommunication : 20|1@1+ (1,0) [0|0] "" Vector__XXX
 SG_ ErrorRegisterTemperature : 19|1@1+ (1,0) [0|0] "" Vector__XXX
 SG_ ErrorRegisterVoltage : 18|1@1+ (1,0) [0|0] "" Vector__XXX
 SG_ ErrorRegisterCurrent : 17|1@1+ (1,0) [0|0] "" Vector__XXX
 SG_ ErrorRegisterGeneric : 16|1@1+ (1,0) [0|0] "" Vector__XXX
 SG_ ErrorCode : 0|16@1+ (1,0) [0|0] "" Vector__XXX

BO_ 1828 HBGuard_036: 1 Vector__XXX
 SG_ Toggle : 7|1@1+ (1,0) [0|0] "" Vector__XXX
 SG_ State : 0|7@1+ (1,0) [0|0] "" Vector__XXX

BO_ 1444 SSDO_036: 8 Vector__XXX

BO_ 1572 CSDO_036: 8 Vector__XXX

BO_ 164 EMCY_036: 8 Vector__XXX
 SG_ ManufacturerSpecific5 : 56|8@1+ (1,0) [0|0] "" Vector__XXX
 SG_ ManufacturerSpecific4 : 48|8@1+ (1,0) [0|0] "" Vector__XXX
 SG_ ManufacturerSpecific3 : 40|8@1+ (1,0) [0|0] "" Vector__XXX
 SG_ ManufacturerSpecific2 : 32|8@1+ (1,0) [0|0] "" Vector__XXX
 SG_ ManufacturerSpecific1 : 24|8@1+ (1,0) [0|0] "" Vector__XXX
 SG_ ErrorRegisterManufSpecific : 23|1@1+ (1,0) [0|0] "" Vector__XXX
 SG_ ErrorRegisterReserved : 22|1@1+ (1,0) [0|0] "" Vector__XXX
 SG_ ErrorRegisterProfileSpecific : 21|1@1+ (1,0) [0|0] "" Vector__XXX
 SG_ ErrorRegisterCommunication : 20|1@1+ (1,0) [0|0] "" Vector__XXX
 SG_ ErrorRegisterTemperature : 19|1@1+ (1,0) [0|0] "" Vector__XXX
 SG_ ErrorRegisterVoltage : 18|1@1+ (1,0) [0|0] "" Vector__XXX
 SG_ ErrorRegisterCurrent : 17|1@1+ (1,0) [0|0] "" Vector__XXX
 SG_ ErrorRegisterGeneric : 16|1@1+ (1,0) [0|0] "" Vector__XXX
 SG_ ErrorCode : 0|16@1+ (1,0) [0|0] "" Vector__XXX

BO_ 1827 HBGuard_035: 1 Vector__XXX
 SG_ Toggle : 7|1@1+ (1,0) [0|0] "" Vector__XXX
 SG_ State : 0|7@1+ (1,0) [0|0] "" Vector__XXX

BO_ 1443 SSDO_035: 8 Vector__XXX

BO_ 1571 CSDO_035: 8 Vector__XXX

BO_ 163 EMCY_035: 8 Vector__XXX
 SG_ ManufacturerSpecific5 : 56|8@1+ (1,0) [0|0] "" Vector__XXX
 SG_ ManufacturerSpecific4 : 48|8@1+ (1,0) [0|0] "" Vector__XXX
 SG_ ManufacturerSpecific3 : 40|8@1+ (1,0) [0|0] "" Vector__XXX
 SG_ ManufacturerSpecific2 : 32|8@1+ (1,0) [0|0] "" Vector__XXX
 SG_ ManufacturerSpecific1 : 24|8@1+ (1,0) [0|0] "" Vector__XXX
 SG_ ErrorRegisterManufSpecific : 23|1@1+ (1,0) [0|0] "" Vector__XXX
 SG_ ErrorRegisterReserved : 22|1@1+ (1,0) [0|0] "" Vector__XXX
 SG_ ErrorRegisterProfileSpecific : 21|1@1+ (1,0) [0|0] "" Vector__XXX
 SG_ ErrorRegisterCommunication : 20|1@1+ (1,0) [0|0] "" Vector__XXX
 SG_ ErrorRegisterTemperature : 19|1@1+ (1,0) [0|0] "" Vector__XXX
 SG_ ErrorRegisterVoltage : 18|1@1+ (1,0) [0|0] "" Vector__XXX
 SG_ ErrorRegisterCurrent : 17|1@1+ (1,0) [0|0] "" Vector__XXX
 SG_ ErrorRegisterGeneric : 16|1@1+ (1,0) [0|0] "" Vector__XXX
 SG_ ErrorCode : 0|16@1+ (1,0) [0|0] "" Vector__XXX

BO_ 1826 HBGuard_034: 1 Vector__XXX
 SG_ Toggle : 7|1@1+ (1,0) [0|0] "" Vector__XXX
 SG_ State : 0|7@1+ (1,0) [0|0] "" Vector__XXX

BO_ 1442 SSDO_034: 8 Vector__XXX

BO_ 1570 CSDO_034: 8 Vector__XXX

BO_ 162 EMCY_034: 8 Vector__XXX
 SG_ ManufacturerSpecific5 : 56|8@1+ (1,0) [0|0] "" Vector__XXX
 SG_ ManufacturerSpecific4 : 48|8@1+ (1,0) [0|0] "" Vector__XXX
 SG_ ManufacturerSpecific3 : 40|8@1+ (1,0) [0|0] "" Vector__XXX
 SG_ ManufacturerSpecific2 : 32|8@1+ (1,0) [0|0] "" Vector__XXX
 SG_ ManufacturerSpecific1 : 24|8@1+ (1,0) [0|0] "" Vector__XXX
 SG_ ErrorRegisterManufSpecific : 23|1@1+ (1,0) [0|0] "" Vector__XXX
 SG_ ErrorRegisterReserved : 22|1@1+ (1,0) [0|0] "" Vector__XXX
 SG_ ErrorRegisterProfileSpecific : 21|1@1+ (1,0) [0|0] "" Vector__XXX
 SG_ ErrorRegisterCommunication : 20|1@1+ (1,0) [0|0] "" Vector__XXX
 SG_ ErrorRegisterTemperature : 19|1@1+ (1,0) [0|0] "" Vector__XXX
 SG_ ErrorRegisterVoltage : 18|1@1+ (1,0) [0|0] "" Vector__XXX
 SG_ ErrorRegisterCurrent : 17|1@1+ (1,0) [0|0] "" Vector__XXX
 SG_ ErrorRegisterGeneric : 16|1@1+ (1,0) [0|0] "" Vector__XXX
 SG_ ErrorCode : 0|16@1+ (1,0) [0|0] "" Vector__XXX

BO_ 1825 HBGuard_033: 1 Vector__XXX
 SG_ Toggle : 7|1@1+ (1,0) [0|0] "" Vector__XXX
 SG_ State : 0|7@1+ (1,0) [0|0] "" Vector__XXX

BO_ 1441 SSDO_033: 8 Vector__XXX

BO_ 1569 CSDO_033: 8 Vector__XXX

BO_ 161 EMCY_033: 8 Vector__XXX
 SG_ ManufacturerSpecific5 : 56|8@1+ (1,0) [0|0] "" Vector__XXX
 SG_ ManufacturerSpecific4 : 48|8@1+ (1,0) [0|0] "" Vector__XXX
 SG_ ManufacturerSpecific3 : 40|8@1+ (1,0) [0|0] "" Vector__XXX
 SG_ ManufacturerSpecific2 : 32|8@1+ (1,0) [0|0] "" Vector__XXX
 SG_ ManufacturerSpecific1 : 24|8@1+ (1,0) [0|0] "" Vector__XXX
 SG_ ErrorRegisterManufSpecific : 23|1@1+ (1,0) [0|0] "" Vector__XXX
 SG_ ErrorRegisterReserved : 22|1@1+ (1,0) [0|0] "" Vector__XXX
 SG_ ErrorRegisterProfileSpecific : 21|1@1+ (1,0) [0|0] "" Vector__XXX
 SG_ ErrorRegisterCommunication : 20|1@1+ (1,0) [0|0] "" Vector__XXX
 SG_ ErrorRegisterTemperature : 19|1@1+ (1,0) [0|0] "" Vector__XXX
 SG_ ErrorRegisterVoltage : 18|1@1+ (1,0) [0|0] "" Vector__XXX
 SG_ ErrorRegisterCurrent : 17|1@1+ (1,0) [0|0] "" Vector__XXX
 SG_ ErrorRegisterGeneric : 16|1@1+ (1,0) [0|0] "" Vector__XXX
 SG_ ErrorCode : 0|16@1+ (1,0) [0|0] "" Vector__XXX

BO_ 1824 HBGuard_032: 1 Vector__XXX
 SG_ Toggle : 7|1@1+ (1,0) [0|0] "" Vector__XXX
 SG_ State : 0|7@1+ (1,0) [0|0] "" Vector__XXX

BO_ 1440 SSDO_032: 8 Vector__XXX

BO_ 1568 CSDO_032: 8 Vector__XXX

BO_ 160 EMCY_032: 8 Vector__XXX
 SG_ ManufacturerSpecific5 : 56|8@1+ (1,0) [0|0] "" Vector__XXX
 SG_ ManufacturerSpecific4 : 48|8@1+ (1,0) [0|0] "" Vector__XXX
 SG_ ManufacturerSpecific3 : 40|8@1+ (1,0) [0|0] "" Vector__XXX
 SG_ ManufacturerSpecific2 : 32|8@1+ (1,0) [0|0] "" Vector__XXX
 SG_ ManufacturerSpecific1 : 24|8@1+ (1,0) [0|0] "" Vector__XXX
 SG_ ErrorRegisterManufSpecific : 23|1@1+ (1,0) [0|0] "" Vector__XXX
 SG_ ErrorRegisterReserved : 22|1@1+ (1,0) [0|0] "" Vector__XXX
 SG_ ErrorRegisterProfileSpecific : 21|1@1+ (1,0) [0|0] "" Vector__XXX
 SG_ ErrorRegisterCommunication : 20|1@1+ (1,0) [0|0] "" Vector__XXX
 SG_ ErrorRegisterTemperature : 19|1@1+ (1,0) [0|0] "" Vector__XXX
 SG_ ErrorRegisterVoltage : 18|1@1+ (1,0) [0|0] "" Vector__XXX
 SG_ ErrorRegisterCurrent : 17|1@1+ (1,0) [0|0] "" Vector__XXX
 SG_ ErrorRegisterGeneric : 16|1@1+ (1,0) [0|0] "" Vector__XXX
 SG_ ErrorCode : 0|16@1+ (1,0) [0|0] "" Vector__XXX

BO_ 1823 HBGuard_031: 1 Vector__XXX
 SG_ Toggle : 7|1@1+ (1,0) [0|0] "" Vector__XXX
 SG_ State : 0|7@1+ (1,0) [0|0] "" Vector__XXX

BO_ 1439 SSDO_031: 8 Vector__XXX

BO_ 1567 CSDO_031: 8 Vector__XXX

BO_ 159 EMCY_031: 8 Vector__XXX
 SG_ ManufacturerSpecific5 : 56|8@1+ (1,0) [0|0] "" Vector__XXX
 SG_ ManufacturerSpecific4 : 48|8@1+ (1,0) [0|0] "" Vector__XXX
 SG_ ManufacturerSpecific3 : 40|8@1+ (1,0) [0|0] "" Vector__XXX
 SG_ ManufacturerSpecific2 : 32|8@1+ (1,0) [0|0] "" Vector__XXX
 SG_ ManufacturerSpecific1 : 24|8@1+ (1,0) [0|0] "" Vector__XXX
 SG_ ErrorRegisterManufSpecific : 23|1@1+ (1,0) [0|0] "" Vector__XXX
 SG_ ErrorRegisterReserved : 22|1@1+ (1,0) [0|0] "" Vector__XXX
 SG_ ErrorRegisterProfileSpecific : 21|1@1+ (1,0) [0|0] "" Vector__XXX
 SG_ ErrorRegisterCommunication : 20|1@1+ (1,0) [0|0] "" Vector__XXX
 SG_ ErrorRegisterTemperature : 19|1@1+ (1,0) [0|0] "" Vector__XXX
 SG_ ErrorRegisterVoltage : 18|1@1+ (1,0) [0|0] "" Vector__XXX
 SG_ ErrorRegisterCurrent : 17|1@1+ (1,0) [0|0] "" Vector__XXX
 SG_ ErrorRegisterGeneric : 16|1@1+ (1,0) [0|0] "" Vector__XXX
 SG_ ErrorCode : 0|16@1+ (1,0) [0|0] "" Vector__XXX

BO_ 1822 HBGuard_030: 1 Vector__XXX
 SG_ Toggle : 7|1@1+ (1,0) [0|0] "" Vector__XXX
 SG_ State : 0|7@1+ (1,0) [0|0] "" Vector__XXX

BO_ 1438 SSDO_030: 8 Vector__XXX

BO_ 1566 CSDO_030: 8 Vector__XXX

BO_ 158 EMCY_030: 8 Vector__XXX
 SG_ ManufacturerSpecific5 : 56|8@1+ (1,0) [0|0] "" Vector__XXX
 SG_ ManufacturerSpecific4 : 48|8@1+ (1,0) [0|0] "" Vector__XXX
 SG_ ManufacturerSpecific3 : 40|8@1+ (1,0) [0|0] "" Vector__XXX
 SG_ ManufacturerSpecific2 : 32|8@1+ (1,0) [0|0] "" Vector__XXX
 SG_ ManufacturerSpecific1 : 24|8@1+ (1,0) [0|0] "" Vector__XXX
 SG_ ErrorRegisterManufSpecific : 23|1@1+ (1,0) [0|0] "" Vector__XXX
 SG_ ErrorRegisterReserved : 22|1@1+ (1,0) [0|0] "" Vector__XXX
 SG_ ErrorRegisterProfileSpecific : 21|1@1+ (1,0) [0|0] "" Vector__XXX
 SG_ ErrorRegisterCommunication : 20|1@1+ (1,0) [0|0] "" Vector__XXX
 SG_ ErrorRegisterTemperature : 19|1@1+ (1,0) [0|0] "" Vector__XXX
 SG_ ErrorRegisterVoltage : 18|1@1+ (1,0) [0|0] "" Vector__XXX
 SG_ ErrorRegisterCurrent : 17|1@1+ (1,0) [0|0] "" Vector__XXX
 SG_ ErrorRegisterGeneric : 16|1@1+ (1,0) [0|0] "" Vector__XXX
 SG_ ErrorCode : 0|16@1+ (1,0) [0|0] "" Vector__XXX

BO_ 1821 HBGuard_029: 1 Vector__XXX
 SG_ Toggle : 7|1@1+ (1,0) [0|0] "" Vector__XXX
 SG_ State : 0|7@1+ (1,0) [0|0] "" Vector__XXX

BO_ 1437 SSDO_029: 8 Vector__XXX

BO_ 1565 CSDO_029: 8 Vector__XXX

BO_ 157 EMCY_029: 8 Vector__XXX
 SG_ ManufacturerSpecific5 : 56|8@1+ (1,0) [0|0] "" Vector__XXX
 SG_ ManufacturerSpecific4 : 48|8@1+ (1,0) [0|0] "" Vector__XXX
 SG_ ManufacturerSpecific3 : 40|8@1+ (1,0) [0|0] "" Vector__XXX
 SG_ ManufacturerSpecific2 : 32|8@1+ (1,0) [0|0] "" Vector__XXX
 SG_ ManufacturerSpecific1 : 24|8@1+ (1,0) [0|0] "" Vector__XXX
 SG_ ErrorRegisterManufSpecific : 23|1@1+ (1,0) [0|0] "" Vector__XXX
 SG_ ErrorRegisterReserved : 22|1@1+ (1,0) [0|0] "" Vector__XXX
 SG_ ErrorRegisterProfileSpecific : 21|1@1+ (1,0) [0|0] "" Vector__XXX
 SG_ ErrorRegisterCommunication : 20|1@1+ (1,0) [0|0] "" Vector__XXX
 SG_ ErrorRegisterTemperature : 19|1@1+ (1,0) [0|0] "" Vector__XXX
 SG_ ErrorRegisterVoltage : 18|1@1+ (1,0) [0|0] "" Vector__XXX
 SG_ ErrorRegisterCurrent : 17|1@1+ (1,0) [0|0] "" Vector__XXX
 SG_ ErrorRegisterGeneric : 16|1@1+ (1,0) [0|0] "" Vector__XXX
 SG_ ErrorCode : 0|16@1+ (1,0) [0|0] "" Vector__XXX

BO_ 1820 HBGuard_028: 1 Vector__XXX
 SG_ Toggle : 7|1@1+ (1,0) [0|0] "" Vector__XXX
 SG_ State : 0|7@1+ (1,0) [0|0] "" Vector__XXX

BO_ 1436 SSDO_028: 8 Vector__XXX

BO_ 1564 CSDO_028: 8 Vector__XXX

BO_ 156 EMCY_028: 8 Vector__XXX
 SG_ ManufacturerSpecific5 : 56|8@1+ (1,0) [0|0] "" Vector__XXX
 SG_ ManufacturerSpecific4 : 48|8@1+ (1,0) [0|0] "" Vector__XXX
 SG_ ManufacturerSpecific3 : 40|8@1+ (1,0) [0|0] "" Vector__XXX
 SG_ ManufacturerSpecific2 : 32|8@1+ (1,0) [0|0] "" Vector__XXX
 SG_ ManufacturerSpecific1 : 24|8@1+ (1,0) [0|0] "" Vector__XXX
 SG_ ErrorRegisterManufSpecific : 23|1@1+ (1,0) [0|0] "" Vector__XXX
 SG_ ErrorRegisterReserved : 22|1@1+ (1,0) [0|0] "" Vector__XXX
 SG_ ErrorRegisterProfileSpecific : 21|1@1+ (1,0) [0|0] "" Vector__XXX
 SG_ ErrorRegisterCommunication : 20|1@1+ (1,0) [0|0] "" Vector__XXX
 SG_ ErrorRegisterTemperature : 19|1@1+ (1,0) [0|0] "" Vector__XXX
 SG_ ErrorRegisterVoltage : 18|1@1+ (1,0) [0|0] "" Vector__XXX
 SG_ ErrorRegisterCurrent : 17|1@1+ (1,0) [0|0] "" Vector__XXX
 SG_ ErrorRegisterGeneric : 16|1@1+ (1,0) [0|0] "" Vector__XXX
 SG_ ErrorCode : 0|16@1+ (1,0) [0|0] "" Vector__XXX

BO_ 1819 HBGuard_027: 1 Vector__XXX
 SG_ Toggle : 7|1@1+ (1,0) [0|0] "" Vector__XXX
 SG_ State : 0|7@1+ (1,0) [0|0] "" Vector__XXX

BO_ 1435 SSDO_027: 8 Vector__XXX

BO_ 1563 CSDO_027: 8 Vector__XXX

BO_ 155 EMCY_027: 8 Vector__XXX
 SG_ ManufacturerSpecific5 : 56|8@1+ (1,0) [0|0] "" Vector__XXX
 SG_ ManufacturerSpecific4 : 48|8@1+ (1,0) [0|0] "" Vector__XXX
 SG_ ManufacturerSpecific3 : 40|8@1+ (1,0) [0|0] "" Vector__XXX
 SG_ ManufacturerSpecific2 : 32|8@1+ (1,0) [0|0] "" Vector__XXX
 SG_ ManufacturerSpecific1 : 24|8@1+ (1,0) [0|0] "" Vector__XXX
 SG_ ErrorRegisterManufSpecific : 23|1@1+ (1,0) [0|0] "" Vector__XXX
 SG_ ErrorRegisterReserved : 22|1@1+ (1,0) [0|0] "" Vector__XXX
 SG_ ErrorRegisterProfileSpecific : 21|1@1+ (1,0) [0|0] "" Vector__XXX
 SG_ ErrorRegisterCommunication : 20|1@1+ (1,0) [0|0] "" Vector__XXX
 SG_ ErrorRegisterTemperature : 19|1@1+ (1,0) [0|0] "" Vector__XXX
 SG_ ErrorRegisterVoltage : 18|1@1+ (1,0) [0|0] "" Vector__XXX
 SG_ ErrorRegisterCurrent : 17|1@1+ (1,0) [0|0] "" Vector__XXX
 SG_ ErrorRegisterGeneric : 16|1@1+ (1,0) [0|0] "" Vector__XXX
 SG_ ErrorCode : 0|16@1+ (1,0) [0|0] "" Vector__XXX

BO_ 1818 HBGuard_026: 1 Vector__XXX
 SG_ Toggle : 7|1@1+ (1,0) [0|0] "" Vector__XXX
 SG_ State : 0|7@1+ (1,0) [0|0] "" Vector__XXX

BO_ 1434 SSDO_026: 8 Vector__XXX

BO_ 1562 CSDO_026: 8 Vector__XXX

BO_ 154 EMCY_026: 8 Vector__XXX
 SG_ ManufacturerSpecific5 : 56|8@1+ (1,0) [0|0] "" Vector__XXX
 SG_ ManufacturerSpecific4 : 48|8@1+ (1,0) [0|0] "" Vector__XXX
 SG_ ManufacturerSpecific3 : 40|8@1+ (1,0) [0|0] "" Vector__XXX
 SG_ ManufacturerSpecific2 : 32|8@1+ (1,0) [0|0] "" Vector__XXX
 SG_ ManufacturerSpecific1 : 24|8@1+ (1,0) [0|0] "" Vector__XXX
 SG_ ErrorRegisterManufSpecific : 23|1@1+ (1,0) [0|0] "" Vector__XXX
 SG_ ErrorRegisterReserved : 22|1@1+ (1,0) [0|0] "" Vector__XXX
 SG_ ErrorRegisterProfileSpecific : 21|1@1+ (1,0) [0|0] "" Vector__XXX
 SG_ ErrorRegisterCommunication : 20|1@1+ (1,0) [0|0] "" Vector__XXX
 SG_ ErrorRegisterTemperature : 19|1@1+ (1,0) [0|0] "" Vector__XXX
 SG_ ErrorRegisterVoltage : 18|1@1+ (1,0) [0|0] "" Vector__XXX
 SG_ ErrorRegisterCurrent : 17|1@1+ (1,0) [0|0] "" Vector__XXX
 SG_ ErrorRegisterGeneric : 16|1@1+ (1,0) [0|0] "" Vector__XXX
 SG_ ErrorCode : 0|16@1+ (1,0) [0|0] "" Vector__XXX

BO_ 1817 HBGuard_025: 1 Vector__XXX
 SG_ Toggle : 7|1@1+ (1,0) [0|0] "" Vector__XXX
 SG_ State : 0|7@1+ (1,0) [0|0] "" Vector__XXX

BO_ 1433 SSDO_025: 8 Vector__XXX

BO_ 1561 CSDO_025: 8 Vector__XXX

BO_ 153 EMCY_025: 8 Vector__XXX
 SG_ ManufacturerSpecific5 : 56|8@1+ (1,0) [0|0] "" Vector__XXX
 SG_ ManufacturerSpecific4 : 48|8@1+ (1,0) [0|0] "" Vector__XXX
 SG_ ManufacturerSpecific3 : 40|8@1+ (1,0) [0|0] "" Vector__XXX
 SG_ ManufacturerSpecific2 : 32|8@1+ (1,0) [0|0] "" Vector__XXX
 SG_ ManufacturerSpecific1 : 24|8@1+ (1,0) [0|0] "" Vector__XXX
 SG_ ErrorRegisterManufSpecific : 23|1@1+ (1,0) [0|0] "" Vector__XXX
 SG_ ErrorRegisterReserved : 22|1@1+ (1,0) [0|0] "" Vector__XXX
 SG_ ErrorRegisterProfileSpecific : 21|1@1+ (1,0) [0|0] "" Vector__XXX
 SG_ ErrorRegisterCommunication : 20|1@1+ (1,0) [0|0] "" Vector__XXX
 SG_ ErrorRegisterTemperature : 19|1@1+ (1,0) [0|0] "" Vector__XXX
 SG_ ErrorRegisterVoltage : 18|1@1+ (1,0) [0|0] "" Vector__XXX
 SG_ ErrorRegisterCurrent : 17|1@1+ (1,0) [0|0] "" Vector__XXX
 SG_ ErrorRegisterGeneric : 16|1@1+ (1,0) [0|0] "" Vector__XXX
 SG_ ErrorCode : 0|16@1+ (1,0) [0|0] "" Vector__XXX

BO_ 1816 HBGuard_024: 1 Vector__XXX
 SG_ Toggle : 7|1@1+ (1,0) [0|0] "" Vector__XXX
 SG_ State : 0|7@1+ (1,0) [0|0] "" Vector__XXX

BO_ 1432 SSDO_024: 8 Vector__XXX

BO_ 1560 CSDO_024: 8 Vector__XXX

BO_ 152 EMCY_024: 8 Vector__XXX
 SG_ ManufacturerSpecific5 : 56|8@1+ (1,0) [0|0] "" Vector__XXX
 SG_ ManufacturerSpecific4 : 48|8@1+ (1,0) [0|0] "" Vector__XXX
 SG_ ManufacturerSpecific3 : 40|8@1+ (1,0) [0|0] "" Vector__XXX
 SG_ ManufacturerSpecific2 : 32|8@1+ (1,0) [0|0] "" Vector__XXX
 SG_ ManufacturerSpecific1 : 24|8@1+ (1,0) [0|0] "" Vector__XXX
 SG_ ErrorRegisterManufSpecific : 23|1@1+ (1,0) [0|0] "" Vector__XXX
 SG_ ErrorRegisterReserved : 22|1@1+ (1,0) [0|0] "" Vector__XXX
 SG_ ErrorRegisterProfileSpecific : 21|1@1+ (1,0) [0|0] "" Vector__XXX
 SG_ ErrorRegisterCommunication : 20|1@1+ (1,0) [0|0] "" Vector__XXX
 SG_ ErrorRegisterTemperature : 19|1@1+ (1,0) [0|0] "" Vector__XXX
 SG_ ErrorRegisterVoltage : 18|1@1+ (1,0) [0|0] "" Vector__XXX
 SG_ ErrorRegisterCurrent : 17|1@1+ (1,0) [0|0] "" Vector__XXX
 SG_ ErrorRegisterGeneric : 16|1@1+ (1,0) [0|0] "" Vector__XXX
 SG_ ErrorCode : 0|16@1+ (1,0) [0|0] "" Vector__XXX

BO_ 1815 HBGuard_023: 1 Vector__XXX
 SG_ Toggle : 7|1@1+ (1,0) [0|0] "" Vector__XXX
 SG_ State : 0|7@1+ (1,0) [0|0] "" Vector__XXX

BO_ 1431 SSDO_023: 8 Vector__XXX

BO_ 1559 CSDO_023: 8 Vector__XXX

BO_ 151 EMCY_023: 8 Vector__XXX
 SG_ ManufacturerSpecific5 : 56|8@1+ (1,0) [0|0] "" Vector__XXX
 SG_ ManufacturerSpecific4 : 48|8@1+ (1,0) [0|0] "" Vector__XXX
 SG_ ManufacturerSpecific3 : 40|8@1+ (1,0) [0|0] "" Vector__XXX
 SG_ ManufacturerSpecific2 : 32|8@1+ (1,0) [0|0] "" Vector__XXX
 SG_ ManufacturerSpecific1 : 24|8@1+ (1,0) [0|0] "" Vector__XXX
 SG_ ErrorRegisterManufSpecific : 23|1@1+ (1,0) [0|0] "" Vector__XXX
 SG_ ErrorRegisterReserved : 22|1@1+ (1,0) [0|0] "" Vector__XXX
 SG_ ErrorRegisterProfileSpecific : 21|1@1+ (1,0) [0|0] "" Vector__XXX
 SG_ ErrorRegisterCommunication : 20|1@1+ (1,0) [0|0] "" Vector__XXX
 SG_ ErrorRegisterTemperature : 19|1@1+ (1,0) [0|0] "" Vector__XXX
 SG_ ErrorRegisterVoltage : 18|1@1+ (1,0) [0|0] "" Vector__XXX
 SG_ ErrorRegisterCurrent : 17|1@1+ (1,0) [0|0] "" Vector__XXX
 SG_ ErrorRegisterGeneric : 16|1@1+ (1,0) [0|0] "" Vector__XXX
 SG_ ErrorCode : 0|16@1+ (1,0) [0|0] "" Vector__XXX

BO_ 1814 HBGuard_022: 1 Vector__XXX
 SG_ Toggle : 7|1@1+ (1,0) [0|0] "" Vector__XXX
 SG_ State : 0|7@1+ (1,0) [0|0] "" Vector__XXX

BO_ 1430 SSDO_022: 8 Vector__XXX

BO_ 1558 CSDO_022: 8 Vector__XXX

BO_ 150 EMCY_022: 8 Vector__XXX
 SG_ ManufacturerSpecific5 : 56|8@1+ (1,0) [0|0] "" Vector__XXX
 SG_ ManufacturerSpecific4 : 48|8@1+ (1,0) [0|0] "" Vector__XXX
 SG_ ManufacturerSpecific3 : 40|8@1+ (1,0) [0|0] "" Vector__XXX
 SG_ ManufacturerSpecific2 : 32|8@1+ (1,0) [0|0] "" Vector__XXX
 SG_ ManufacturerSpecific1 : 24|8@1+ (1,0) [0|0] "" Vector__XXX
 SG_ ErrorRegisterManufSpecific : 23|1@1+ (1,0) [0|0] "" Vector__XXX
 SG_ ErrorRegisterReserved : 22|1@1+ (1,0) [0|0] "" Vector__XXX
 SG_ ErrorRegisterProfileSpecific : 21|1@1+ (1,0) [0|0] "" Vector__XXX
 SG_ ErrorRegisterCommunication : 20|1@1+ (1,0) [0|0] "" Vector__XXX
 SG_ ErrorRegisterTemperature : 19|1@1+ (1,0) [0|0] "" Vector__XXX
 SG_ ErrorRegisterVoltage : 18|1@1+ (1,0) [0|0] "" Vector__XXX
 SG_ ErrorRegisterCurrent : 17|1@1+ (1,0) [0|0] "" Vector__XXX
 SG_ ErrorRegisterGeneric : 16|1@1+ (1,0) [0|0] "" Vector__XXX
 SG_ ErrorCode : 0|16@1+ (1,0) [0|0] "" Vector__XXX

BO_ 1812 HBGuard_020: 1 Vector__XXX
 SG_ Toggle : 7|1@1+ (1,0) [0|0] "" Vector__XXX
 SG_ State : 0|7@1+ (1,0) [0|0] "" Vector__XXX

BO_ 1428 SSDO_020: 8 Vector__XXX

BO_ 1556 CSDO_020: 8 Vector__XXX

BO_ 148 EMCY_020: 8 Vector__XXX
 SG_ ManufacturerSpecific5 : 56|8@1+ (1,0) [0|0] "" Vector__XXX
 SG_ ManufacturerSpecific4 : 48|8@1+ (1,0) [0|0] "" Vector__XXX
 SG_ ManufacturerSpecific3 : 40|8@1+ (1,0) [0|0] "" Vector__XXX
 SG_ ManufacturerSpecific2 : 32|8@1+ (1,0) [0|0] "" Vector__XXX
 SG_ ManufacturerSpecific1 : 24|8@1+ (1,0) [0|0] "" Vector__XXX
 SG_ ErrorRegisterManufSpecific : 23|1@1+ (1,0) [0|0] "" Vector__XXX
 SG_ ErrorRegisterReserved : 22|1@1+ (1,0) [0|0] "" Vector__XXX
 SG_ ErrorRegisterProfileSpecific : 21|1@1+ (1,0) [0|0] "" Vector__XXX
 SG_ ErrorRegisterCommunication : 20|1@1+ (1,0) [0|0] "" Vector__XXX
 SG_ ErrorRegisterTemperature : 19|1@1+ (1,0) [0|0] "" Vector__XXX
 SG_ ErrorRegisterVoltage : 18|1@1+ (1,0) [0|0] "" Vector__XXX
 SG_ ErrorRegisterCurrent : 17|1@1+ (1,0) [0|0] "" Vector__XXX
 SG_ ErrorRegisterGeneric : 16|1@1+ (1,0) [0|0] "" Vector__XXX
 SG_ ErrorCode : 0|16@1+ (1,0) [0|0] "" Vector__XXX

BO_ 1811 HBGuard_019: 1 Vector__XXX
 SG_ Toggle : 7|1@1+ (1,0) [0|0] "" Vector__XXX
 SG_ State : 0|7@1+ (1,0) [0|0] "" Vector__XXX

BO_ 1427 SSDO_019: 8 Vector__XXX

BO_ 1555 CSDO_019: 8 Vector__XXX

BO_ 147 EMCY_019: 8 Vector__XXX
 SG_ ManufacturerSpecific5 : 56|8@1+ (1,0) [0|0] "" Vector__XXX
 SG_ ManufacturerSpecific4 : 48|8@1+ (1,0) [0|0] "" Vector__XXX
 SG_ ManufacturerSpecific3 : 40|8@1+ (1,0) [0|0] "" Vector__XXX
 SG_ ManufacturerSpecific2 : 32|8@1+ (1,0) [0|0] "" Vector__XXX
 SG_ ManufacturerSpecific1 : 24|8@1+ (1,0) [0|0] "" Vector__XXX
 SG_ ErrorRegisterManufSpecific : 23|1@1+ (1,0) [0|0] "" Vector__XXX
 SG_ ErrorRegisterReserved : 22|1@1+ (1,0) [0|0] "" Vector__XXX
 SG_ ErrorRegisterProfileSpecific : 21|1@1+ (1,0) [0|0] "" Vector__XXX
 SG_ ErrorRegisterCommunication : 20|1@1+ (1,0) [0|0] "" Vector__XXX
 SG_ ErrorRegisterTemperature : 19|1@1+ (1,0) [0|0] "" Vector__XXX
 SG_ ErrorRegisterVoltage : 18|1@1+ (1,0) [0|0] "" Vector__XXX
 SG_ ErrorRegisterCurrent : 17|1@1+ (1,0) [0|0] "" Vector__XXX
 SG_ ErrorRegisterGeneric : 16|1@1+ (1,0) [0|0] "" Vector__XXX
 SG_ ErrorCode : 0|16@1+ (1,0) [0|0] "" Vector__XXX

BO_ 1810 HBGuard_018: 1 Vector__XXX
 SG_ Toggle : 7|1@1+ (1,0) [0|0] "" Vector__XXX
 SG_ State : 0|7@1+ (1,0) [0|0] "" Vector__XXX

BO_ 1426 SSDO_018: 8 Vector__XXX

BO_ 1554 CSDO_018: 8 Vector__XXX

BO_ 146 EMCY_018: 8 Vector__XXX
 SG_ ManufacturerSpecific5 : 56|8@1+ (1,0) [0|0] "" Vector__XXX
 SG_ ManufacturerSpecific4 : 48|8@1+ (1,0) [0|0] "" Vector__XXX
 SG_ ManufacturerSpecific3 : 40|8@1+ (1,0) [0|0] "" Vector__XXX
 SG_ ManufacturerSpecific2 : 32|8@1+ (1,0) [0|0] "" Vector__XXX
 SG_ ManufacturerSpecific1 : 24|8@1+ (1,0) [0|0] "" Vector__XXX
 SG_ ErrorRegisterManufSpecific : 23|1@1+ (1,0) [0|0] "" Vector__XXX
 SG_ ErrorRegisterReserved : 22|1@1+ (1,0) [0|0] "" Vector__XXX
 SG_ ErrorRegisterProfileSpecific : 21|1@1+ (1,0) [0|0] "" Vector__XXX
 SG_ ErrorRegisterCommunication : 20|1@1+ (1,0) [0|0] "" Vector__XXX
 SG_ ErrorRegisterTemperature : 19|1@1+ (1,0) [0|0] "" Vector__XXX
 SG_ ErrorRegisterVoltage : 18|1@1+ (1,0) [0|0] "" Vector__XXX
 SG_ ErrorRegisterCurrent : 17|1@1+ (1,0) [0|0] "" Vector__XXX
 SG_ ErrorRegisterGeneric : 16|1@1+ (1,0) [0|0] "" Vector__XXX
 SG_ ErrorCode : 0|16@1+ (1,0) [0|0] "" Vector__XXX

BO_ 1809 HBGuard_017: 1 Vector__XXX
 SG_ Toggle : 7|1@1+ (1,0) [0|0] "" Vector__XXX
 SG_ State : 0|7@1+ (1,0) [0|0] "" Vector__XXX

BO_ 1425 SSDO_017: 8 Vector__XXX

BO_ 1553 CSDO_017: 8 Vector__XXX

BO_ 145 EMCY_017: 8 Vector__XXX
 SG_ ManufacturerSpecific5 : 56|8@1+ (1,0) [0|0] "" Vector__XXX
 SG_ ManufacturerSpecific4 : 48|8@1+ (1,0) [0|0] "" Vector__XXX
 SG_ ManufacturerSpecific3 : 40|8@1+ (1,0) [0|0] "" Vector__XXX
 SG_ ManufacturerSpecific2 : 32|8@1+ (1,0) [0|0] "" Vector__XXX
 SG_ ManufacturerSpecific1 : 24|8@1+ (1,0) [0|0] "" Vector__XXX
 SG_ ErrorRegisterManufSpecific : 23|1@1+ (1,0) [0|0] "" Vector__XXX
 SG_ ErrorRegisterReserved : 22|1@1+ (1,0) [0|0] "" Vector__XXX
 SG_ ErrorRegisterProfileSpecific : 21|1@1+ (1,0) [0|0] "" Vector__XXX
 SG_ ErrorRegisterCommunication : 20|1@1+ (1,0) [0|0] "" Vector__XXX
 SG_ ErrorRegisterTemperature : 19|1@1+ (1,0) [0|0] "" Vector__XXX
 SG_ ErrorRegisterVoltage : 18|1@1+ (1,0) [0|0] "" Vector__XXX
 SG_ ErrorRegisterCurrent : 17|1@1+ (1,0) [0|0] "" Vector__XXX
 SG_ ErrorRegisterGeneric : 16|1@1+ (1,0) [0|0] "" Vector__XXX
 SG_ ErrorCode : 0|16@1+ (1,0) [0|0] "" Vector__XXX

BO_ 1808 HBGuard_016: 1 Vector__XXX
 SG_ Toggle : 7|1@1+ (1,0) [0|0] "" Vector__XXX
 SG_ State : 0|7@1+ (1,0) [0|0] "" Vector__XXX

BO_ 1424 SSDO_016: 8 Vector__XXX

BO_ 1552 CSDO_016: 8 Vector__XXX

BO_ 144 EMCY_016: 8 Vector__XXX
 SG_ ManufacturerSpecific5 : 56|8@1+ (1,0) [0|0] "" Vector__XXX
 SG_ ManufacturerSpecific4 : 48|8@1+ (1,0) [0|0] "" Vector__XXX
 SG_ ManufacturerSpecific3 : 40|8@1+ (1,0) [0|0] "" Vector__XXX
 SG_ ManufacturerSpecific2 : 32|8@1+ (1,0) [0|0] "" Vector__XXX
 SG_ ManufacturerSpecific1 : 24|8@1+ (1,0) [0|0] "" Vector__XXX
 SG_ ErrorRegisterManufSpecific : 23|1@1+ (1,0) [0|0] "" Vector__XXX
 SG_ ErrorRegisterReserved : 22|1@1+ (1,0) [0|0] "" Vector__XXX
 SG_ ErrorRegisterProfileSpecific : 21|1@1+ (1,0) [0|0] "" Vector__XXX
 SG_ ErrorRegisterCommunication : 20|1@1+ (1,0) [0|0] "" Vector__XXX
 SG_ ErrorRegisterTemperature : 19|1@1+ (1,0) [0|0] "" Vector__XXX
 SG_ ErrorRegisterVoltage : 18|1@1+ (1,0) [0|0] "" Vector__XXX
 SG_ ErrorRegisterCurrent : 17|1@1+ (1,0) [0|0] "" Vector__XXX
 SG_ ErrorRegisterGeneric : 16|1@1+ (1,0) [0|0] "" Vector__XXX
 SG_ ErrorCode : 0|16@1+ (1,0) [0|0] "" Vector__XXX

BO_ 1807 HBGuard_015: 1 Vector__XXX
 SG_ Toggle : 7|1@1+ (1,0) [0|0] "" Vector__XXX
 SG_ State : 0|7@1+ (1,0) [0|0] "" Vector__XXX

BO_ 1423 SSDO_015: 8 Vector__XXX

BO_ 1551 CSDO_015: 8 Vector__XXX

BO_ 143 EMCY_015: 8 Vector__XXX
 SG_ ManufacturerSpecific5 : 56|8@1+ (1,0) [0|0] "" Vector__XXX
 SG_ ManufacturerSpecific4 : 48|8@1+ (1,0) [0|0] "" Vector__XXX
 SG_ ManufacturerSpecific3 : 40|8@1+ (1,0) [0|0] "" Vector__XXX
 SG_ ManufacturerSpecific2 : 32|8@1+ (1,0) [0|0] "" Vector__XXX
 SG_ ManufacturerSpecific1 : 24|8@1+ (1,0) [0|0] "" Vector__XXX
 SG_ ErrorRegisterManufSpecific : 23|1@1+ (1,0) [0|0] "" Vector__XXX
 SG_ ErrorRegisterReserved : 22|1@1+ (1,0) [0|0] "" Vector__XXX
 SG_ ErrorRegisterProfileSpecific : 21|1@1+ (1,0) [0|0] "" Vector__XXX
 SG_ ErrorRegisterCommunication : 20|1@1+ (1,0) [0|0] "" Vector__XXX
 SG_ ErrorRegisterTemperature : 19|1@1+ (1,0) [0|0] "" Vector__XXX
 SG_ ErrorRegisterVoltage : 18|1@1+ (1,0) [0|0] "" Vector__XXX
 SG_ ErrorRegisterCurrent : 17|1@1+ (1,0) [0|0] "" Vector__XXX
 SG_ ErrorRegisterGeneric : 16|1@1+ (1,0) [0|0] "" Vector__XXX
 SG_ ErrorCode : 0|16@1+ (1,0) [0|0] "" Vector__XXX

BO_ 1806 HBGuard_014: 1 Vector__XXX
 SG_ Toggle : 7|1@1+ (1,0) [0|0] "" Vector__XXX
 SG_ State : 0|7@1+ (1,0) [0|0] "" Vector__XXX

BO_ 1422 SSDO_014: 8 Vector__XXX

BO_ 1550 CSDO_014: 8 Vector__XXX

BO_ 142 EMCY_014: 8 Vector__XXX
 SG_ ManufacturerSpecific5 : 56|8@1+ (1,0) [0|0] "" Vector__XXX
 SG_ ManufacturerSpecific4 : 48|8@1+ (1,0) [0|0] "" Vector__XXX
 SG_ ManufacturerSpecific3 : 40|8@1+ (1,0) [0|0] "" Vector__XXX
 SG_ ManufacturerSpecific2 : 32|8@1+ (1,0) [0|0] "" Vector__XXX
 SG_ ManufacturerSpecific1 : 24|8@1+ (1,0) [0|0] "" Vector__XXX
 SG_ ErrorRegisterManufSpecific : 23|1@1+ (1,0) [0|0] "" Vector__XXX
 SG_ ErrorRegisterReserved : 22|1@1+ (1,0) [0|0] "" Vector__XXX
 SG_ ErrorRegisterProfileSpecific : 21|1@1+ (1,0) [0|0] "" Vector__XXX
 SG_ ErrorRegisterCommunication : 20|1@1+ (1,0) [0|0] "" Vector__XXX
 SG_ ErrorRegisterTemperature : 19|1@1+ (1,0) [0|0] "" Vector__XXX
 SG_ ErrorRegisterVoltage : 18|1@1+ (1,0) [0|0] "" Vector__XXX
 SG_ ErrorRegisterCurrent : 17|1@1+ (1,0) [0|0] "" Vector__XXX
 SG_ ErrorRegisterGeneric : 16|1@1+ (1,0) [0|0] "" Vector__XXX
 SG_ ErrorCode : 0|16@1+ (1,0) [0|0] "" Vector__XXX

BO_ 1805 HBGuard_013: 1 Vector__XXX
 SG_ Toggle : 7|1@1+ (1,0) [0|0] "" Vector__XXX
 SG_ State : 0|7@1+ (1,0) [0|0] "" Vector__XXX

BO_ 1421 SSDO_013: 8 Vector__XXX

BO_ 1549 CSDO_013: 8 Vector__XXX

BO_ 141 EMCY_013: 8 Vector__XXX
 SG_ ManufacturerSpecific5 : 56|8@1+ (1,0) [0|0] "" Vector__XXX
 SG_ ManufacturerSpecific4 : 48|8@1+ (1,0) [0|0] "" Vector__XXX
 SG_ ManufacturerSpecific3 : 40|8@1+ (1,0) [0|0] "" Vector__XXX
 SG_ ManufacturerSpecific2 : 32|8@1+ (1,0) [0|0] "" Vector__XXX
 SG_ ManufacturerSpecific1 : 24|8@1+ (1,0) [0|0] "" Vector__XXX
 SG_ ErrorRegisterManufSpecific : 23|1@1+ (1,0) [0|0] "" Vector__XXX
 SG_ ErrorRegisterReserved : 22|1@1+ (1,0) [0|0] "" Vector__XXX
 SG_ ErrorRegisterProfileSpecific : 21|1@1+ (1,0) [0|0] "" Vector__XXX
 SG_ ErrorRegisterCommunication : 20|1@1+ (1,0) [0|0] "" Vector__XXX
 SG_ ErrorRegisterTemperature : 19|1@1+ (1,0) [0|0] "" Vector__XXX
 SG_ ErrorRegisterVoltage : 18|1@1+ (1,0) [0|0] "" Vector__XXX
 SG_ ErrorRegisterCurrent : 17|1@1+ (1,0) [0|0] "" Vector__XXX
 SG_ ErrorRegisterGeneric : 16|1@1+ (1,0) [0|0] "" Vector__XXX
 SG_ ErrorCode : 0|16@1+ (1,0) [0|0] "" Vector__XXX

BO_ 1804 HBGuard_012: 1 Vector__XXX
 SG_ Toggle : 7|1@1+ (1,0) [0|0] "" Vector__XXX
 SG_ State : 0|7@1+ (1,0) [0|0] "" Vector__XXX

BO_ 1420 SSDO_012: 8 Vector__XXX

BO_ 1548 CSDO_012: 8 Vector__XXX

BO_ 140 EMCY_012: 8 Vector__XXX
 SG_ ManufacturerSpecific5 : 56|8@1+ (1,0) [0|0] "" Vector__XXX
 SG_ ManufacturerSpecific4 : 48|8@1+ (1,0) [0|0] "" Vector__XXX
 SG_ ManufacturerSpecific3 : 40|8@1+ (1,0) [0|0] "" Vector__XXX
 SG_ ManufacturerSpecific2 : 32|8@1+ (1,0) [0|0] "" Vector__XXX
 SG_ ManufacturerSpecific1 : 24|8@1+ (1,0) [0|0] "" Vector__XXX
 SG_ ErrorRegisterManufSpecific : 23|1@1+ (1,0) [0|0] "" Vector__XXX
 SG_ ErrorRegisterReserved : 22|1@1+ (1,0) [0|0] "" Vector__XXX
 SG_ ErrorRegisterProfileSpecific : 21|1@1+ (1,0) [0|0] "" Vector__XXX
 SG_ ErrorRegisterCommunication : 20|1@1+ (1,0) [0|0] "" Vector__XXX
 SG_ ErrorRegisterTemperature : 19|1@1+ (1,0) [0|0] "" Vector__XXX
 SG_ ErrorRegisterVoltage : 18|1@1+ (1,0) [0|0] "" Vector__XXX
 SG_ ErrorRegisterCurrent : 17|1@1+ (1,0) [0|0] "" Vector__XXX
 SG_ ErrorRegisterGeneric : 16|1@1+ (1,0) [0|0] "" Vector__XXX
 SG_ ErrorCode : 0|16@1+ (1,0) [0|0] "" Vector__XXX

BO_ 1803 HBGuard_011: 1 Vector__XXX
 SG_ Toggle : 7|1@1+ (1,0) [0|0] "" Vector__XXX
 SG_ State : 0|7@1+ (1,0) [0|0] "" Vector__XXX

BO_ 1419 SSDO_011: 8 Vector__XXX

BO_ 1547 CSDO_011: 8 Vector__XXX

BO_ 139 EMCY_011: 8 Vector__XXX
 SG_ ManufacturerSpecific5 : 56|8@1+ (1,0) [0|0] "" Vector__XXX
 SG_ ManufacturerSpecific4 : 48|8@1+ (1,0) [0|0] "" Vector__XXX
 SG_ ManufacturerSpecific3 : 40|8@1+ (1,0) [0|0] "" Vector__XXX
 SG_ ManufacturerSpecific2 : 32|8@1+ (1,0) [0|0] "" Vector__XXX
 SG_ ManufacturerSpecific1 : 24|8@1+ (1,0) [0|0] "" Vector__XXX
 SG_ ErrorRegisterManufSpecific : 23|1@1+ (1,0) [0|0] "" Vector__XXX
 SG_ ErrorRegisterReserved : 22|1@1+ (1,0) [0|0] "" Vector__XXX
 SG_ ErrorRegisterProfileSpecific : 21|1@1+ (1,0) [0|0] "" Vector__XXX
 SG_ ErrorRegisterCommunication : 20|1@1+ (1,0) [0|0] "" Vector__XXX
 SG_ ErrorRegisterTemperature : 19|1@1+ (1,0) [0|0] "" Vector__XXX
 SG_ ErrorRegisterVoltage : 18|1@1+ (1,0) [0|0] "" Vector__XXX
 SG_ ErrorRegisterCurrent : 17|1@1+ (1,0) [0|0] "" Vector__XXX
 SG_ ErrorRegisterGeneric : 16|1@1+ (1,0) [0|0] "" Vector__XXX
 SG_ ErrorCode : 0|16@1+ (1,0) [0|0] "" Vector__XXX

BO_ 1801 HBGuard_009: 1 Vector__XXX
 SG_ Toggle : 7|1@1+ (1,0) [0|0] "" Vector__XXX
 SG_ State : 0|7@1+ (1,0) [0|0] "" Vector__XXX

BO_ 1417 SSDO_009: 8 Vector__XXX

BO_ 1545 CSDO_009: 8 Vector__XXX

BO_ 137 EMCY_009: 8 Vector__XXX
 SG_ ManufacturerSpecific5 : 56|8@1+ (1,0) [0|0] "" Vector__XXX
 SG_ ManufacturerSpecific4 : 48|8@1+ (1,0) [0|0] "" Vector__XXX
 SG_ ManufacturerSpecific3 : 40|8@1+ (1,0) [0|0] "" Vector__XXX
 SG_ ManufacturerSpecific2 : 32|8@1+ (1,0) [0|0] "" Vector__XXX
 SG_ ManufacturerSpecific1 : 24|8@1+ (1,0) [0|0] "" Vector__XXX
 SG_ ErrorRegisterManufSpecific : 23|1@1+ (1,0) [0|0] "" Vector__XXX
 SG_ ErrorRegisterReserved : 22|1@1+ (1,0) [0|0] "" Vector__XXX
 SG_ ErrorRegisterProfileSpecific : 21|1@1+ (1,0) [0|0] "" Vector__XXX
 SG_ ErrorRegisterCommunication : 20|1@1+ (1,0) [0|0] "" Vector__XXX
 SG_ ErrorRegisterTemperature : 19|1@1+ (1,0) [0|0] "" Vector__XXX
 SG_ ErrorRegisterVoltage : 18|1@1+ (1,0) [0|0] "" Vector__XXX
 SG_ ErrorRegisterCurrent : 17|1@1+ (1,0) [0|0] "" Vector__XXX
 SG_ ErrorRegisterGeneric : 16|1@1+ (1,0) [0|0] "" Vector__XXX
 SG_ ErrorCode : 0|16@1+ (1,0) [0|0] "" Vector__XXX

BO_ 1799 HBGuard_007: 1 Vector__XXX
 SG_ Toggle : 7|1@1+ (1,0) [0|0] "" Vector__XXX
 SG_ State : 0|7@1+ (1,0) [0|0] "" Vector__XXX

BO_ 1415 SSDO_007: 8 Vector__XXX

BO_ 1543 CSDO_007: 8 Vector__XXX

BO_ 135 EMCY_007: 8 Vector__XXX
 SG_ ManufacturerSpecific5 : 56|8@1+ (1,0) [0|0] "" Vector__XXX
 SG_ ManufacturerSpecific4 : 48|8@1+ (1,0) [0|0] "" Vector__XXX
 SG_ ManufacturerSpecific3 : 40|8@1+ (1,0) [0|0] "" Vector__XXX
 SG_ ManufacturerSpecific2 : 32|8@1+ (1,0) [0|0] "" Vector__XXX
 SG_ ManufacturerSpecific1 : 24|8@1+ (1,0) [0|0] "" Vector__XXX
 SG_ ErrorRegisterManufSpecific : 23|1@1+ (1,0) [0|0] "" Vector__XXX
 SG_ ErrorRegisterReserved : 22|1@1+ (1,0) [0|0] "" Vector__XXX
 SG_ ErrorRegisterProfileSpecific : 21|1@1+ (1,0) [0|0] "" Vector__XXX
 SG_ ErrorRegisterCommunication : 20|1@1+ (1,0) [0|0] "" Vector__XXX
 SG_ ErrorRegisterTemperature : 19|1@1+ (1,0) [0|0] "" Vector__XXX
 SG_ ErrorRegisterVoltage : 18|1@1+ (1,0) [0|0] "" Vector__XXX
 SG_ ErrorRegisterCurrent : 17|1@1+ (1,0) [0|0] "" Vector__XXX
 SG_ ErrorRegisterGeneric : 16|1@1+ (1,0) [0|0] "" Vector__XXX
 SG_ ErrorCode : 0|16@1+ (1,0) [0|0] "" Vector__XXX

BO_ 1798 HBGuard_006: 1 Vector__XXX
 SG_ Toggle : 7|1@1+ (1,0) [0|0] "" Vector__XXX
 SG_ State : 0|7@1+ (1,0) [0|0] "" Vector__XXX

BO_ 1414 SSDO_006: 8 Vector__XXX

BO_ 1542 CSDO_006: 8 Vector__XXX

BO_ 134 EMCY_006: 8 Vector__XXX
 SG_ ManufacturerSpecific5 : 56|8@1+ (1,0) [0|0] "" Vector__XXX
 SG_ ManufacturerSpecific4 : 48|8@1+ (1,0) [0|0] "" Vector__XXX
 SG_ ManufacturerSpecific3 : 40|8@1+ (1,0) [0|0] "" Vector__XXX
 SG_ ManufacturerSpecific2 : 32|8@1+ (1,0) [0|0] "" Vector__XXX
 SG_ ManufacturerSpecific1 : 24|8@1+ (1,0) [0|0] "" Vector__XXX
 SG_ ErrorRegisterManufSpecific : 23|1@1+ (1,0) [0|0] "" Vector__XXX
 SG_ ErrorRegisterReserved : 22|1@1+ (1,0) [0|0] "" Vector__XXX
 SG_ ErrorRegisterProfileSpecific : 21|1@1+ (1,0) [0|0] "" Vector__XXX
 SG_ ErrorRegisterCommunication : 20|1@1+ (1,0) [0|0] "" Vector__XXX
 SG_ ErrorRegisterTemperature : 19|1@1+ (1,0) [0|0] "" Vector__XXX
 SG_ ErrorRegisterVoltage : 18|1@1+ (1,0) [0|0] "" Vector__XXX
 SG_ ErrorRegisterCurrent : 17|1@1+ (1,0) [0|0] "" Vector__XXX
 SG_ ErrorRegisterGeneric : 16|1@1+ (1,0) [0|0] "" Vector__XXX
 SG_ ErrorCode : 0|16@1+ (1,0) [0|0] "" Vector__XXX

BO_ 1797 HBGuard_005: 1 Vector__XXX
 SG_ Toggle : 7|1@1+ (1,0) [0|0] "" Vector__XXX
 SG_ State : 0|7@1+ (1,0) [0|0] "" Vector__XXX

BO_ 1413 SSDO_005: 8 Vector__XXX

BO_ 1541 CSDO_005: 8 Vector__XXX

BO_ 133 EMCY_005: 8 Vector__XXX
 SG_ ManufacturerSpecific5 : 56|8@1+ (1,0) [0|0] "" Vector__XXX
 SG_ ManufacturerSpecific4 : 48|8@1+ (1,0) [0|0] "" Vector__XXX
 SG_ ManufacturerSpecific3 : 40|8@1+ (1,0) [0|0] "" Vector__XXX
 SG_ ManufacturerSpecific2 : 32|8@1+ (1,0) [0|0] "" Vector__XXX
 SG_ ManufacturerSpecific1 : 24|8@1+ (1,0) [0|0] "" Vector__XXX
 SG_ ErrorRegisterManufSpecific : 23|1@1+ (1,0) [0|0] "" Vector__XXX
 SG_ ErrorRegisterReserved : 22|1@1+ (1,0) [0|0] "" Vector__XXX
 SG_ ErrorRegisterProfileSpecific : 21|1@1+ (1,0) [0|0] "" Vector__XXX
 SG_ ErrorRegisterCommunication : 20|1@1+ (1,0) [0|0] "" Vector__XXX
 SG_ ErrorRegisterTemperature : 19|1@1+ (1,0) [0|0] "" Vector__XXX
 SG_ ErrorRegisterVoltage : 18|1@1+ (1,0) [0|0] "" Vector__XXX
 SG_ ErrorRegisterCurrent : 17|1@1+ (1,0) [0|0] "" Vector__XXX
 SG_ ErrorRegisterGeneric : 16|1@1+ (1,0) [0|0] "" Vector__XXX
 SG_ ErrorCode : 0|16@1+ (1,0) [0|0] "" Vector__XXX

BO_ 1796 HBGuard_004: 1 Vector__XXX
 SG_ Toggle : 7|1@1+ (1,0) [0|0] "" Vector__XXX
 SG_ State : 0|7@1+ (1,0) [0|0] "" Vector__XXX

BO_ 1412 SSDO_004: 8 Vector__XXX

BO_ 1540 CSDO_004: 8 Vector__XXX

BO_ 132 EMCY_004: 8 Vector__XXX
 SG_ ManufacturerSpecific5 : 56|8@1+ (1,0) [0|0] "" Vector__XXX
 SG_ ManufacturerSpecific4 : 48|8@1+ (1,0) [0|0] "" Vector__XXX
 SG_ ManufacturerSpecific3 : 40|8@1+ (1,0) [0|0] "" Vector__XXX
 SG_ ManufacturerSpecific2 : 32|8@1+ (1,0) [0|0] "" Vector__XXX
 SG_ ManufacturerSpecific1 : 24|8@1+ (1,0) [0|0] "" Vector__XXX
 SG_ ErrorRegisterManufSpecific : 23|1@1+ (1,0) [0|0] "" Vector__XXX
 SG_ ErrorRegisterReserved : 22|1@1+ (1,0) [0|0] "" Vector__XXX
 SG_ ErrorRegisterProfileSpecific : 21|1@1+ (1,0) [0|0] "" Vector__XXX
 SG_ ErrorRegisterCommunication : 20|1@1+ (1,0) [0|0] "" Vector__XXX
 SG_ ErrorRegisterTemperature : 19|1@1+ (1,0) [0|0] "" Vector__XXX
 SG_ ErrorRegisterVoltage : 18|1@1+ (1,0) [0|0] "" Vector__XXX
 SG_ ErrorRegisterCurrent : 17|1@1+ (1,0) [0|0] "" Vector__XXX
 SG_ ErrorRegisterGeneric : 16|1@1+ (1,0) [0|0] "" Vector__XXX
 SG_ ErrorCode : 0|16@1+ (1,0) [0|0] "" Vector__XXX

BO_ 1795 HBGuard_003: 1 Vector__XXX
 SG_ Toggle : 7|1@1+ (1,0) [0|0] "" Vector__XXX
 SG_ State : 0|7@1+ (1,0) [0|0] "" Vector__XXX

BO_ 1411 SSDO_003: 8 Vector__XXX

BO_ 1539 CSDO_003: 8 Vector__XXX

BO_ 131 EMCY_003: 8 Vector__XXX
 SG_ ManufacturerSpecific5 : 56|8@1+ (1,0) [0|0] "" Vector__XXX
 SG_ ManufacturerSpecific4 : 48|8@1+ (1,0) [0|0] "" Vector__XXX
 SG_ ManufacturerSpecific3 : 40|8@1+ (1,0) [0|0] "" Vector__XXX
 SG_ ManufacturerSpecific2 : 32|8@1+ (1,0) [0|0] "" Vector__XXX
 SG_ ManufacturerSpecific1 : 24|8@1+ (1,0) [0|0] "" Vector__XXX
 SG_ ErrorRegisterManufSpecific : 23|1@1+ (1,0) [0|0] "" Vector__XXX
 SG_ ErrorRegisterReserved : 22|1@1+ (1,0) [0|0] "" Vector__XXX
 SG_ ErrorRegisterProfileSpecific : 21|1@1+ (1,0) [0|0] "" Vector__XXX
 SG_ ErrorRegisterCommunication : 20|1@1+ (1,0) [0|0] "" Vector__XXX
 SG_ ErrorRegisterTemperature : 19|1@1+ (1,0) [0|0] "" Vector__XXX
 SG_ ErrorRegisterVoltage : 18|1@1+ (1,0) [0|0] "" Vector__XXX
 SG_ ErrorRegisterCurrent : 17|1@1+ (1,0) [0|0] "" Vector__XXX
 SG_ ErrorRegisterGeneric : 16|1@1+ (1,0) [0|0] "" Vector__XXX
 SG_ ErrorCode : 0|16@1+ (1,0) [0|0] "" Vector__XXX

BO_ 1794 HBGuard_002: 1 Vector__XXX
 SG_ Toggle : 7|1@1+ (1,0) [0|0] "" Vector__XXX
 SG_ State : 0|7@1+ (1,0) [0|0] "" Vector__XXX

BO_ 1410 SSDO_002: 8 Vector__XXX

BO_ 1538 CSDO_002: 8 Vector__XXX

BO_ 130 EMCY_002: 8 Vector__XXX
 SG_ ManufacturerSpecific5 : 56|8@1+ (1,0) [0|0] "" Vector__XXX
 SG_ ManufacturerSpecific4 : 48|8@1+ (1,0) [0|0] "" Vector__XXX
 SG_ ManufacturerSpecific3 : 40|8@1+ (1,0) [0|0] "" Vector__XXX
 SG_ ManufacturerSpecific2 : 32|8@1+ (1,0) [0|0] "" Vector__XXX
 SG_ ManufacturerSpecific1 : 24|8@1+ (1,0) [0|0] "" Vector__XXX
 SG_ ErrorRegisterManufSpecific : 23|1@1+ (1,0) [0|0] "" Vector__XXX
 SG_ ErrorRegisterReserved : 22|1@1+ (1,0) [0|0] "" Vector__XXX
 SG_ ErrorRegisterProfileSpecific : 21|1@1+ (1,0) [0|0] "" Vector__XXX
 SG_ ErrorRegisterCommunication : 20|1@1+ (1,0) [0|0] "" Vector__XXX
 SG_ ErrorRegisterTemperature : 19|1@1+ (1,0) [0|0] "" Vector__XXX
 SG_ ErrorRegisterVoltage : 18|1@1+ (1,0) [0|0] "" Vector__XXX
 SG_ ErrorRegisterCurrent : 17|1@1+ (1,0) [0|0] "" Vector__XXX
 SG_ ErrorRegisterGeneric : 16|1@1+ (1,0) [0|0] "" Vector__XXX
 SG_ ErrorCode : 0|16@1+ (1,0) [0|0] "" Vector__XXX

BO_ 127 RED_IndicateActiveCANLine: 0 Vector__XXX

BO_ 118 FM_ForceReset: 0 Vector__XXX

BO_ 117 FM_ReqMasterCapable: 0 Vector__XXX

BO_ 116 FM_RspMasterCapable: 0 Vector__XXX

BO_ 115 FM_ReqPrioLevel: 0 Vector__XXX

BO_ 114 FM_TriggerTimeSlot: 0 Vector__XXX

BO_ 113 FM_MasterPrioLevel: 2 Vector__XXX
 SG_ FM_NodeID : 8|8@1+ (1,0) [0|0] "" Vector__XXX
 SG_ FM_PrioLevel : 0|8@1+ (1,0) [0|0] "" Vector__XXX

BO_ 256 TIME: 6 Vector__XXX
 SG_ days : 32|16@1+ (1,0) [0|65535] "days" Vector__XXX
 SG_ ms : 0|28@1+ (1,0) [0|86399999] "ms" Vector__XXX

BO_ 128 SYNC: 0 Vector__XXX

BO_ 0 NMTZeroMsg: 2 VirtualNMTMaster
 SG_ Node_ID : 8|8@1+ (1,0) [0|0] "" Vector__XXX
 SG_ CS : 0|8@1+ (1,0) [0|0] "" Vector__XXX

BO_ 1760 DynSDOReq: 0 Vector__XXX

BO_ 2021 LSS_M: 8 Vector__XXX
 SG_ LSS_ID_Number m81 : 8|32@1+ (1,0) [0|0] "" Vector__XXX
 SG_ LSS_BitCheck m81 : 40|8@1+ (1,0) [0|0] "" Vector__XXX
 SG_ LSS_Sub m81 : 48|8@1+ (1,0) [0|0] "" Vector__XXX
 SG_ LSS_Next m81 : 56|8@1+ (1,0) [0|0] "" Vector__XXX
 SG_ LSS_SwitchDelay m21 : 8|16@1+ (1,0) [0|0] "" Vector__XXX
 SG_ LSS_CfgNodeID m17 : 8|8@1+ (1,0) [0|0] "" Vector__XXX
 SG_ LSS_IdentSerialHigh m75 : 8|32@1+ (1,0) [0|0] "" Vector__XXX
 SG_ LSS_IdentSerialLow m74 : 8|32@1+ (1,0) [0|0] "" Vector__XXX
 SG_ LSS_IdentRevisionHigh m73 : 8|32@1+ (1,0) [0|0] "" Vector__XXX
 SG_ LSS_IdentRevisionLow m72 : 8|32@1+ (1,0) [0|0] "" Vector__XXX
 SG_ LSS_IdentProductCode m71 : 8|32@1+ (1,0) [0|0] "" Vector__XXX
 SG_ LSS_IdentVendorId m70 : 8|32@1+ (1,0) [0|0] "" Vector__XXX
 SG_ LSS_TableIndex m19 : 16|8@1+ (1,0) [0|0] "" Vector__XXX
 SG_ LSS_TableSelector m19 : 8|8@1+ (1,0) [0|0] "" Vector__XXX
 SG_ LSS_SwitchSerial m67 : 8|32@1+ (1,0) [0|0] "" Vector__XXX
 SG_ LSS_SwitchRevision m66 : 8|32@1+ (1,0) [0|0] "" Vector__XXX
 SG_ LSS_SwitchProductCode m65 : 8|32@1+ (1,0) [0|0] "" Vector__XXX
 SG_ LSS_SwitchVendorId m64 : 8|32@1+ (1,0) [0|0] "" Vector__XXX
 SG_ LSS_Mode m4 : 8|8@1+ (1,0) [0|0] "" Vector__XXX
 SG_ LSS_M_CS M : 0|8@1+ (1,0) [0|0] "" Vector__XXX

BO_ 2020 LSS_S: 8 Vector__XXX
 SG_ LSS_NodeId m94 : 8|8@1+ (1,0) [0|0] "" Vector__XXX
 SG_ LSS_Serial m93 : 8|32@1+ (1,0) [0|0] "" Vector__XXX
 SG_ LSS_Revision m92 : 8|32@1+ (1,0) [0|0] "" Vector__XXX
 SG_ LSS_ProductId m91 : 8|32@1+ (1,0) [0|0] "" Vector__XXX
 SG_ LSS_VendorId m90 : 8|32@1+ (1,0) [0|0] "" Vector__XXX
 SG_ LSS_StoreCfg_SpecErr m23 : 16|8@1+ (1,0) [0|0] "" Vector__XXX
 SG_ LSS_StoreCfg_ErrCode m23 : 8|8@1+ (1,0) [0|0] "" Vector__XXX
 SG_ LSS_CfgBitTim_SpecErr m19 : 16|8@1+ (1,0) [0|0] "" Vector__XXX
 SG_ LSS_CfgBitTim_ErrCode m19 : 8|8@1+ (1,0) [0|0] "" Vector__XXX
 SG_ LSS_CfgNodeID_SpecErr m17 : 16|8@1+ (1,0) [0|0] "" Vector__XXX
 SG_ LSS_CfgNodeID_ErrCode m17 : 8|8@1+ (1,0) [0|0] "" Vector__XXX
 SG_ LSS_S_CS M : 0|8@1+ (1,0) [0|0] "" Vector__XXX

BO_ 1 GFC: 0 Vector__XXX

BO_ 1173 N21_TPDO3: 5 BMS_Battery_1
 SG_ SIG2 : 32|8@1+ (1,0) [0|0] "" Vector__XXX
 SG_ SIG1 : 16|16@1+ (1,0) [0|0] "" Vector__XXX
 SG_ SIG0 : 0|16@1+ (1,0) [0|0] "" Vector__XXX

BO_ 917 N21_TPDO2: 1 BMS_Battery_1
 SG_ SIG0 : 0|8@1+ (1,0) [0|0] "" Vector__XXX

BO_ 661 N21_TPDO1: 8 BMS_Battery_1
 SG_ BMS_Discharge_Actual_Allowed : 56|8@1+ (1,0) [0|0] "" Vector__XXX
 SG_ BMS_Recap_Actual_Allowed : 48|8@1+ (1,0) [0|0] "" Vector__XXX
 SG_ BMS_State : 40|8@1+ (1,0) [0|0] "" Vector__XXX
 SG_ BMS_SOC : 32|8@1+ (1,0) [0|0] "" Vector__XXX
 SG_ BMS_Battery_Pack_Max_Temp : 24|8@1- (1,0) [0|0] "" Vector__XXX
 SG_ BMS_Battery_Pack_Min_Temp : 16|8@1- (1,0) [0|0] "" Vector__XXX
 SG_ BMS_Current : 0|16@1- (1,0) [0|0] "" Vector__XXX

BO_ 405 N21_TPDO0: 8 BMS_Battery_1
 SG_ BMS_Max_Cell_Voltage_ID : 56|8@1+ (1,0) [0|0] "" Vector__XXX
 SG_ BMS_Max_Cell_Voltage : 40|16@1- (1,0) [0|0] "" Vector__XXX
 SG_ BMS_Min_Cell_Voltage_ID : 32|8@1+ (1,0) [0|0] "" Vector__XXX
 SG_ BMS_Min_Cell_Voltage : 16|16@1- (1,0) [0|0] "" Vector__XXX
 SG_ BMS_Battery_Voltage : 0|16@1- (1,0) [0|0] "" Vector__XXX

BO_ 650 N10_TPDO1: 6 PVC
 SG_ Baseplate_temperature : 32|16@1+ (1,0) [0|0] "" Vector__XXX
 SG_ Output_voltage : 16|16@1+ (1,0) [0|0] "" Vector__XXX
 SG_ Input_voltage : 0|16@1+ (1,0) [0|0] "" Vector__XXX

BO_ 394 N10_TPDO0: 3 PVC
 SG_ Statusword : 16|8@1+ (1,0) [0|0] "" Vector__XXX
 SG_ I_O_status : 0|16@1+ (1,0) [0|0] "" Vector__XXX

BO_ 1160 N8_TPDO3: 8 TMS
 SG_ Voltage_Sensor_4 : 32|32@1+ (1,0) [0|494967295] "" Vector__XXX
 SG_ Voltage_Sensor_3 : 0|32@1+ (1,0) [0|494967295] "" Vector__XXX

BO_ 648 N8_TPDO1: 8 TMS
 SG_ Temp_4 : 32|32@1+ (1,0) [0|494967295] "" Vector__XXX
 SG_ Temp_3 : 0|32@1+ (1,0) [0|494967295] "" Vector__XXX

BO_ 392 N8_TPDO0: 8 TMS
 SG_ Temp_2 : 32|32@1+ (1,0) [0|494967295] "" Vector__XXX
 SG_ Temp_1 : 0|32@1+ (1,0) [0|494967295] "" Vector__XXX

BA_DEF_ BU_  "CO_DCF" STRING ;
BA_DEF_ BU_  "CO_ID" INT 0 127;
BA_DEF_ BU_  "CO_NVSEGMENT0" STRING ;
BA_DEF_ BU_  "CO_NVSEGMENT1" STRING ;
BA_DEF_ BU_  "CO_NVSEGMENT2" STRING ;
BA_DEF_ BU_  "CO_NVSEGMENT3" STRING ;
BA_DEF_ BU_  "CO_NVSEGMENT4" STRING ;
BA_DEF_ BU_  "CO_NVSEGMENT5" STRING ;
BA_DEF_ BU_  "CO_NVSEGMENT6" STRING ;
BA_DEF_ BU_  "CO_NVSEGMENT7" STRING ;
BA_DEF_ BU_  "CO_NVSEGMENT8" STRING ;
BA_DEF_ BU_  "CO_NVSEGMENT9" STRING ;
BA_DEF_ BU_  "CO_NVSEGMENT10" STRING ;
BA_DEF_ BU_  "CO_NVSEGMENT11" STRING ;
BA_DEF_ BU_  "CO_NVSEGMENT12" STRING ;
BA_DEF_ BU_  "CO_NVSEGMENT13" STRING ;
BA_DEF_ BU_  "CO_NVSEGMENT14" STRING ;
BA_DEF_ BU_  "CO_NVSEGMENT15" STRING ;
BA_DEF_ BU_  "CO_NVSEGMENT16" STRING ;
BA_DEF_ BU_  "CO_NVSEGMENT17" STRING ;
BA_DEF_ BU_  "CO_NVSEGMENT18" STRING ;
BA_DEF_ BU_  "CO_NVSEGMENT19" STRING ;
BA_DEF_ BU_  "CO_NVSEGMENT20" STRING ;
BA_DEF_ BU_  "CO_NVSEGMENT21" STRING ;
BA_DEF_ BU_  "CO_NVSEGMENT22" STRING ;
BA_DEF_ BU_  "CO_NVSEGMENT23" STRING ;
BA_DEF_ BU_  "CO_NVSEGMENT24" STRING ;
BA_DEF_ BU_  "CO_NVSEGMENT25" STRING ;
BA_DEF_ BU_  "CO_NVSEGMENT26" STRING ;
BA_DEF_ BU_  "CO_NVSEGMENT27" STRING ;
BA_DEF_ BU_  "CO_NVSEGMENT28" STRING ;
BA_DEF_ BU_  "CO_NVSEGMENT29" STRING ;
BA_DEF_ BU_  "CO_NVSEGMENT30" STRING ;
BA_DEF_ BU_  "CO_NVSEGMENT31" STRING ;
BA_DEF_ BU_  "CO_NVSEGMENT32" STRING ;
BA_DEF_ BU_  "CO_NVSEGMENT33" STRING ;
BA_DEF_ BU_  "CO_NVSEGMENT34" STRING ;
BA_DEF_ BU_  "CO_NVSEGMENT35" STRING ;
BA_DEF_ BU_  "CO_NVSEGMENT36" STRING ;
BA_DEF_ BU_  "CO_NVSEGMENT37" STRING ;
BA_DEF_ BU_  "CO_NVSEGMENT38" STRING ;
BA_DEF_ BU_  "CO_NVSEGMENT39" STRING ;
BA_DEF_ BU_  "CO_NVSEGMENT40" STRING ;
BA_DEF_ BU_  "CO_NVSEGMENT41" STRING ;
BA_DEF_ BU_  "CO_NVSEGMENT42" STRING ;
BA_DEF_ BU_  "CO_NVSEGMENT43" STRING ;
BA_DEF_ BU_  "CO_NVSEGMENT44" STRING ;
BA_DEF_ BU_  "CO_NVSEGMENT45" STRING ;
BA_DEF_  "OptionLoadDCF" INT 0 1;
BA_DEF_ SG_  "GenSigStartValue" INT 0 0;
BA_DEF_ BO_  "CO_MsgCategory" INT 0 0;
BA_DEF_  "CO_MsgColourSupported" INT 0 1;
BA_DEF_  "GeneratedBy" STRING ;
BA_DEF_  "CANopenApplProfile" INT 0 0;
BA_DEF_  "ProtocolType" STRING ;
BA_DEF_  "AUTOGENERATION" INT 0 1;
BA_DEF_DEF_  "CO_DCF" "";
BA_DEF_DEF_  "CO_ID" 0;
BA_DEF_DEF_  "CO_NVSEGMENT0" "";
BA_DEF_DEF_  "CO_NVSEGMENT1" "";
BA_DEF_DEF_  "CO_NVSEGMENT2" "";
BA_DEF_DEF_  "CO_NVSEGMENT3" "";
BA_DEF_DEF_  "CO_NVSEGMENT4" "";
BA_DEF_DEF_  "CO_NVSEGMENT5" "";
BA_DEF_DEF_  "CO_NVSEGMENT6" "";
BA_DEF_DEF_  "CO_NVSEGMENT7" "";
BA_DEF_DEF_  "CO_NVSEGMENT8" "";
BA_DEF_DEF_  "CO_NVSEGMENT9" "";
BA_DEF_DEF_  "CO_NVSEGMENT10" "";
BA_DEF_DEF_  "CO_NVSEGMENT11" "";
BA_DEF_DEF_  "CO_NVSEGMENT12" "";
BA_DEF_DEF_  "CO_NVSEGMENT13" "";
BA_DEF_DEF_  "CO_NVSEGMENT14" "";
BA_DEF_DEF_  "CO_NVSEGMENT15" "";
BA_DEF_DEF_  "CO_NVSEGMENT16" "";
BA_DEF_DEF_  "CO_NVSEGMENT17" "";
BA_DEF_DEF_  "CO_NVSEGMENT18" "";
BA_DEF_DEF_  "CO_NVSEGMENT19" "";
BA_DEF_DEF_  "CO_NVSEGMENT20" "";
BA_DEF_DEF_  "CO_NVSEGMENT21" "";
BA_DEF_DEF_  "CO_NVSEGMENT22" "";
BA_DEF_DEF_  "CO_NVSEGMENT23" "";
BA_DEF_DEF_  "CO_NVSEGMENT24" "";
BA_DEF_DEF_  "CO_NVSEGMENT25" "";
BA_DEF_DEF_  "CO_NVSEGMENT26" "";
BA_DEF_DEF_  "CO_NVSEGMENT27" "";
BA_DEF_DEF_  "CO_NVSEGMENT28" "";
BA_DEF_DEF_  "CO_NVSEGMENT29" "";
BA_DEF_DEF_  "CO_NVSEGMENT30" "";
BA_DEF_DEF_  "CO_NVSEGMENT31" "";
BA_DEF_DEF_  "CO_NVSEGMENT32" "";
BA_DEF_DEF_  "CO_NVSEGMENT33" "";
BA_DEF_DEF_  "CO_NVSEGMENT34" "";
BA_DEF_DEF_  "CO_NVSEGMENT35" "";
BA_DEF_DEF_  "CO_NVSEGMENT36" "";
BA_DEF_DEF_  "CO_NVSEGMENT37" "";
BA_DEF_DEF_  "CO_NVSEGMENT38" "";
BA_DEF_DEF_  "CO_NVSEGMENT39" "";
BA_DEF_DEF_  "CO_NVSEGMENT40" "";
BA_DEF_DEF_  "CO_NVSEGMENT41" "";
BA_DEF_DEF_  "CO_NVSEGMENT42" "";
BA_DEF_DEF_  "CO_NVSEGMENT43" "";
BA_DEF_DEF_  "CO_NVSEGMENT44" "";
BA_DEF_DEF_  "CO_NVSEGMENT45" "";
BA_DEF_DEF_  "OptionLoadDCF" 0;
BA_DEF_DEF_  "GenSigStartValue" 0;
BA_DEF_DEF_  "CO_MsgCategory" 0;
BA_DEF_DEF_  "CO_MsgColourSupported" 1;
BA_DEF_DEF_  "GeneratedBy" "";
BA_DEF_DEF_  "CANopenApplProfile" 301;
BA_DEF_DEF_  "ProtocolType" "CANopen";
BA_DEF_DEF_  "AUTOGENERATION" 0;
BA_ "GeneratedBy" "Vector ProCANopen";
BA_ "AUTOGENERATION" 1;
BA_ "CO_ID" BU_ PVC 10;
BA_ "CO_DCF" BU_ PVC "..\D010.DCF";
BA_ "CO_ID" BU_ BMS_Battery_1 21;
BA_ "CO_DCF" BU_ BMS_Battery_1 "..\D021.DCF";
BA_ "CO_DCF" BU_ TMS "..\D008.DCF";
BA_ "CO_ID" BU_ TMS 8;
BA_ "CO_DCF" BU_ Inverter "..\eds_node_1.DCF";
BA_ "CO_ID" BU_ Inverter 1;
BA_ "CO_MsgCategory" BO_ 1813 505;
BA_ "CO_MsgCategory" BO_ 1429 410;
BA_ "CO_MsgCategory" BO_ 1557 405;
BA_ "CO_MsgCategory" BO_ 149 205;
BA_ "CO_MsgCategory" BO_ 1802 505;
BA_ "CO_MsgCategory" BO_ 1418 410;
BA_ "CO_MsgCategory" BO_ 1546 405;
BA_ "CO_MsgCategory" BO_ 138 205;
BA_ "CO_MsgCategory" BO_ 1800 505;
BA_ "CO_MsgCategory" BO_ 1416 410;
BA_ "CO_MsgCategory" BO_ 1544 405;
BA_ "CO_MsgCategory" BO_ 136 205;
BA_ "CO_MsgCategory" BO_ 1793 505;
BA_ "CO_MsgCategory" BO_ 1409 410;
BA_ "CO_MsgCategory" BO_ 1537 405;
BA_ "CO_MsgCategory" BO_ 129 205;
BA_ "CO_MsgCategory" BO_ 1919 505;
BA_ "CO_MsgCategory" BO_ 1535 410;
BA_ "CO_MsgCategory" BO_ 1663 405;
BA_ "CO_MsgCategory" BO_ 255 205;
BA_ "CO_MsgCategory" BO_ 1918 505;
BA_ "CO_MsgCategory" BO_ 1534 410;
BA_ "CO_MsgCategory" BO_ 1662 405;
BA_ "CO_MsgCategory" BO_ 254 205;
BA_ "CO_MsgCategory" BO_ 1917 505;
BA_ "CO_MsgCategory" BO_ 1533 410;
BA_ "CO_MsgCategory" BO_ 1661 405;
BA_ "CO_MsgCategory" BO_ 253 205;
BA_ "CO_MsgCategory" BO_ 1916 505;
BA_ "CO_MsgCategory" BO_ 1532 410;
BA_ "CO_MsgCategory" BO_ 1660 405;
BA_ "CO_MsgCategory" BO_ 252 205;
BA_ "CO_MsgCategory" BO_ 1915 505;
BA_ "CO_MsgCategory" BO_ 1531 410;
BA_ "CO_MsgCategory" BO_ 1659 405;
BA_ "CO_MsgCategory" BO_ 251 205;
BA_ "CO_MsgCategory" BO_ 1914 505;
BA_ "CO_MsgCategory" BO_ 1530 410;
BA_ "CO_MsgCategory" BO_ 1658 405;
BA_ "CO_MsgCategory" BO_ 250 205;
BA_ "CO_MsgCategory" BO_ 1913 505;
BA_ "CO_MsgCategory" BO_ 1529 410;
BA_ "CO_MsgCategory" BO_ 1657 405;
BA_ "CO_MsgCategory" BO_ 249 205;
BA_ "CO_MsgCategory" BO_ 1912 505;
BA_ "CO_MsgCategory" BO_ 1528 410;
BA_ "CO_MsgCategory" BO_ 1656 405;
BA_ "CO_MsgCategory" BO_ 248 205;
BA_ "CO_MsgCategory" BO_ 1911 505;
BA_ "CO_MsgCategory" BO_ 1527 410;
BA_ "CO_MsgCategory" BO_ 1655 405;
BA_ "CO_MsgCategory" BO_ 247 205;
BA_ "CO_MsgCategory" BO_ 1910 505;
BA_ "CO_MsgCategory" BO_ 1526 410;
BA_ "CO_MsgCategory" BO_ 1654 405;
BA_ "CO_MsgCategory" BO_ 246 205;
BA_ "CO_MsgCategory" BO_ 1909 505;
BA_ "CO_MsgCategory" BO_ 1525 410;
BA_ "CO_MsgCategory" BO_ 1653 405;
BA_ "CO_MsgCategory" BO_ 245 205;
BA_ "CO_MsgCategory" BO_ 1908 505;
BA_ "CO_MsgCategory" BO_ 1524 410;
BA_ "CO_MsgCategory" BO_ 1652 405;
BA_ "CO_MsgCategory" BO_ 244 205;
BA_ "CO_MsgCategory" BO_ 1907 505;
BA_ "CO_MsgCategory" BO_ 1523 410;
BA_ "CO_MsgCategory" BO_ 1651 405;
BA_ "CO_MsgCategory" BO_ 243 205;
BA_ "CO_MsgCategory" BO_ 1906 505;
BA_ "CO_MsgCategory" BO_ 1522 410;
BA_ "CO_MsgCategory" BO_ 1650 405;
BA_ "CO_MsgCategory" BO_ 242 205;
BA_ "CO_MsgCategory" BO_ 1905 505;
BA_ "CO_MsgCategory" BO_ 1521 410;
BA_ "CO_MsgCategory" BO_ 1649 405;
BA_ "CO_MsgCategory" BO_ 241 205;
BA_ "CO_MsgCategory" BO_ 1904 505;
BA_ "CO_MsgCategory" BO_ 1520 410;
BA_ "CO_MsgCategory" BO_ 1648 405;
BA_ "CO_MsgCategory" BO_ 240 205;
BA_ "CO_MsgCategory" BO_ 1903 505;
BA_ "CO_MsgCategory" BO_ 1519 410;
BA_ "CO_MsgCategory" BO_ 1647 405;
BA_ "CO_MsgCategory" BO_ 239 205;
BA_ "CO_MsgCategory" BO_ 1902 505;
BA_ "CO_MsgCategory" BO_ 1518 410;
BA_ "CO_MsgCategory" BO_ 1646 405;
BA_ "CO_MsgCategory" BO_ 238 205;
BA_ "CO_MsgCategory" BO_ 1901 505;
BA_ "CO_MsgCategory" BO_ 1517 410;
BA_ "CO_MsgCategory" BO_ 1645 405;
BA_ "CO_MsgCategory" BO_ 237 205;
BA_ "CO_MsgCategory" BO_ 1900 505;
BA_ "CO_MsgCategory" BO_ 1516 410;
BA_ "CO_MsgCategory" BO_ 1644 405;
BA_ "CO_MsgCategory" BO_ 236 205;
BA_ "CO_MsgCategory" BO_ 1899 505;
BA_ "CO_MsgCategory" BO_ 1515 410;
BA_ "CO_MsgCategory" BO_ 1643 405;
BA_ "CO_MsgCategory" BO_ 235 205;
BA_ "CO_MsgCategory" BO_ 1898 505;
BA_ "CO_MsgCategory" BO_ 1514 410;
BA_ "CO_MsgCategory" BO_ 1642 405;
BA_ "CO_MsgCategory" BO_ 234 205;
BA_ "CO_MsgCategory" BO_ 1897 505;
BA_ "CO_MsgCategory" BO_ 1513 410;
BA_ "CO_MsgCategory" BO_ 1641 405;
BA_ "CO_MsgCategory" BO_ 233 205;
BA_ "CO_MsgCategory" BO_ 1896 505;
BA_ "CO_MsgCategory" BO_ 1512 410;
BA_ "CO_MsgCategory" BO_ 1640 405;
BA_ "CO_MsgCategory" BO_ 232 205;
BA_ "CO_MsgCategory" BO_ 1895 505;
BA_ "CO_MsgCategory" BO_ 1511 410;
BA_ "CO_MsgCategory" BO_ 1639 405;
BA_ "CO_MsgCategory" BO_ 231 205;
BA_ "CO_MsgCategory" BO_ 1894 505;
BA_ "CO_MsgCategory" BO_ 1510 410;
BA_ "CO_MsgCategory" BO_ 1638 405;
BA_ "CO_MsgCategory" BO_ 230 205;
BA_ "CO_MsgCategory" BO_ 1893 505;
BA_ "CO_MsgCategory" BO_ 1509 410;
BA_ "CO_MsgCategory" BO_ 1637 405;
BA_ "CO_MsgCategory" BO_ 229 205;
BA_ "CO_MsgCategory" BO_ 1892 505;
BA_ "CO_MsgCategory" BO_ 1508 410;
BA_ "CO_MsgCategory" BO_ 1636 405;
BA_ "CO_MsgCategory" BO_ 228 205;
BA_ "CO_MsgCategory" BO_ 1891 505;
BA_ "CO_MsgCategory" BO_ 1507 410;
BA_ "CO_MsgCategory" BO_ 1635 405;
BA_ "CO_MsgCategory" BO_ 227 205;
BA_ "CO_MsgCategory" BO_ 1890 505;
BA_ "CO_MsgCategory" BO_ 1506 410;
BA_ "CO_MsgCategory" BO_ 1634 405;
BA_ "CO_MsgCategory" BO_ 226 205;
BA_ "CO_MsgCategory" BO_ 1889 505;
BA_ "CO_MsgCategory" BO_ 1505 410;
BA_ "CO_MsgCategory" BO_ 1633 405;
BA_ "CO_MsgCategory" BO_ 225 205;
BA_ "CO_MsgCategory" BO_ 1888 505;
BA_ "CO_MsgCategory" BO_ 1504 410;
BA_ "CO_MsgCategory" BO_ 1632 405;
BA_ "CO_MsgCategory" BO_ 224 205;
BA_ "CO_MsgCategory" BO_ 1887 505;
BA_ "CO_MsgCategory" BO_ 1503 410;
BA_ "CO_MsgCategory" BO_ 1631 405;
BA_ "CO_MsgCategory" BO_ 223 205;
BA_ "CO_MsgCategory" BO_ 1886 505;
BA_ "CO_MsgCategory" BO_ 1502 410;
BA_ "CO_MsgCategory" BO_ 1630 405;
BA_ "CO_MsgCategory" BO_ 222 205;
BA_ "CO_MsgCategory" BO_ 1885 505;
BA_ "CO_MsgCategory" BO_ 1501 410;
BA_ "CO_MsgCategory" BO_ 1629 405;
BA_ "CO_MsgCategory" BO_ 221 205;
BA_ "CO_MsgCategory" BO_ 1884 505;
BA_ "CO_MsgCategory" BO_ 1500 410;
BA_ "CO_MsgCategory" BO_ 1628 405;
BA_ "CO_MsgCategory" BO_ 220 205;
BA_ "CO_MsgCategory" BO_ 1883 505;
BA_ "CO_MsgCategory" BO_ 1499 410;
BA_ "CO_MsgCategory" BO_ 1627 405;
BA_ "CO_MsgCategory" BO_ 219 205;
BA_ "CO_MsgCategory" BO_ 1882 505;
BA_ "CO_MsgCategory" BO_ 1498 410;
BA_ "CO_MsgCategory" BO_ 1626 405;
BA_ "CO_MsgCategory" BO_ 218 205;
BA_ "CO_MsgCategory" BO_ 1881 505;
BA_ "CO_MsgCategory" BO_ 1497 410;
BA_ "CO_MsgCategory" BO_ 1625 405;
BA_ "CO_MsgCategory" BO_ 217 205;
BA_ "CO_MsgCategory" BO_ 1880 505;
BA_ "CO_MsgCategory" BO_ 1496 410;
BA_ "CO_MsgCategory" BO_ 1624 405;
BA_ "CO_MsgCategory" BO_ 216 205;
BA_ "CO_MsgCategory" BO_ 1879 505;
BA_ "CO_MsgCategory" BO_ 1495 410;
BA_ "CO_MsgCategory" BO_ 1623 405;
BA_ "CO_MsgCategory" BO_ 215 205;
BA_ "CO_MsgCategory" BO_ 1878 505;
BA_ "CO_MsgCategory" BO_ 1494 410;
BA_ "CO_MsgCategory" BO_ 1622 405;
BA_ "CO_MsgCategory" BO_ 214 205;
BA_ "CO_MsgCategory" BO_ 1877 505;
BA_ "CO_MsgCategory" BO_ 1493 410;
BA_ "CO_MsgCategory" BO_ 1621 405;
BA_ "CO_MsgCategory" BO_ 213 205;
BA_ "CO_MsgCategory" BO_ 1876 505;
BA_ "CO_MsgCategory" BO_ 1492 410;
BA_ "CO_MsgCategory" BO_ 1620 405;
BA_ "CO_MsgCategory" BO_ 212 205;
BA_ "CO_MsgCategory" BO_ 1875 505;
BA_ "CO_MsgCategory" BO_ 1491 410;
BA_ "CO_MsgCategory" BO_ 1619 405;
BA_ "CO_MsgCategory" BO_ 211 205;
BA_ "CO_MsgCategory" BO_ 1874 505;
BA_ "CO_MsgCategory" BO_ 1490 410;
BA_ "CO_MsgCategory" BO_ 1618 405;
BA_ "CO_MsgCategory" BO_ 210 205;
BA_ "CO_MsgCategory" BO_ 1873 505;
BA_ "CO_MsgCategory" BO_ 1489 410;
BA_ "CO_MsgCategory" BO_ 1617 405;
BA_ "CO_MsgCategory" BO_ 209 205;
BA_ "CO_MsgCategory" BO_ 1872 505;
BA_ "CO_MsgCategory" BO_ 1488 410;
BA_ "CO_MsgCategory" BO_ 1616 405;
BA_ "CO_MsgCategory" BO_ 208 205;
BA_ "CO_MsgCategory" BO_ 1871 505;
BA_ "CO_MsgCategory" BO_ 1487 410;
BA_ "CO_MsgCategory" BO_ 1615 405;
BA_ "CO_MsgCategory" BO_ 207 205;
BA_ "CO_MsgCategory" BO_ 1870 505;
BA_ "CO_MsgCategory" BO_ 1486 410;
BA_ "CO_MsgCategory" BO_ 1614 405;
BA_ "CO_MsgCategory" BO_ 206 205;
BA_ "CO_MsgCategory" BO_ 1869 505;
BA_ "CO_MsgCategory" BO_ 1485 410;
BA_ "CO_MsgCategory" BO_ 1613 405;
BA_ "CO_MsgCategory" BO_ 205 205;
BA_ "CO_MsgCategory" BO_ 1868 505;
BA_ "CO_MsgCategory" BO_ 1484 410;
BA_ "CO_MsgCategory" BO_ 1612 405;
BA_ "CO_MsgCategory" BO_ 204 205;
BA_ "CO_MsgCategory" BO_ 1867 505;
BA_ "CO_MsgCategory" BO_ 1483 410;
BA_ "CO_MsgCategory" BO_ 1611 405;
BA_ "CO_MsgCategory" BO_ 203 205;
BA_ "CO_MsgCategory" BO_ 1866 505;
BA_ "CO_MsgCategory" BO_ 1482 410;
BA_ "CO_MsgCategory" BO_ 1610 405;
BA_ "CO_MsgCategory" BO_ 202 205;
BA_ "CO_MsgCategory" BO_ 1865 505;
BA_ "CO_MsgCategory" BO_ 1481 410;
BA_ "CO_MsgCategory" BO_ 1609 405;
BA_ "CO_MsgCategory" BO_ 201 205;
BA_ "CO_MsgCategory" BO_ 1864 505;
BA_ "CO_MsgCategory" BO_ 1480 410;
BA_ "CO_MsgCategory" BO_ 1608 405;
BA_ "CO_MsgCategory" BO_ 200 205;
BA_ "CO_MsgCategory" BO_ 1863 505;
BA_ "CO_MsgCategory" BO_ 1479 410;
BA_ "CO_MsgCategory" BO_ 1607 405;
BA_ "CO_MsgCategory" BO_ 199 205;
BA_ "CO_MsgCategory" BO_ 1862 505;
BA_ "CO_MsgCategory" BO_ 1478 410;
BA_ "CO_MsgCategory" BO_ 1606 405;
BA_ "CO_MsgCategory" BO_ 198 205;
BA_ "CO_MsgCategory" BO_ 1861 505;
BA_ "CO_MsgCategory" BO_ 1477 410;
BA_ "CO_MsgCategory" BO_ 1605 405;
BA_ "CO_MsgCategory" BO_ 197 205;
BA_ "CO_MsgCategory" BO_ 1860 505;
BA_ "CO_MsgCategory" BO_ 1476 410;
BA_ "CO_MsgCategory" BO_ 1604 405;
BA_ "CO_MsgCategory" BO_ 196 205;
BA_ "CO_MsgCategory" BO_ 1859 505;
BA_ "CO_MsgCategory" BO_ 1475 410;
BA_ "CO_MsgCategory" BO_ 1603 405;
BA_ "CO_MsgCategory" BO_ 195 205;
BA_ "CO_MsgCategory" BO_ 1858 505;
BA_ "CO_MsgCategory" BO_ 1474 410;
BA_ "CO_MsgCategory" BO_ 1602 405;
BA_ "CO_MsgCategory" BO_ 194 205;
BA_ "CO_MsgCategory" BO_ 1857 505;
BA_ "CO_MsgCategory" BO_ 1473 410;
BA_ "CO_MsgCategory" BO_ 1601 405;
BA_ "CO_MsgCategory" BO_ 193 205;
BA_ "CO_MsgCategory" BO_ 1856 505;
BA_ "CO_MsgCategory" BO_ 1472 410;
BA_ "CO_MsgCategory" BO_ 1600 405;
BA_ "CO_MsgCategory" BO_ 192 205;
BA_ "CO_MsgCategory" BO_ 1855 505;
BA_ "CO_MsgCategory" BO_ 1471 410;
BA_ "CO_MsgCategory" BO_ 1599 405;
BA_ "CO_MsgCategory" BO_ 191 205;
BA_ "CO_MsgCategory" BO_ 1854 505;
BA_ "CO_MsgCategory" BO_ 1470 410;
BA_ "CO_MsgCategory" BO_ 1598 405;
BA_ "CO_MsgCategory" BO_ 190 205;
BA_ "CO_MsgCategory" BO_ 1853 505;
BA_ "CO_MsgCategory" BO_ 1469 410;
BA_ "CO_MsgCategory" BO_ 1597 405;
BA_ "CO_MsgCategory" BO_ 189 205;
BA_ "CO_MsgCategory" BO_ 1852 505;
BA_ "CO_MsgCategory" BO_ 1468 410;
BA_ "CO_MsgCategory" BO_ 1596 405;
BA_ "CO_MsgCategory" BO_ 188 205;
BA_ "CO_MsgCategory" BO_ 1851 505;
BA_ "CO_MsgCategory" BO_ 1467 410;
BA_ "CO_MsgCategory" BO_ 1595 405;
BA_ "CO_MsgCategory" BO_ 187 205;
BA_ "CO_MsgCategory" BO_ 1850 505;
BA_ "CO_MsgCategory" BO_ 1466 410;
BA_ "CO_MsgCategory" BO_ 1594 405;
BA_ "CO_MsgCategory" BO_ 186 205;
BA_ "CO_MsgCategory" BO_ 1849 505;
BA_ "CO_MsgCategory" BO_ 1465 410;
BA_ "CO_MsgCategory" BO_ 1593 405;
BA_ "CO_MsgCategory" BO_ 185 205;
BA_ "CO_MsgCategory" BO_ 1848 505;
BA_ "CO_MsgCategory" BO_ 1464 410;
BA_ "CO_MsgCategory" BO_ 1592 405;
BA_ "CO_MsgCategory" BO_ 184 205;
BA_ "CO_MsgCategory" BO_ 1847 505;
BA_ "CO_MsgCategory" BO_ 1463 410;
BA_ "CO_MsgCategory" BO_ 1591 405;
BA_ "CO_MsgCategory" BO_ 183 205;
BA_ "CO_MsgCategory" BO_ 1846 505;
BA_ "CO_MsgCategory" BO_ 1462 410;
BA_ "CO_MsgCategory" BO_ 1590 405;
BA_ "CO_MsgCategory" BO_ 182 205;
BA_ "CO_MsgCategory" BO_ 1845 505;
BA_ "CO_MsgCategory" BO_ 1461 410;
BA_ "CO_MsgCategory" BO_ 1589 405;
BA_ "CO_MsgCategory" BO_ 181 205;
BA_ "CO_MsgCategory" BO_ 1844 505;
BA_ "CO_MsgCategory" BO_ 1460 410;
BA_ "CO_MsgCategory" BO_ 1588 405;
BA_ "CO_MsgCategory" BO_ 180 205;
BA_ "CO_MsgCategory" BO_ 1843 505;
BA_ "CO_MsgCategory" BO_ 1459 410;
BA_ "CO_MsgCategory" BO_ 1587 405;
BA_ "CO_MsgCategory" BO_ 179 205;
BA_ "CO_MsgCategory" BO_ 1842 505;
BA_ "CO_MsgCategory" BO_ 1458 410;
BA_ "CO_MsgCategory" BO_ 1586 405;
BA_ "CO_MsgCategory" BO_ 178 205;
BA_ "CO_MsgCategory" BO_ 1841 505;
BA_ "CO_MsgCategory" BO_ 1457 410;
BA_ "CO_MsgCategory" BO_ 1585 405;
BA_ "CO_MsgCategory" BO_ 177 205;
BA_ "CO_MsgCategory" BO_ 1840 505;
BA_ "CO_MsgCategory" BO_ 1456 410;
BA_ "CO_MsgCategory" BO_ 1584 405;
BA_ "CO_MsgCategory" BO_ 176 205;
BA_ "CO_MsgCategory" BO_ 1839 505;
BA_ "CO_MsgCategory" BO_ 1455 410;
BA_ "CO_MsgCategory" BO_ 1583 405;
BA_ "CO_MsgCategory" BO_ 175 205;
BA_ "CO_MsgCategory" BO_ 1838 505;
BA_ "CO_MsgCategory" BO_ 1454 410;
BA_ "CO_MsgCategory" BO_ 1582 405;
BA_ "CO_MsgCategory" BO_ 174 205;
BA_ "CO_MsgCategory" BO_ 1837 505;
BA_ "CO_MsgCategory" BO_ 1453 410;
BA_ "CO_MsgCategory" BO_ 1581 405;
BA_ "CO_MsgCategory" BO_ 173 205;
BA_ "CO_MsgCategory" BO_ 1836 505;
BA_ "CO_MsgCategory" BO_ 1452 410;
BA_ "CO_MsgCategory" BO_ 1580 405;
BA_ "CO_MsgCategory" BO_ 172 205;
BA_ "CO_MsgCategory" BO_ 1835 505;
BA_ "CO_MsgCategory" BO_ 1451 410;
BA_ "CO_MsgCategory" BO_ 1579 405;
BA_ "CO_MsgCategory" BO_ 171 205;
BA_ "CO_MsgCategory" BO_ 1834 505;
BA_ "CO_MsgCategory" BO_ 1450 410;
BA_ "CO_MsgCategory" BO_ 1578 405;
BA_ "CO_MsgCategory" BO_ 170 205;
BA_ "CO_MsgCategory" BO_ 1833 505;
BA_ "CO_MsgCategory" BO_ 1449 410;
BA_ "CO_MsgCategory" BO_ 1577 405;
BA_ "CO_MsgCategory" BO_ 169 205;
BA_ "CO_MsgCategory" BO_ 1832 505;
BA_ "CO_MsgCategory" BO_ 1448 410;
BA_ "CO_MsgCategory" BO_ 1576 405;
BA_ "CO_MsgCategory" BO_ 168 205;
BA_ "CO_MsgCategory" BO_ 1831 505;
BA_ "CO_MsgCategory" BO_ 1447 410;
BA_ "CO_MsgCategory" BO_ 1575 405;
BA_ "CO_MsgCategory" BO_ 167 205;
BA_ "CO_MsgCategory" BO_ 1830 505;
BA_ "CO_MsgCategory" BO_ 1446 410;
BA_ "CO_MsgCategory" BO_ 1574 405;
BA_ "CO_MsgCategory" BO_ 166 205;
BA_ "CO_MsgCategory" BO_ 1829 505;
BA_ "CO_MsgCategory" BO_ 1445 410;
BA_ "CO_MsgCategory" BO_ 1573 405;
BA_ "CO_MsgCategory" BO_ 165 205;
BA_ "CO_MsgCategory" BO_ 1828 505;
BA_ "CO_MsgCategory" BO_ 1444 410;
BA_ "CO_MsgCategory" BO_ 1572 405;
BA_ "CO_MsgCategory" BO_ 164 205;
BA_ "CO_MsgCategory" BO_ 1827 505;
BA_ "CO_MsgCategory" BO_ 1443 410;
BA_ "CO_MsgCategory" BO_ 1571 405;
BA_ "CO_MsgCategory" BO_ 163 205;
BA_ "CO_MsgCategory" BO_ 1826 505;
BA_ "CO_MsgCategory" BO_ 1442 410;
BA_ "CO_MsgCategory" BO_ 1570 405;
BA_ "CO_MsgCategory" BO_ 162 205;
BA_ "CO_MsgCategory" BO_ 1825 505;
BA_ "CO_MsgCategory" BO_ 1441 410;
BA_ "CO_MsgCategory" BO_ 1569 405;
BA_ "CO_MsgCategory" BO_ 161 205;
BA_ "CO_MsgCategory" BO_ 1824 505;
BA_ "CO_MsgCategory" BO_ 1440 410;
BA_ "CO_MsgCategory" BO_ 1568 405;
BA_ "CO_MsgCategory" BO_ 160 205;
BA_ "CO_MsgCategory" BO_ 1823 505;
BA_ "CO_MsgCategory" BO_ 1439 410;
BA_ "CO_MsgCategory" BO_ 1567 405;
BA_ "CO_MsgCategory" BO_ 159 205;
BA_ "CO_MsgCategory" BO_ 1822 505;
BA_ "CO_MsgCategory" BO_ 1438 410;
BA_ "CO_MsgCategory" BO_ 1566 405;
BA_ "CO_MsgCategory" BO_ 158 205;
BA_ "CO_MsgCategory" BO_ 1821 505;
BA_ "CO_MsgCategory" BO_ 1437 410;
BA_ "CO_MsgCategory" BO_ 1565 405;
BA_ "CO_MsgCategory" BO_ 157 205;
BA_ "CO_MsgCategory" BO_ 1820 505;
BA_ "CO_MsgCategory" BO_ 1436 410;
BA_ "CO_MsgCategory" BO_ 1564 405;
BA_ "CO_MsgCategory" BO_ 156 205;
BA_ "CO_MsgCategory" BO_ 1819 505;
BA_ "CO_MsgCategory" BO_ 1435 410;
BA_ "CO_MsgCategory" BO_ 1563 405;
BA_ "CO_MsgCategory" BO_ 155 205;
BA_ "CO_MsgCategory" BO_ 1818 505;
BA_ "CO_MsgCategory" BO_ 1434 410;
BA_ "CO_MsgCategory" BO_ 1562 405;
BA_ "CO_MsgCategory" BO_ 154 205;
BA_ "CO_MsgCategory" BO_ 1817 505;
BA_ "CO_MsgCategory" BO_ 1433 410;
BA_ "CO_MsgCategory" BO_ 1561 405;
BA_ "CO_MsgCategory" BO_ 153 205;
BA_ "CO_MsgCategory" BO_ 1816 505;
BA_ "CO_MsgCategory" BO_ 1432 410;
BA_ "CO_MsgCategory" BO_ 1560 405;
BA_ "CO_MsgCategory" BO_ 152 205;
BA_ "CO_MsgCategory" BO_ 1815 505;
BA_ "CO_MsgCategory" BO_ 1431 410;
BA_ "CO_MsgCategory" BO_ 1559 405;
BA_ "CO_MsgCategory" BO_ 151 205;
BA_ "CO_MsgCategory" BO_ 1814 505;
BA_ "CO_MsgCategory" BO_ 1430 410;
BA_ "CO_MsgCategory" BO_ 1558 405;
BA_ "CO_MsgCategory" BO_ 150 205;
BA_ "CO_MsgCategory" BO_ 1812 505;
BA_ "CO_MsgCategory" BO_ 1428 410;
BA_ "CO_MsgCategory" BO_ 1556 405;
BA_ "CO_MsgCategory" BO_ 148 205;
BA_ "CO_MsgCategory" BO_ 1811 505;
BA_ "CO_MsgCategory" BO_ 1427 410;
BA_ "CO_MsgCategory" BO_ 1555 405;
BA_ "CO_MsgCategory" BO_ 147 205;
BA_ "CO_MsgCategory" BO_ 1810 505;
BA_ "CO_MsgCategory" BO_ 1426 410;
BA_ "CO_MsgCategory" BO_ 1554 405;
BA_ "CO_MsgCategory" BO_ 146 205;
BA_ "CO_MsgCategory" BO_ 1809 505;
BA_ "CO_MsgCategory" BO_ 1425 410;
BA_ "CO_MsgCategory" BO_ 1553 405;
BA_ "CO_MsgCategory" BO_ 145 205;
BA_ "CO_MsgCategory" BO_ 1808 505;
BA_ "CO_MsgCategory" BO_ 1424 410;
BA_ "CO_MsgCategory" BO_ 1552 405;
BA_ "CO_MsgCategory" BO_ 144 205;
BA_ "CO_MsgCategory" BO_ 1807 505;
BA_ "CO_MsgCategory" BO_ 1423 410;
BA_ "CO_MsgCategory" BO_ 1551 405;
BA_ "CO_MsgCategory" BO_ 143 205;
BA_ "CO_MsgCategory" BO_ 1806 505;
BA_ "CO_MsgCategory" BO_ 1422 410;
BA_ "CO_MsgCategory" BO_ 1550 405;
BA_ "CO_MsgCategory" BO_ 142 205;
BA_ "CO_MsgCategory" BO_ 1805 505;
BA_ "CO_MsgCategory" BO_ 1421 410;
BA_ "CO_MsgCategory" BO_ 1549 405;
BA_ "CO_MsgCategory" BO_ 141 205;
BA_ "CO_MsgCategory" BO_ 1804 505;
BA_ "CO_MsgCategory" BO_ 1420 410;
BA_ "CO_MsgCategory" BO_ 1548 405;
BA_ "CO_MsgCategory" BO_ 140 205;
BA_ "CO_MsgCategory" BO_ 1803 505;
BA_ "CO_MsgCategory" BO_ 1419 410;
BA_ "CO_MsgCategory" BO_ 1547 405;
BA_ "CO_MsgCategory" BO_ 139 205;
BA_ "CO_MsgCategory" BO_ 1801 505;
BA_ "CO_MsgCategory" BO_ 1417 410;
BA_ "CO_MsgCategory" BO_ 1545 405;
BA_ "CO_MsgCategory" BO_ 137 205;
BA_ "CO_MsgCategory" BO_ 1799 505;
BA_ "CO_MsgCategory" BO_ 1415 410;
BA_ "CO_MsgCategory" BO_ 1543 405;
BA_ "CO_MsgCategory" BO_ 135 205;
BA_ "CO_MsgCategory" BO_ 1798 505;
BA_ "CO_MsgCategory" BO_ 1414 410;
BA_ "CO_MsgCategory" BO_ 1542 405;
BA_ "CO_MsgCategory" BO_ 134 205;
BA_ "CO_MsgCategory" BO_ 1797 505;
BA_ "CO_MsgCategory" BO_ 1413 410;
BA_ "CO_MsgCategory" BO_ 1541 405;
BA_ "CO_MsgCategory" BO_ 133 205;
BA_ "CO_MsgCategory" BO_ 1796 505;
BA_ "CO_MsgCategory" BO_ 1412 410;
BA_ "CO_MsgCategory" BO_ 1540 405;
BA_ "CO_MsgCategory" BO_ 132 205;
BA_ "CO_MsgCategory" BO_ 1795 505;
BA_ "CO_MsgCategory" BO_ 1411 410;
BA_ "CO_MsgCategory" BO_ 1539 405;
BA_ "CO_MsgCategory" BO_ 131 205;
BA_ "CO_MsgCategory" BO_ 1794 505;
BA_ "CO_MsgCategory" BO_ 1410 410;
BA_ "CO_MsgCategory" BO_ 1538 405;
BA_ "CO_MsgCategory" BO_ 130 205;
BA_ "CO_MsgCategory" BO_ 256 115;
BA_ "CO_MsgCategory" BO_ 128 110;
BA_ "CO_MsgCategory" BO_ 0 105;
BA_ "CO_MsgCategory" BO_ 2021 610;
BA_ "CO_MsgCategory" BO_ 2020 605;
BA_ "CO_MsgCategory" BO_ 1 705;
BA_ "CO_MsgCategory" BO_ 1173 335;
BA_ "CO_MsgCategory" BO_ 917 325;
BA_ "CO_MsgCategory" BO_ 661 315;
BA_ "CO_MsgCategory" BO_ 405 305;
BA_ "CO_MsgCategory" BO_ 650 315;
BA_ "CO_MsgCategory" BO_ 394 305;
BA_ "CO_MsgCategory" BO_ 1160 335;
BA_ "CO_MsgCategory" BO_ 648 315;
BA_ "CO_MsgCategory" BO_ 392 305;
VAL_ 1813 State 127 "PreOperational" 5 "Operational" 4 "Stopped" 0 "Bootup" ;
VAL_ 1429 SCS 2 "Upload" 1 "Download" ;
VAL_ 1557 CCS 2 "Upload" 1 "Download" ;
VAL_ 149 ErrorCode 33360 "RPDO timeout" 33344 "Unexpected SYNC data length" 33328 "DAM MPDO not processed, destination object not available" 33312 "PDO length exceeded" 33296 "PDO not processed due to length error" 33104 "Transmit COB-ID collision" 33088 "Recovered from bus off state" 33072 "Life guard error or heartbeat error" 33056 "CAN in error passive mode" 33040 "CAN overrun (objects lost)" ;
VAL_ 1802 State 127 "PreOperational" 5 "Operational" 4 "Stopped" 0 "Bootup" ;
VAL_ 1418 SCS 2 "Upload" 1 "Download" ;
VAL_ 1546 CCS 2 "Upload" 1 "Download" ;
VAL_ 138 ErrorCode 33360 "RPDO timeout" 33344 "Unexpected SYNC data length" 33328 "DAM MPDO not processed, destination object not available" 33312 "PDO length exceeded" 33296 "PDO not processed due to length error" 33104 "Transmit COB-ID collision" 33088 "Recovered from bus off state" 33072 "Life guard error or heartbeat error" 33056 "CAN in error passive mode" 33040 "CAN overrun (objects lost)" ;
VAL_ 1800 State 127 "PreOperational" 5 "Operational" 4 "Stopped" 0 "Bootup" ;
VAL_ 1416 SCS 2 "Upload" 1 "Download" ;
VAL_ 1544 CCS 2 "Upload" 1 "Download" ;
VAL_ 136 ErrorCode 33360 "RPDO timeout" 33344 "Unexpected SYNC data length" 33328 "DAM MPDO not processed, destination object not available" 33312 "PDO length exceeded" 33296 "PDO not processed due to length error" 33104 "Transmit COB-ID collision" 33088 "Recovered from bus off state" 33072 "Life guard error or heartbeat error" 33056 "CAN in error passive mode" 33040 "CAN overrun (objects lost)" ;
VAL_ 1793 State 127 "PreOperational" 5 "Operational" 4 "Stopped" 0 "Bootup" ;
VAL_ 1409 SCS 2 "Upload" 1 "Download" ;
VAL_ 1537 CCS 2 "Upload" 1 "Download" ;
VAL_ 129 ErrorCode 61444 "(DS-402) Control error" 61443 "(DS-402) Control, stroke operation" 61442 "(DS-402) Control, sub-synchronous run" 61441 "(DS-402) Control, deceleration" 35072 "(DS-402) Winding controller - process data monitoring" 34816 "(DS-402) Winding controller" 34560 "(DS-402) Sync controller" 34322 "(DS-402) Positioning - reference limit" 34321 "(DS-402) Positioning - following error" 34304 "(DS-402) Positioning controller" 34048 "(DS-402) Position controller" 33792 "(DS-402) Velocity speed controller" 33585 "(DS-402) Torque fault" 33569 "(DS-402) Insufficient torque" 33555 "(DS-402) Standstill torque" 33554 "(DS-402) Difficult start up" 33553 "(DS-402) Excess torque" 33536 "(DS-402) Torque control" 30208 "(DS-402) Data storage (external)" 29984 "(DS-402) Serial interface no. 2" 29968 "(DS-402) Serial interface no. 1" 29952 "(DS-402) Communication" 29696 "(DS-402) Computation circuit" 29472 "(DS-402) Position" 29456 "(DS-402) Speed" 29447 "(DS-402) Incremental sensor 3 fault" 29446 "(DS-402) Incremental sensor 2 fault" 29445 "(DS-402) Incremental sensor 1 fault" 29444 "(DS-402) Resolver 2 fault" 29443 "(DS-402) Resolver 1 fault" 29442 "(DS-402) Tacho wrong polarity" 29441 "(DS-402) Tacho fault" 29440 "(DS-402) Sensor" 29184 "(DS-402) Measurement circuit  " 28963 "(DS-402) Motor tilted" 28962 "(DS-402) Motor error or commutation malfunction" 28961 "(DS-402) Motor blocked" 28960 "(DS-402) Motor" 28947 "(DS-402) Protective circuit brake chopper" 28946 "(DS-402) Over current brake chopper" 28945 "(DS-402) Failure brake chopper" 28944 "(DS-402) Brake chopper" 28928 "(DS-402) Power" 25376 "(DS-402) Parameter error" 25360 "(DS-402) Loss of parameters" 25359 "(DS-402) Reset watchdog - data record no. 15" 25358 "(DS-402) Reset watchdog - data record no. 14" 25357 "(DS-402) Reset watchdog - data record no. 13" 25356 "(DS-402) Reset watchdog - data record no. 12" 25355 "(DS-402) Reset watchdog - data record no. 11" 25354 "(DS-402) Reset watchdog - data record no. 10" 25353 "(DS-402) Reset watchdog - data record no. 9" 25352 "(DS-402) Reset watchdog - data record no. 8" 25351 "(DS-402) Reset watchdog - data record no. 7" 25350 "(DS-402) Reset watchdog - data record no. 6" 25349 "(DS-402) Reset watchdog - data record no. 5" 25348 "(DS-402) Reset watchdog - data record no. 4" 25347 "(DS-402) Reset watchdog - data record no. 3" 25346 "(DS-402) Reset watchdog - data record no. 2" 25345 "(DS-402) Reset watchdog - data record no. 1" 24592 "(DS-402) Software reset (watchdog)" 21808 "(DS-402) EEPROM" 21792 "(DS-402) ROM/EPROM" 21776 "(DS-402) RAM" 21760 "(DS-402) Hardware memory" 21593 "(DS-402) Fuses S9 = manufacturer-specific" 21592 "(DS-402) Fuses S8 = manufacturer-specific" 21591 "(DS-402) Fuses S7 = manufacturer-specific" 21590 "(DS-402) Fuses S6 = manufacturer-specific" 21589 "(DS-402) Fuses S5 = manufacturer-specific" 21588 "(DS-402) Fuses S4 = manufacturer-specific" 21587 "(DS-402) Fuses S3 = l3" 21586 "(DS-402) Fuses S2 = l2" 21585 "(DS-402) Fuses S1 = l1" 21584 "(DS-402) Fuses" 21573 "(DS-402) Contact 5 = manufacturer-specific" 21572 "(DS-402) Contact 4 = manufacturer-specific" 21571 "(DS-402) Contact 3 = manufacturer-specific" 21570 "(DS-402) Contact 2 = manufacturer-specific" 21569 "(DS-402) Contact 1 = manufacturer-specific" 21568 "(DS-402) Contacts" 21552 "(DS-402) Input stages" 21536 "(DS-402) Chopper" 21520 "(DS-402) Output stages" 21504 "(DS-402) Power section" 21248 "(DS-402) Operating unit" 21024 "(DS-402) Control, computing circuit" 21008 "(DS-402) Control, measurement circuit" 35328 "(DS-402) Control" 20768 "(DS-402) Supply intermediate circuit" 20761 "(DS-402) Supply low voltage U9 = manufacturer-specific" 20760 "(DS-402) Supply low voltage U8 = manufacturer-specific" 20759 "(DS-402) Supply low voltage U7 = manufacturer-specific" 20758 "(DS-402) Supply low voltage U6 = manufacturer-specific" 20757 "(DS-402) Supply low voltage U5 = manufacturer-specific" 20756 "(DS-402) Supply low voltage U4 = manufacturer-specific" 20755 "(DS-402) Supply low voltage U3 = supply +5 V" 20754 "(DS-402) Supply low voltage U2 = supply +24V" 20753 "(DS-402) Supply low voltage U1 = supply ±15V" 20752 "(DS-402) Supply low voltage" 20736 "(DS-402) Supply" 17440 "(DS-402) Too low temperature supply" 17424 "(DS-402) Excess temperature supply" 17408 "(DS-402) Temperature supply" 17184 "(DS-402) Too low temperature drive" 17168 "(DS-402) Excess temperature drive" 17152 "(DS-402) Temperature drive" 16928 "(DS-402) Field circ. interrupted, too low temperature device" 16912 "(DS-402) Field circ. interrupted, excess temperature device" 16704 "(DS-402) Field circ. interrupted, temperature air outlet" 16688 "(DS-402) Field circ. interrupted, temperature supply air" 16672 "(DS-402) Field circ. interrupted, too low ambient temperature" 16656 "(DS-402) Field circ. interrupted, Excess ambient temperature" 13105 "(DS-402) Field circuit interrupted" 13104 "(DS-402) Field circuit" 13089 "(DS-402) Armature circuit interrupted" 13088 "(DS-402) Armature circuit" 13075 "(DS-402) Output over-voltage phase W " 13074 "(DS-402) Output over-voltage phase V " 13073 "(DS-402) Output over-voltage phase U " 13072 "(DS-402) Output over-voltage" 12848 "(DS-402) Load error" 12834 "(DS-402) DC link under-voltage no. 2" 12833 "(DS-402) DC link under-voltage no. 1" 12832 "(DS-402) DC link under-voltage" 12818 "(DS-402) DC link over voltage no. 2" 12817 "(DS-402) DC link over-voltage no. 1" 12816 "(DS-402) DC link over-voltage" 12610 "(DS-402) Mains frequency too small" 12609 "(DS-402) Mains frequency too great" 12608 "(DS-402) Mains frequency" 12596 "(DS-402) Phase sequence" 12595 "(DS-402) Phase failure L3" 12594 "(DS-402) Phase failure L2" 12593 "(DS-402) Phase failure L1" 12592 "(DS-402) Phase failure" 12579 "(DS-402) Mains under-voltage phase L3" 12578 "(DS-402) Mains under-voltage phase L2" 12577 "(DS-402) Mains under-voltage phase L1" 12576 "(DS-402) Mains under-voltage" 12563 "(DS-402) Mains over-voltage phase L3 " 12562 "(DS-402) Mains over-voltage phase L2" 12561 "(DS-402) Mains over-voltage phase L1" 12560 "(DS-402) Mains over-voltage" 9041 "(DS-402) Load level warning (I2t, thermal state)" 9040 "(DS-402) Load level fault (I2t, thermal state)" 9027 "(DS-402) Earth leakage (motor-side) phase W-U" 9026 "(DS-402) Earth leakage (motor-side) phase V-W" 9025 "(DS-402) Short circuit (motor-side) phases U-V" 9024 "(DS-402) Short circuit (motor-side)" 9011 "(DS-402) Earth leakage (motor-side) phase W" 9010 "(DS-402) Earth leakage (motor-side) phase V" 9009 "(DS-402) Earth leakage (motor-side) phase U" 9008 "(DS-402) Earth leakage (motor-side)" 8992 "(DS-402) Short circuit/earth leakage (motor-side)" 8978 "(DS-402) Device internal, continuous over current no. 2" 8977 "(DS-402) Device internal, continuous over current no. 1" 8976 "(DS-402) Device internal, continuous over current" 8784 "(DS-402) Short circuit (device internal) " 8768 "(DS-402) Earth leakage (device internal)" 8752 "(DS-402) Short circuit/earth leakage (device internal)" 8738 "(DS-402) Continuous over current no.2" 8737 "(DS-402) Continuous over current no.1" 8736 "(DS-402) Continuous over current (device internal)" 8724 "(DS-402) Short circuit (input), over-current in the sequence" 8723 "(DS-402) Short circuit (input), over-current in ramp function" 8722 "(DS-402) Short circuit (input), internal current no.2" 8721 "(DS-402) Short circuit (input), internal current no.1" 8499 "(DS-402) Short circuit phases (input) L3-L1" 8498 "(DS-402) Short circuit phases (input) L2-L3" 8497 "(DS-402) Short circuit phases (input) L1-L2" 8496 "(DS-402) Short circuit (input)" 8483 "(DS-402) Earth leakage (input) phase L3" 8482 "(DS-402) Earth leakage (input) phase L2" 8481 "(DS-402) Earth leakage (input) phase L1" 8480 "(DS-402) Earth leakage (input)" 8464 "(DS-402) Short circuit/earth leakage (input)" 33360 "RPDO timeout" 33344 "Unexpected SYNC data length" 33328 "DAM MPDO not processed, destination object not available" 33312 "PDO length exceeded" 33296 "PDO not processed due to length error" 33104 "Transmit COB-ID collision" 33088 "Recovered from bus off state" 33072 "Life guard error or heartbeat error" 33056 "CAN in error passive mode" 33040 "CAN overrun (objects lost)" ;
VAL_ 1919 State 127 "PreOperational" 5 "Operational" 4 "Stopped" 0 "Bootup" ;
VAL_ 1918 State 127 "PreOperational" 5 "Operational" 4 "Stopped" 0 "Bootup" ;
VAL_ 1917 State 127 "PreOperational" 5 "Operational" 4 "Stopped" 0 "Bootup" ;
VAL_ 1916 State 127 "PreOperational" 5 "Operational" 4 "Stopped" 0 "Bootup" ;
VAL_ 1915 State 127 "PreOperational" 5 "Operational" 4 "Stopped" 0 "Bootup" ;
VAL_ 1914 State 127 "PreOperational" 5 "Operational" 4 "Stopped" 0 "Bootup" ;
VAL_ 1913 State 127 "PreOperational" 5 "Operational" 4 "Stopped" 0 "Bootup" ;
VAL_ 1912 State 127 "PreOperational" 5 "Operational" 4 "Stopped" 0 "Bootup" ;
VAL_ 1911 State 127 "PreOperational" 5 "Operational" 4 "Stopped" 0 "Bootup" ;
VAL_ 1910 State 127 "PreOperational" 5 "Operational" 4 "Stopped" 0 "Bootup" ;
VAL_ 1909 State 127 "PreOperational" 5 "Operational" 4 "Stopped" 0 "Bootup" ;
VAL_ 1908 State 127 "PreOperational" 5 "Operational" 4 "Stopped" 0 "Bootup" ;
VAL_ 1907 State 127 "PreOperational" 5 "Operational" 4 "Stopped" 0 "Bootup" ;
VAL_ 1906 State 127 "PreOperational" 5 "Operational" 4 "Stopped" 0 "Bootup" ;
VAL_ 1905 State 127 "PreOperational" 5 "Operational" 4 "Stopped" 0 "Bootup" ;
VAL_ 1904 State 127 "PreOperational" 5 "Operational" 4 "Stopped" 0 "Bootup" ;
VAL_ 1903 State 127 "PreOperational" 5 "Operational" 4 "Stopped" 0 "Bootup" ;
VAL_ 1902 State 127 "PreOperational" 5 "Operational" 4 "Stopped" 0 "Bootup" ;
VAL_ 1901 State 127 "PreOperational" 5 "Operational" 4 "Stopped" 0 "Bootup" ;
VAL_ 1900 State 127 "PreOperational" 5 "Operational" 4 "Stopped" 0 "Bootup" ;
VAL_ 1899 State 127 "PreOperational" 5 "Operational" 4 "Stopped" 0 "Bootup" ;
VAL_ 1898 State 127 "PreOperational" 5 "Operational" 4 "Stopped" 0 "Bootup" ;
VAL_ 1897 State 127 "PreOperational" 5 "Operational" 4 "Stopped" 0 "Bootup" ;
VAL_ 1896 State 127 "PreOperational" 5 "Operational" 4 "Stopped" 0 "Bootup" ;
VAL_ 1895 State 127 "PreOperational" 5 "Operational" 4 "Stopped" 0 "Bootup" ;
VAL_ 1894 State 127 "PreOperational" 5 "Operational" 4 "Stopped" 0 "Bootup" ;
VAL_ 1893 State 127 "PreOperational" 5 "Operational" 4 "Stopped" 0 "Bootup" ;
VAL_ 1892 State 127 "PreOperational" 5 "Operational" 4 "Stopped" 0 "Bootup" ;
VAL_ 1891 State 127 "PreOperational" 5 "Operational" 4 "Stopped" 0 "Bootup" ;
VAL_ 1890 State 127 "PreOperational" 5 "Operational" 4 "Stopped" 0 "Bootup" ;
VAL_ 1889 State 127 "PreOperational" 5 "Operational" 4 "Stopped" 0 "Bootup" ;
VAL_ 1888 State 127 "PreOperational" 5 "Operational" 4 "Stopped" 0 "Bootup" ;
VAL_ 1887 State 127 "PreOperational" 5 "Operational" 4 "Stopped" 0 "Bootup" ;
VAL_ 1886 State 127 "PreOperational" 5 "Operational" 4 "Stopped" 0 "Bootup" ;
VAL_ 1885 State 127 "PreOperational" 5 "Operational" 4 "Stopped" 0 "Bootup" ;
VAL_ 1884 State 127 "PreOperational" 5 "Operational" 4 "Stopped" 0 "Bootup" ;
VAL_ 1883 State 127 "PreOperational" 5 "Operational" 4 "Stopped" 0 "Bootup" ;
VAL_ 1882 State 127 "PreOperational" 5 "Operational" 4 "Stopped" 0 "Bootup" ;
VAL_ 1881 State 127 "PreOperational" 5 "Operational" 4 "Stopped" 0 "Bootup" ;
VAL_ 1880 State 127 "PreOperational" 5 "Operational" 4 "Stopped" 0 "Bootup" ;
VAL_ 1879 State 127 "PreOperational" 5 "Operational" 4 "Stopped" 0 "Bootup" ;
VAL_ 1878 State 127 "PreOperational" 5 "Operational" 4 "Stopped" 0 "Bootup" ;
VAL_ 1877 State 127 "PreOperational" 5 "Operational" 4 "Stopped" 0 "Bootup" ;
VAL_ 1876 State 127 "PreOperational" 5 "Operational" 4 "Stopped" 0 "Bootup" ;
VAL_ 1875 State 127 "PreOperational" 5 "Operational" 4 "Stopped" 0 "Bootup" ;
VAL_ 1874 State 127 "PreOperational" 5 "Operational" 4 "Stopped" 0 "Bootup" ;
VAL_ 1873 State 127 "PreOperational" 5 "Operational" 4 "Stopped" 0 "Bootup" ;
VAL_ 1872 State 127 "PreOperational" 5 "Operational" 4 "Stopped" 0 "Bootup" ;
VAL_ 1871 State 127 "PreOperational" 5 "Operational" 4 "Stopped" 0 "Bootup" ;
VAL_ 1870 State 127 "PreOperational" 5 "Operational" 4 "Stopped" 0 "Bootup" ;
VAL_ 1869 State 127 "PreOperational" 5 "Operational" 4 "Stopped" 0 "Bootup" ;
VAL_ 1868 State 127 "PreOperational" 5 "Operational" 4 "Stopped" 0 "Bootup" ;
VAL_ 1867 State 127 "PreOperational" 5 "Operational" 4 "Stopped" 0 "Bootup" ;
VAL_ 1866 State 127 "PreOperational" 5 "Operational" 4 "Stopped" 0 "Bootup" ;
VAL_ 1865 State 127 "PreOperational" 5 "Operational" 4 "Stopped" 0 "Bootup" ;
VAL_ 1864 State 127 "PreOperational" 5 "Operational" 4 "Stopped" 0 "Bootup" ;
VAL_ 1863 State 127 "PreOperational" 5 "Operational" 4 "Stopped" 0 "Bootup" ;
VAL_ 1862 State 127 "PreOperational" 5 "Operational" 4 "Stopped" 0 "Bootup" ;
VAL_ 1861 State 127 "PreOperational" 5 "Operational" 4 "Stopped" 0 "Bootup" ;
VAL_ 1860 State 127 "PreOperational" 5 "Operational" 4 "Stopped" 0 "Bootup" ;
VAL_ 1859 State 127 "PreOperational" 5 "Operational" 4 "Stopped" 0 "Bootup" ;
VAL_ 1858 State 127 "PreOperational" 5 "Operational" 4 "Stopped" 0 "Bootup" ;
VAL_ 1857 State 127 "PreOperational" 5 "Operational" 4 "Stopped" 0 "Bootup" ;
VAL_ 1856 State 127 "PreOperational" 5 "Operational" 4 "Stopped" 0 "Bootup" ;
VAL_ 1855 State 127 "PreOperational" 5 "Operational" 4 "Stopped" 0 "Bootup" ;
VAL_ 1854 State 127 "PreOperational" 5 "Operational" 4 "Stopped" 0 "Bootup" ;
VAL_ 1853 State 127 "PreOperational" 5 "Operational" 4 "Stopped" 0 "Bootup" ;
VAL_ 1852 State 127 "PreOperational" 5 "Operational" 4 "Stopped" 0 "Bootup" ;
VAL_ 1851 State 127 "PreOperational" 5 "Operational" 4 "Stopped" 0 "Bootup" ;
VAL_ 1850 State 127 "PreOperational" 5 "Operational" 4 "Stopped" 0 "Bootup" ;
VAL_ 1849 State 127 "PreOperational" 5 "Operational" 4 "Stopped" 0 "Bootup" ;
VAL_ 1848 State 127 "PreOperational" 5 "Operational" 4 "Stopped" 0 "Bootup" ;
VAL_ 1847 State 127 "PreOperational" 5 "Operational" 4 "Stopped" 0 "Bootup" ;
VAL_ 1846 State 127 "PreOperational" 5 "Operational" 4 "Stopped" 0 "Bootup" ;
VAL_ 1845 State 127 "PreOperational" 5 "Operational" 4 "Stopped" 0 "Bootup" ;
VAL_ 1844 State 127 "PreOperational" 5 "Operational" 4 "Stopped" 0 "Bootup" ;
VAL_ 1843 State 127 "PreOperational" 5 "Operational" 4 "Stopped" 0 "Bootup" ;
VAL_ 1842 State 127 "PreOperational" 5 "Operational" 4 "Stopped" 0 "Bootup" ;
VAL_ 1841 State 127 "PreOperational" 5 "Operational" 4 "Stopped" 0 "Bootup" ;
VAL_ 1840 State 127 "PreOperational" 5 "Operational" 4 "Stopped" 0 "Bootup" ;
VAL_ 1839 State 127 "PreOperational" 5 "Operational" 4 "Stopped" 0 "Bootup" ;
VAL_ 1838 State 127 "PreOperational" 5 "Operational" 4 "Stopped" 0 "Bootup" ;
VAL_ 1837 State 127 "PreOperational" 5 "Operational" 4 "Stopped" 0 "Bootup" ;
VAL_ 1836 State 127 "PreOperational" 5 "Operational" 4 "Stopped" 0 "Bootup" ;
VAL_ 1835 State 127 "PreOperational" 5 "Operational" 4 "Stopped" 0 "Bootup" ;
VAL_ 1834 State 127 "PreOperational" 5 "Operational" 4 "Stopped" 0 "Bootup" ;
VAL_ 1833 State 127 "PreOperational" 5 "Operational" 4 "Stopped" 0 "Bootup" ;
VAL_ 1832 State 127 "PreOperational" 5 "Operational" 4 "Stopped" 0 "Bootup" ;
VAL_ 1831 State 127 "PreOperational" 5 "Operational" 4 "Stopped" 0 "Bootup" ;
VAL_ 1830 State 127 "PreOperational" 5 "Operational" 4 "Stopped" 0 "Bootup" ;
VAL_ 1829 State 127 "PreOperational" 5 "Operational" 4 "Stopped" 0 "Bootup" ;
VAL_ 1828 State 127 "PreOperational" 5 "Operational" 4 "Stopped" 0 "Bootup" ;
VAL_ 1827 State 127 "PreOperational" 5 "Operational" 4 "Stopped" 0 "Bootup" ;
VAL_ 1826 State 127 "PreOperational" 5 "Operational" 4 "Stopped" 0 "Bootup" ;
VAL_ 1825 State 127 "PreOperational" 5 "Operational" 4 "Stopped" 0 "Bootup" ;
VAL_ 1824 State 127 "PreOperational" 5 "Operational" 4 "Stopped" 0 "Bootup" ;
VAL_ 1823 State 127 "PreOperational" 5 "Operational" 4 "Stopped" 0 "Bootup" ;
VAL_ 1822 State 127 "PreOperational" 5 "Operational" 4 "Stopped" 0 "Bootup" ;
VAL_ 1821 State 127 "PreOperational" 5 "Operational" 4 "Stopped" 0 "Bootup" ;
VAL_ 1820 State 127 "PreOperational" 5 "Operational" 4 "Stopped" 0 "Bootup" ;
VAL_ 1819 State 127 "PreOperational" 5 "Operational" 4 "Stopped" 0 "Bootup" ;
VAL_ 1818 State 127 "PreOperational" 5 "Operational" 4 "Stopped" 0 "Bootup" ;
VAL_ 1817 State 127 "PreOperational" 5 "Operational" 4 "Stopped" 0 "Bootup" ;
VAL_ 1816 State 127 "PreOperational" 5 "Operational" 4 "Stopped" 0 "Bootup" ;
VAL_ 1815 State 127 "PreOperational" 5 "Operational" 4 "Stopped" 0 "Bootup" ;
VAL_ 1814 State 127 "PreOperational" 5 "Operational" 4 "Stopped" 0 "Bootup" ;
VAL_ 1812 State 127 "PreOperational" 5 "Operational" 4 "Stopped" 0 "Bootup" ;
VAL_ 1811 State 127 "PreOperational" 5 "Operational" 4 "Stopped" 0 "Bootup" ;
VAL_ 1810 State 127 "PreOperational" 5 "Operational" 4 "Stopped" 0 "Bootup" ;
VAL_ 1809 State 127 "PreOperational" 5 "Operational" 4 "Stopped" 0 "Bootup" ;
VAL_ 1808 State 127 "PreOperational" 5 "Operational" 4 "Stopped" 0 "Bootup" ;
VAL_ 1807 State 127 "PreOperational" 5 "Operational" 4 "Stopped" 0 "Bootup" ;
VAL_ 1806 State 127 "PreOperational" 5 "Operational" 4 "Stopped" 0 "Bootup" ;
VAL_ 1805 State 127 "PreOperational" 5 "Operational" 4 "Stopped" 0 "Bootup" ;
VAL_ 1804 State 127 "PreOperational" 5 "Operational" 4 "Stopped" 0 "Bootup" ;
VAL_ 1803 State 127 "PreOperational" 5 "Operational" 4 "Stopped" 0 "Bootup" ;
VAL_ 1801 State 127 "PreOperational" 5 "Operational" 4 "Stopped" 0 "Bootup" ;
VAL_ 1799 State 127 "PreOperational" 5 "Operational" 4 "Stopped" 0 "Bootup" ;
VAL_ 1798 State 127 "PreOperational" 5 "Operational" 4 "Stopped" 0 "Bootup" ;
VAL_ 1797 State 127 "PreOperational" 5 "Operational" 4 "Stopped" 0 "Bootup" ;
VAL_ 1796 State 127 "PreOperational" 5 "Operational" 4 "Stopped" 0 "Bootup" ;
VAL_ 1795 State 127 "PreOperational" 5 "Operational" 4 "Stopped" 0 "Bootup" ;
VAL_ 1794 State 127 "PreOperational" 5 "Operational" 4 "Stopped" 0 "Bootup" ;
VAL_ 0 Node_ID 21 "BMS_Battery_1" 10 "PVC" 8 "TMS" 1 "Inverter" 0 "All" ;
VAL_ 0 CS 130 "Reset Communication" 129 "Reset Node" 128 "Enter Pre-Operational" 2 "Stop" 1 "Start" ;
VAL_ 2021 LSS_TableIndex 8 "10" 7 "20" 6 "50" 5 "100" 4 "125" 3 "250" 2 "500" 1 "800" 0 "1000" ;
VAL_ 2021 LSS_TableSelector 0 "Std_CiA_Table" ;
VAL_ 2021 LSS_Mode 1 "Configuration" 0 "Operation" ;
VAL_ 2021 LSS_M_CS 94 "InquireNodeID" 93 "InquireSerial" 92 "InquireRevision" 91 "InquireProduct" 90 "InquireVendor" 81 "FastScan" 23 "StoreConfiguration" 21 "ActivateBitTiming" 19 "ConfigureBitTiming" 17 "ConfigureNodeID" 76 "IdentifyNonConfSlave" 75 "IdentifySerialHigh" 74 "IdentifySerialLow" 73 "IdentifyRevisionHigh" 72 "IdentifyRevisionLow" 71 "IdentifyProduct" 70 "IdentifyVendor" 67 "SwitchModeSelectSerial" 66 "SwitchModeSelectRevision" 65 "SwitchModeSelectProduct" 64 "SwitchModeSelectVendor" 4 "SwitchModeGlobal" ;
VAL_ 2020 LSS_StoreCfg_ErrCode 255 "Impl_spec_error" 2 "Storage_media_access_error" 1 "Not_supported" 0 "Success" ;
VAL_ 2020 LSS_CfgBitTim_ErrCode 255 "Impl_spec_error" 1 "Not_supported" 0 "Success" ;
VAL_ 2020 LSS_CfgNodeID_ErrCode 255 "Impl_spec_error" 1 "NodeID_Out_Of_Range" 0 "Success" ;
VAL_ 2020 LSS_S_CS 94 "InquireNodeID" 93 "InquireSerial" 92 "InquireRevision" 91 "InquireProduct" 90 "InquireVendor" 76 "IdentifyNonConfSlave" 79 "IdentifySlave" 23 "StoreConfiguration" 19 "ConfigureBitTiming" 17 "ConfigureNodeID" 68 "SwitchModeSelectConfirm" ;
VAL_ 394 Statusword 7 "FORWARD_DISABLE" 6 "CONT_CLOSE" 5 "CONT_OPEN" 4 "DISCHARGE" 3 "PRECHARGE" 2 "ESTOPWAIT" 1 "MC_ON" 0 "MC_OFF" ;
VAL_ 394 I_O_status 9 "forwardStatus" 8 "apmStatus" 7 "contStatus" 6 "dcStatus" 5 "pcStatus" 4 "eStopStatus" 3 "batteryTwoOkStatus" 2 "batteryOneOKStatus" 1 "stoStatus" 0 "keyStatus" ;
